VERSION ""

NS_ :

BS_:

BU_: TM

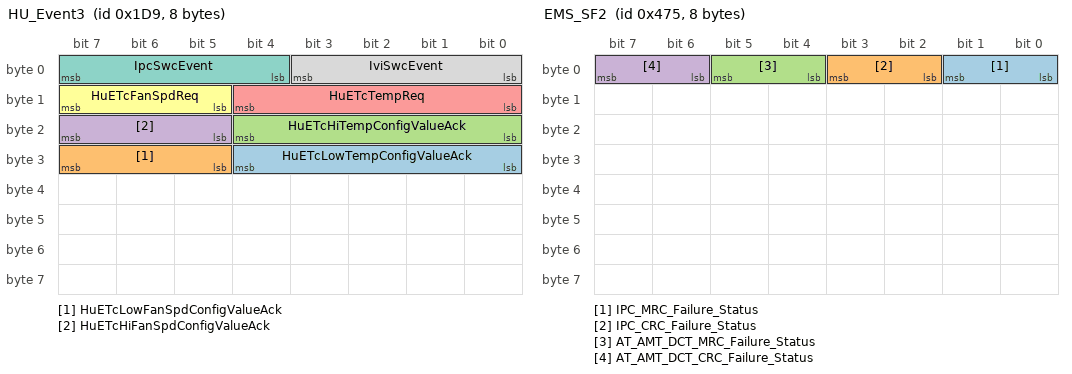
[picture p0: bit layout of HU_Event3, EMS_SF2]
BO_ 473 HU_Event3: 8 Vector__XXX
 SG_ HuETcLowTempConfigValueAck : 28|5@0+ (1,0) [0|31] ""  TM
 SG_ HuETcLowFanSpdConfigValueAck : 31|3@0+ (1,0) [0|7] ""  TM
 SG_ HuETcHiTempConfigValueAck : 20|5@0+ (1,0) [0|31] ""  TM
 SG_ HuETcHiFanSpdConfigValueAck : 23|3@0+ (1,0) [0|7] ""  TM
 SG_ HuETcTempReq : 12|5@0+ (1,0) [0|31] ""  TM
 SG_ HuETcFanSpdReq : 15|3@0+ (1,0) [0|7] ""  TM
 SG_ IpcSwcEvent : 7|4@0+ (1,0) [0|15] ""  TM
 SG_ IviSwcEvent : 3|4@0+ (1,0) [0|15] ""  TM

BO_ 1141 EMS_SF2: 8 Vector__XXX
 SG_ IPC_MRC_Failure_Status : 1|2@0+ (1,0) [0|3] ""  TM
 SG_ IPC_CRC_Failure_Status : 3|2@0+ (1,0) [0|3] ""  TM
 SG_ AT_AMT_DCT_MRC_Failure_Status : 5|2@0+ (1,0) [0|3] ""  TM
 SG_ AT_AMT_DCT_CRC_Failure_Status : 7|2@0+ (1,0) [0|3] ""  TM

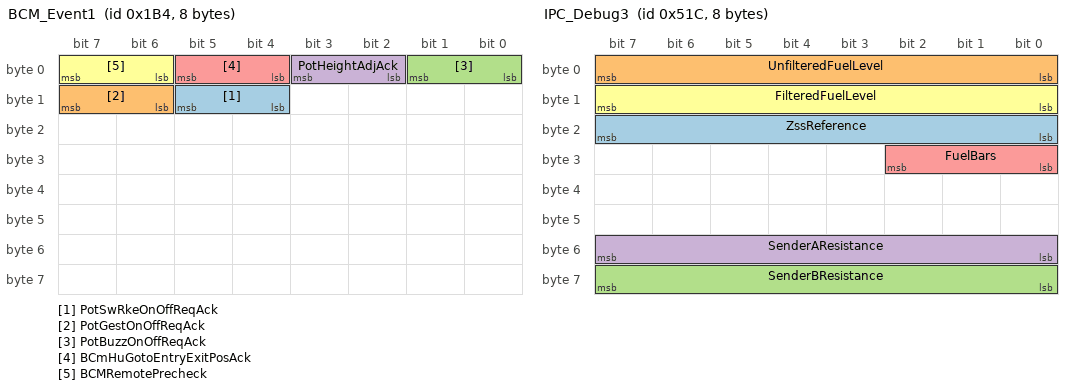
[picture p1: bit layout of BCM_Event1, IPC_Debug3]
BO_ 436 BCM_Event1: 8 Vector__XXX
 SG_ PotSwRkeOnOffReqAck : 13|2@0+ (1,0) [0|3] ""  TM
 SG_ PotGestOnOffReqAck : 15|2@0+ (1,0) [0|3] ""  TM
 SG_ PotBuzzOnOffReqAck : 1|2@0+ (1,0) [0|3] ""  TM
 SG_ PotHeightAdjAck : 3|2@0+ (1,0) [0|3] ""  TM
 SG_ BCmHuGotoEntryExitPosAck : 5|2@0+ (1,0) [0|3] ""  TM
 SG_ BCMRemotePrecheck : 7|2@0+ (1,0) [0|3] ""  TM

BO_ 1308 IPC_Debug3: 8 Vector__XXX
 SG_ ZssReference : 23|8@0+ (1,0) [0|255] "FLPS"  TM
 SG_ UnfilteredFuelLevel : 7|8@0+ (1,0) [0|255] "FLPS"  TM
 SG_ SenderBResistance : 63|8@0+ (1,0) [0|255] "Ohms"  TM
 SG_ SenderAResistance : 55|8@0+ (1,0) [0|255] "Ohms"  TM
 SG_ FuelBars : 26|3@0+ (1,0) [0|7] "NA"  TM
 SG_ FilteredFuelLevel : 15|8@0+ (1,0) [0|255] "FLPS"  TM

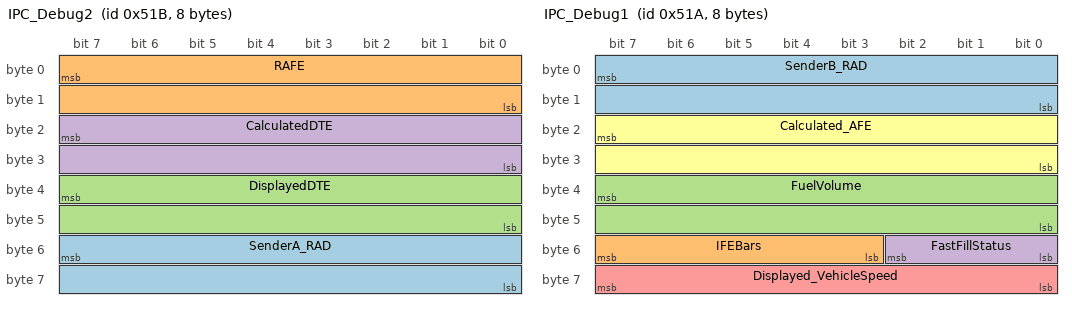
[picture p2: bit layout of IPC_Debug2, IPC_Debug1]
BO_ 1307 IPC_Debug2: 8 Vector__XXX
 SG_ SenderA_RAD : 55|16@0+ (1,0) [0|65535] "RAD"  TM
 SG_ RAFE : 7|16@0+ (0.1,0) [0|65535.5] "KM/L"  TM
 SG_ DisplayedDTE : 39|16@0+ (1,0) [0|65535] "KM"  TM
 SG_ CalculatedDTE : 23|16@0+ (1,0) [0|65535] "KM"  TM

BO_ 1306 IPC_Debug1: 8 Vector__XXX
 SG_ SenderB_RAD : 7|16@0+ (1,0) [0|65535] "RAD"  TM
 SG_ IFEBars : 55|5@0+ (1,0) [0|31] "Bars"  TM
 SG_ FuelVolume : 39|16@0+ (0.1,0) [0|65535.5] "L"  TM
 SG_ FastFillStatus : 50|3@0+ (1,0) [0|7] "Flag"  TM
 SG_ Displayed_VehicleSpeed : 63|8@0+ (1,0) [0|255] "Kmph"  TM
 SG_ Calculated_AFE : 23|16@0+ (0.1,0) [0|65535.5] "km/l"  TM

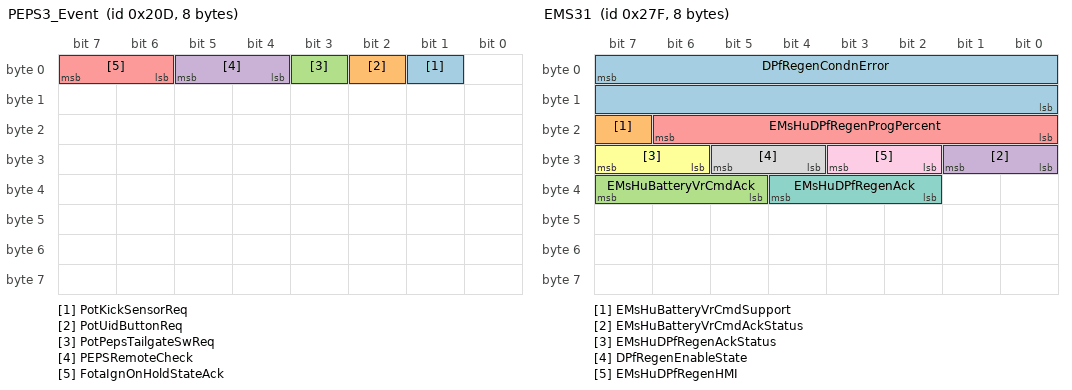
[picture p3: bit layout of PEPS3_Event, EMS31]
BO_ 525 PEPS3_Event: 8 Vector__XXX
 SG_ PotKickSensorReq : 1|1@0+ (1,0) [0|1] ""  TM
 SG_ PotUidButtonReq : 2|1@0+ (1,0) [0|1] ""  TM
 SG_ PotPepsTailgateSwReq : 3|1@0+ (1,0) [0|1] ""  TM
 SG_ PEPSRemoteCheck : 5|2@0+ (1,0) [0|3] ""  TM
 SG_ FotaIgnOnHoldStateAck : 7|2@0+ (1,0) [0|3] ""  TM

BO_ 639 EMS31: 8 Vector__XXX
 SG_ DPfRegenCondnError : 7|16@0+ (1,0) [0|16] ""  TM
 SG_ EMsHuBatteryVrCmdSupport : 23|1@0+ (1,0) [0|1] ""  TM
 SG_ EMsHuBatteryVrCmdAck : 39|3@0+ (1,0) [0|7] ""  TM
 SG_ EMsHuBatteryVrCmdAckStatus : 25|2@0+ (1,0) [0|3] ""  TM
 SG_ EMsHuDPfRegenProgPercent : 22|7@0+ (1,0) [0|100] "%"  TM
 SG_ EMsHuDPfRegenAckStatus : 31|2@0+ (1,0) [0|3] ""  TM
 SG_ EMsHuDPfRegenAck : 36|3@0+ (1,0) [0|7] ""  TM
 SG_ DPfRegenEnableState : 29|2@0+ (1,0) [0|3] ""  TM
 SG_ EMsHuDPfRegenHMI : 27|2@0+ (1,0) [0|3] ""  TM

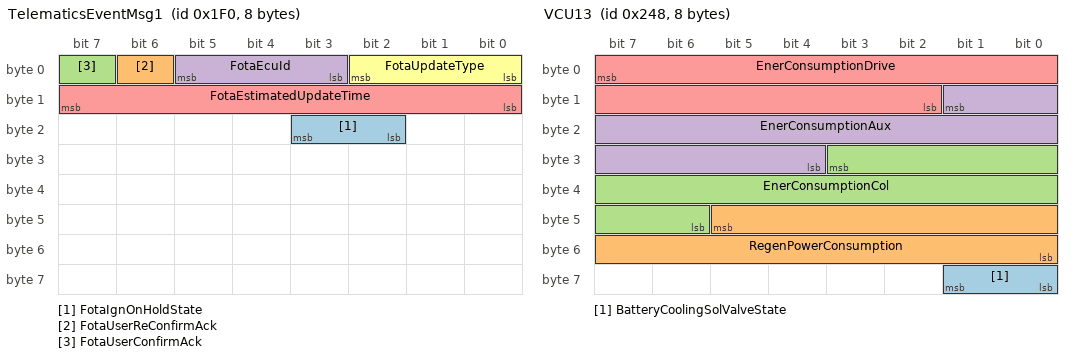
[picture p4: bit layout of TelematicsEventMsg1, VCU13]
BO_ 496 TelematicsEventMsg1: 8 TM
 SG_ FotaIgnOnHoldState : 19|2@0+ (1,0) [0|3] "" Vector__XXX
 SG_ FotaUserReConfirmAck : 6|1@0+ (1,0) [0|1] "" Vector__XXX
 SG_ FotaUserConfirmAck : 7|1@0+ (1,0) [0|1] "" Vector__XXX
 SG_ FotaEcuId : 5|3@0+ (1,0) [0|7] "" Vector__XXX
 SG_ FotaEstimatedUpdateTime : 15|8@0+ (1,0) [0|255] "" Vector__XXX
 SG_ FotaUpdateType : 2|3@0+ (1,0) [0|7] "" Vector__XXX

BO_ 1123 Telematics_TP: 8 TM
 SG_ TcmHuVoiceCommandData : 7|64@0+ (1,0) [0|0] "" Vector__XXX

BO_ 1122 HU_TP: 8 Vector__XXX
 SG_ HuTcmVoiceCommandDataAck : 7|64@0+ (1,0) [0|0] ""  TM

BO_ 584 VCU13: 8 Vector__XXX
 SG_ BatteryCoolingSolValveState : 57|2@0+ (1,0) [0|3] ""  TM
 SG_ RegenPowerConsumption : 45|14@0+ (0.01,0) [0|150] ""  TM
 SG_ EnerConsumptionCol : 27|14@0+ (0.01,0) [0|150] ""  TM
 SG_ EnerConsumptionAux : 9|14@0+ (0.01,0) [0|150] ""  TM
 SG_ EnerConsumptionDrive : 7|14@0+ (0.01,0) [0|150] ""  TM

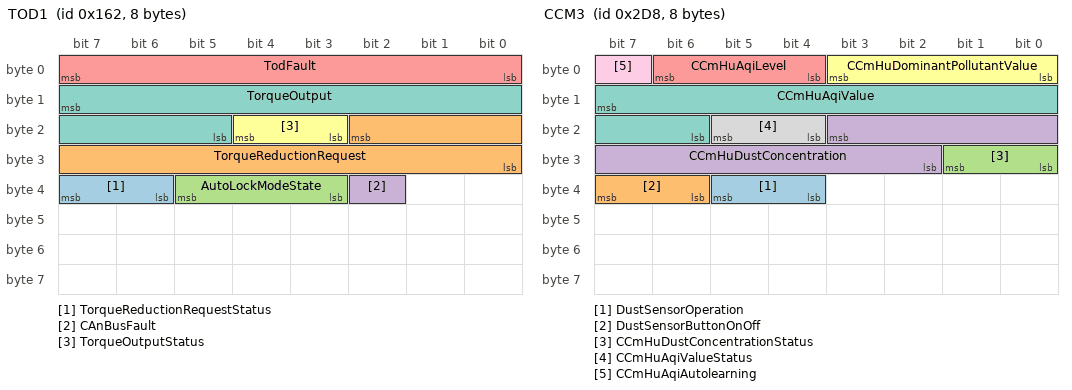
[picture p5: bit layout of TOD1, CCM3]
BO_ 354 TOD1: 8 Vector__XXX
 SG_ TorqueReductionRequestStatus : 39|2@0+ (1,0) [0|3] ""  TM
 SG_ TorqueReductionRequest : 18|11@0+ (1,0) [0|2047] "Nm"  TM
 SG_ AutoLockModeState : 37|3@0+ (1,0) [0|7] ""  TM
 SG_ CAnBusFault : 34|1@0+ (1,0) [0|1] ""  TM
 SG_ TodFault : 7|8@0+ (1,0) [0|255] ""  TM
 SG_ TorqueOutputStatus : 20|2@0+ (1,0) [0|3] ""  TM
 SG_ TorqueOutput : 15|11@0+ (1,0) [0|2047] "Nm"  TM

BO_ 1592 GSS_DiagResponse_UUDT: 8 Vector__XXX
 SG_ GSS_DiagResponse_UUDT : 7|64@0+ (1,0) [0|0] ""  TM

BO_ 1848 GSS_DiagResponse_USDT: 8 Vector__XXX
 SG_ GSS_DiagResponse_USDT : 7|64@0+ (1,0) [0|0] ""  TM

BO_ 1840 GSS_DiagRequest: 8 Vector__XXX
 SG_ GSS_DiagRequest : 7|64@0+ (1,0) [0|0] ""  TM

BO_ 728 CCM3: 8 Vector__XXX
 SG_ DustSensorOperation : 37|2@0+ (1,0) [0|3] ""  TM
 SG_ DustSensorButtonOnOff : 39|2@0+ (1,0) [0|3] ""  TM
 SG_ CCmHuDustConcentrationStatus : 25|2@0+ (1,0) [0|3] ""  TM
 SG_ CCmHuDustConcentration : 19|10@0+ (1,0) [0|1023] ""  TM
 SG_ CCmHuAqiLevel : 6|3@0+ (1,0) [0|7] ""  TM
 SG_ CCmHuDominantPollutantValue : 3|4@0+ (1,0) [0|15] ""  TM
 SG_ CCmHuAqiValue : 15|10@0+ (1,0) [0|1023] ""  TM
 SG_ CCmHuAqiValueStatus : 21|2@0+ (1,0) [0|3] ""  TM
 SG_ CCmHuAqiAutolearning : 7|1@0+ (1,0) [0|1] ""  TM

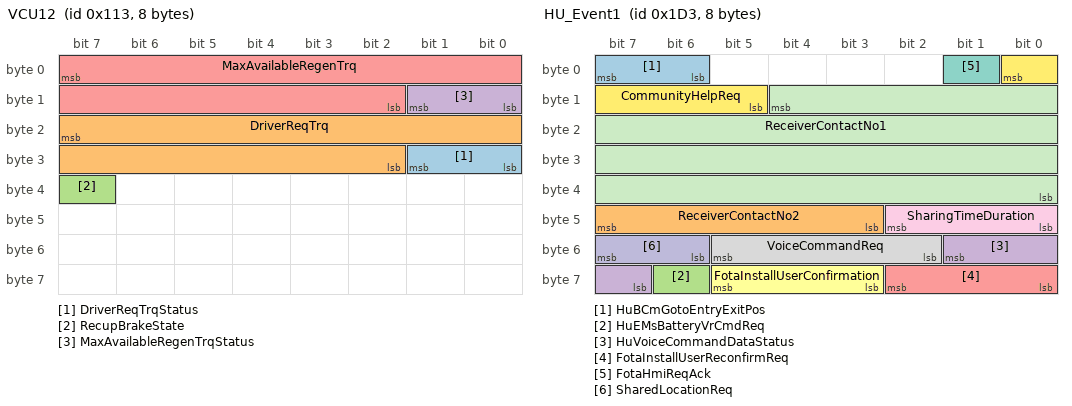
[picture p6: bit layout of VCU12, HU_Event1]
BO_ 275 VCU12: 8 Vector__XXX
 SG_ DriverReqTrqStatus : 25|2@0+ (1,0) [0|3] ""  TM
 SG_ DriverReqTrq : 23|14@0+ (0.25,-2048) [-2048|2047.75] ""  TM
 SG_ RecupBrakeState : 39|1@0+ (1,0) [0|1] ""  TM
 SG_ MaxAvailableRegenTrqStatus : 9|2@0+ (1,0) [0|3] ""  TM
 SG_ MaxAvailableRegenTrq : 7|14@0+ (0.25,-2048) [-2048|2047.75] ""  TM

BO_ 736 Remote_Feature1: 8 Vector__XXX
 SG_ VehicleMobilizationStateStatus : 7|2@0+ (1,0) [0|3] ""  TM
 SG_ VehicleMobilizationState : 5|2@0+ (1,0) [0|3] ""  TM

BO_ 467 HU_Event1: 8 Vector__XXX
 SG_ HuBCmGotoEntryExitPos : 7|2@0+ (1,0) [0|3] ""  TM
 SG_ ReceiverContactNo2 : 47|5@0+ (1,0) [0|31] ""  TM
 SG_ HuEMsBatteryVrCmdReq : 62|1@0+ (1,0) [0|1] ""  TM
 SG_ HuVoiceCommandDataStatus : 49|3@0+ (1,0) [0|7] ""  TM
 SG_ FotaInstallUserReconfirmReq : 58|3@0+ (1,0) [0|7] ""  TM
 SG_ FotaInstallUserConfirmation : 61|3@0+ (1,0) [0|7] ""  TM
 SG_ FotaHmiReqAck : 1|1@0+ (1,0) [0|1] ""  TM
 SG_ VoiceCommandReq : 53|4@0+ (1,0) [0|15] ""  TM
 SG_ SharingTimeDuration : 42|3@0+ (1,0) [0|7] ""  TM
 SG_ SharedLocationReq : 55|2@0+ (1,0) [0|3] ""  TM
 SG_ ReceiverContactNo1 : 12|29@0+ (1,0) [0|536870911] ""  TM
 SG_ CommunityHelpReq : 0|4@0+ (1,0) [0|15] ""  TM

BO_ 583 VCU10_RC: 8 Vector__XXX
 SG_ CruiseSwitchStateVCUStatus : 1|2@0+ (1,0) [0|3] ""  TM
 SG_ CruiseSwitchStateVCU : 3|2@0+ (1,0) [0|3] ""  TM
 SG_ VcuModeSelectionChangeTxt : 53|2@0+ (1,0) [0|3] ""  TM
 SG_ ModeForDisplayVCUStatus : 47|2@0+ (1,0) [0|3] ""  TM
 SG_ ModeForDisplayVCU : 37|3@0+ (1,0) [0|7] ""  TM
 SG_ ModeSelectionSwStateVCUStatus : 16|3@0+ (1,0) [0|7] ""  TM
 SG_ ModeSelectionSwStateVCU : 29|3@0+ (1,0) [0|7] ""  TM
 SG_ VcuRegenSelectionChangeTxt : 55|2@0+ (1,0) [0|3] ""  TM
 SG_ RegenForDisplayVCUStatus : 45|2@0+ (1,0) [0|3] ""  TM
 SG_ RegenForDisplayVCU : 34|3@0+ (1,0) [0|7] ""  TM
 SG_ VcuCruiseSelectionChangeTxt : 43|4@0+ (1,0) [0|15] ""  TM
 SG_ DesiredCruiseSpeedStatus : 49|2@0+ (1,0) [0|3] ""  TM
 SG_ DesiredCruiseSpeed : 63|8@0+ (1,0) [0|255] ""  TM
 SG_ VCuCruiseStateStatus : 39|2@0+ (1,0) [0|3] ""  TM
 SG_ VCuCruiseState : 26|3@0+ (1,0) [0|7] ""  TM
 SG_ HvBattFullChargeStatus : 7|2@0+ (1,0) [0|3] ""  TM
 SG_ HvBattFullCharge : 5|1@0+ (1,0) [0|1] ""  TM

BO_ 741 Telematics1: 8 TM
 SG_ RemoteAcPvTempSetStatus : 57|2@0+ (1,0) [0|3] "" Vector__XXX
 SG_ RemoteAcPvTempSet : 62|5@0+ (1,0) [0|31] "" Vector__XXX
 SG_ VehicleChargingStateTCM : 48|2@0+ (1,0) [0|3] "" Vector__XXX
 SG_ RemoteEngAcCmdStatus : 50|2@0+ (1,0) [0|3] "" Vector__XXX
 SG_ RemoteEngAcCmd : 52|2@0+ (1,0) [0|3] "" Vector__XXX
 SG_ TCmPresence : 53|1@0+ (1,0) [0|1] "" Vector__XXX
 SG_ VcuFotaUpdateState : 41|2@0+ (1,0) [0|3] "" Vector__XXX
 SG_ FatcFotaUpdateState : 43|2@0+ (1,0) [0|3] "" Vector__XXX
 SG_ BcmFotaUpdateState : 55|2@0+ (1,0) [0|3] "" Vector__XXX
 SG_ FotaUpdateEcuProgressPercen : 31|8@0+ (1,0) [0|100] "%" Vector__XXX
 SG_ FotaUpdateOverallProgressPercen : 39|8@0+ (1,0) [0|100] "%" Vector__XXX
 SG_ ParkBrkStateTcm : 17|2@0+ (1,0) [0|3] "" Vector__XXX
 SG_ GearPosStateTcm : 11|2@0+ (1,0) [0|3] "" Vector__XXX
 SG_ LvBattVoltStateTcm : 19|2@0+ (1,0) [0|3] "" Vector__XXX
 SG_ EngRpmStateTcm : 21|2@0+ (1,0) [0|3] "" Vector__XXX
 SG_ VehSpdStateTcm : 9|2@0+ (1,0) [0|3] "" Vector__XXX
 SG_ IgnStateTcm : 23|2@0+ (1,0) [0|3] "" Vector__XXX
 SG_ AccPedalPosStateTcm : 13|2@0+ (1,0) [0|3] "" Vector__XXX
 SG_ FotaUpdateState : 47|4@0+ (1,0) [0|15] "" Vector__XXX
 SG_ ShareMyLocationFeaturePresence : 14|1@0+ (1,0) [0|1] "" Vector__XXX
 SG_ iCallFeaturePresence : 1|1@0+ (1,0) [0|1] "" Vector__XXX
 SG_ eCallFeaturePresence : 2|1@0+ (1,0) [0|1] "" Vector__XXX
 SG_ CvpVoiceCmdFeaturePresence : 15|1@0+ (1,0) [0|1] "" Vector__XXX
 SG_ CommunityHelpFeaturePresence : 0|1@0+ (1,0) [0|1] "" Vector__XXX
 SG_ CallType : 5|2@0+ (1,0) [0|3] "" Vector__XXX
 SG_ CallState : 7|2@0+ (1,0) [0|3] "" Vector__XXX
 SG_ bCallFeaturePresence : 3|1@0+ (1,0) [0|1] "" Vector__XXX

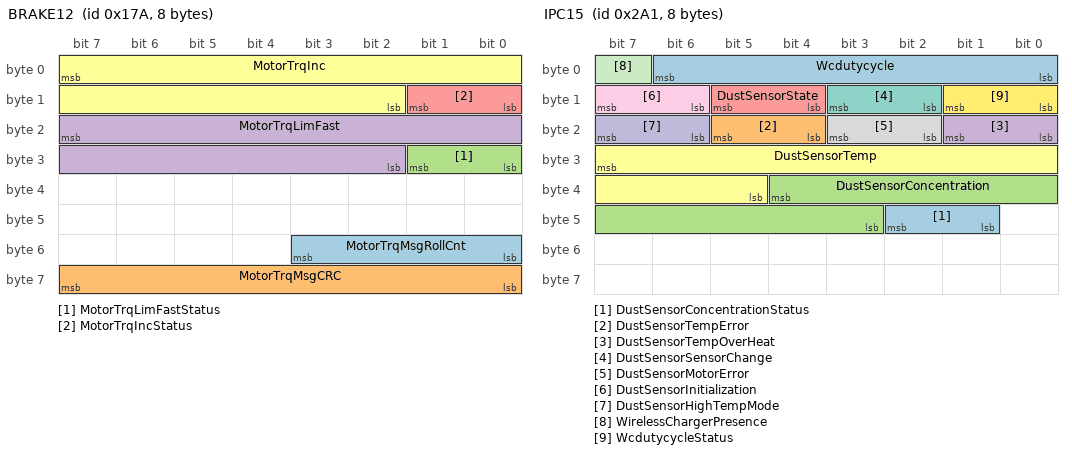
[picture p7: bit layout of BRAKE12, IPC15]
BO_ 378 BRAKE12: 8 Vector__XXX
 SG_ MotorTrqMsgRollCnt : 51|4@0+ (1,0) [0|15] ""  TM
 SG_ MotorTrqMsgCRC : 63|8@0+ (1,0) [0|255] ""  TM
 SG_ MotorTrqLimFastStatus : 25|2@0+ (1,0) [0|3] ""  TM
 SG_ MotorTrqLimFast : 23|14@0+ (0.1,-500) [-500|500] "Nm"  TM
 SG_ MotorTrqIncStatus : 9|2@0+ (1,0) [0|3] ""  TM
 SG_ MotorTrqInc : 7|14@0+ (0.1,-500) [-500|500] "Nm"  TM

BO_ 673 IPC15: 8 Vector__XXX
 SG_ DustSensorConcentrationStatus : 42|2@0+ (1,0) [0|3] ""  TM
 SG_ DustSensorTempError : 21|2@0+ (1,0) [0|3] ""  TM
 SG_ DustSensorConcentration : 36|10@0+ (1,0) [0|1023] ""  TM
 SG_ DustSensorTempOverHeat : 17|2@0+ (1,0) [0|3] ""  TM
 SG_ DustSensorState : 13|2@0+ (1,0) [0|3] ""  TM
 SG_ DustSensorTemp : 31|11@0+ (0.1,-40) [-40|164.7] ""  TM
 SG_ DustSensorSensorChange : 11|2@0+ (1,0) [0|3] ""  TM
 SG_ DustSensorMotorError : 19|2@0+ (1,0) [0|3] ""  TM
 SG_ DustSensorInitialization : 15|2@0+ (1,0) [0|3] ""  TM
 SG_ DustSensorHighTempMode : 23|2@0+ (1,0) [0|3] ""  TM
 SG_ WirelessChargerPresence : 7|1@0+ (1,0) [0|1] ""  TM
 SG_ WcdutycycleStatus : 9|2@0+ (1,0) [0|3] ""  TM
 SG_ Wcdutycycle : 6|7@0+ (1,0) [0|100] "%"  TM

BO_ 491 HU_VrCmd_SupportAck: 8 Vector__XXX
 SG_ HuBCmWindowWindingHmiCmdSupportA : 23|1@0+ (1,0) [0|1] ""  TM
 SG_ HuBCmTyreTempVrCmdSupportAck : 8|1@0+ (1,0) [0|1] ""  TM
 SG_ HuBCmTyreTempHmiCmdSupportAck : 9|1@0+ (1,0) [0|1] ""  TM
 SG_ HuBCmTyrePressureVrCmdSupportAck : 10|1@0+ (1,0) [0|1] ""  TM
 SG_ HuBCmTyrePressureHmiCmdSupportAc : 11|1@0+ (1,0) [0|1] ""  TM
 SG_ HuBCmSunroofTiltVrCmdSupportAck : 12|1@0+ (1,0) [0|1] ""  TM
 SG_ HuBCmRoofLampVrCmdSupportAck : 13|1@0+ (1,0) [0|1] ""  TM
 SG_ HuBCmRoofLampHmiCmdSupportAck : 14|1@0+ (1,0) [0|1] ""  TM
 SG_ HuBCmPositionLampVrCmdSupportAck : 15|1@0+ (1,0) [0|1] ""  TM
 SG_ HuBCmORVMVrCmdSupportAck : 2|1@0+ (1,0) [0|1] ""  TM
 SG_ HuBCmORVMHmiCmdSupportAck : 3|1@0+ (1,0) [0|1] ""  TM
 SG_ HuBCmMoodLightVrCmdSupportAck : 4|1@0+ (1,0) [0|1] ""  TM
 SG_ HuBCmHazardLampVrCmdSupportAck : 5|1@0+ (1,0) [0|1] ""  TM
 SG_ HuBCmDRLVrCmdSupportAck : 6|1@0+ (1,0) [0|1] ""  TM
 SG_ HuBCmAmbientLightVrCmdSupportAck : 7|1@0+ (1,0) [0|1] ""  TM
 SG_ HuBCmSunShadeVrCmdSupportAck : 1|1@0+ (1,0) [0|1] ""  TM
 SG_ HuBCmSunRoofVrCmdSupportAck : 0|1@0+ (1,0) [0|1] ""  TM

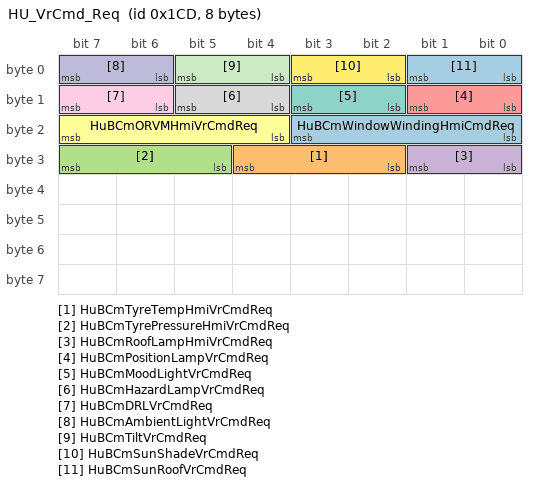
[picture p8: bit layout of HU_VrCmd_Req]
BO_ 461 HU_VrCmd_Req: 8 Vector__XXX
 SG_ HuBCmWindowWindingHmiCmdReq : 19|4@0+ (1,0) [0|15] ""  TM
 SG_ HuBCmTyreTempHmiVrCmdReq : 28|3@0+ (1,0) [0|7] ""  TM
 SG_ HuBCmTyrePressureHmiVrCmdReq : 31|3@0+ (1,0) [0|7] ""  TM
 SG_ HuBCmRoofLampHmiVrCmdReq : 25|2@0+ (1,0) [0|3] ""  TM
 SG_ HuBCmPositionLampVrCmdReq : 9|2@0+ (1,0) [0|3] ""  TM
 SG_ HuBCmORVMHmiVrCmdReq : 23|4@0+ (1,0) [0|15] ""  TM
 SG_ HuBCmMoodLightVrCmdReq : 11|2@0+ (1,0) [0|3] ""  TM
 SG_ HuBCmHazardLampVrCmdReq : 13|2@0+ (1,0) [0|3] ""  TM
 SG_ HuBCmDRLVrCmdReq : 15|2@0+ (1,0) [0|3] ""  TM
 SG_ HuBCmAmbientLightVrCmdReq : 7|2@0+ (1,0) [0|3] ""  TM
 SG_ HuBCmTiltVrCmdReq : 5|2@0+ (1,0) [0|3] ""  TM
 SG_ HuBCmSunShadeVrCmdReq : 3|2@0+ (1,0) [0|3] ""  TM
 SG_ HuBCmSunRoofVrCmdReq : 1|2@0+ (1,0) [0|3] ""  TM

BO_ 489 BCM_VrCmd_Support: 8 Vector__XXX
 SG_ BCmHuWindowWindingHmiCmdSupport : 23|1@0+ (1,0) [0|1] ""  TM
 SG_ BCmHuTyreTempVrCmdSupport : 8|1@0+ (1,0) [0|1] ""  TM
 SG_ BCmHuTyreTempHmiCmdSupport : 9|1@0+ (1,0) [0|1] ""  TM
 SG_ BCmHuTyrePressureVrCmdSupport : 10|1@0+ (1,0) [0|1] ""  TM
 SG_ BCmHuTyrePressureHmiCmdSupport : 11|1@0+ (1,0) [0|1] ""  TM
 SG_ BCmHuSunroofTiltVrCmdSupport : 12|1@0+ (1,0) [0|1] ""  TM
 SG_ BCmHuRoofLampVrCmdSupport : 13|1@0+ (1,0) [0|1] ""  TM
 SG_ BCmHuRoofLampHmiCmdSupport : 14|1@0+ (1,0) [0|1] ""  TM
 SG_ BCmHuPositionLampVrCmdSupport : 15|1@0+ (1,0) [0|1] ""  TM
 SG_ BCmHuORVMVrCmdSupport : 2|1@0+ (1,0) [0|1] ""  TM
 SG_ BCmHuORVMHmiCmdSupport : 3|1@0+ (1,0) [0|1] ""  TM
 SG_ BCmHuMoodLightVrCmdSupport : 4|1@0+ (1,0) [0|1] ""  TM
 SG_ BCmHuHazardLampVrCmdSupport : 5|1@0+ (1,0) [0|1] ""  TM
 SG_ BCmHuDRLVrCmdSupport : 6|1@0+ (1,0) [0|1] ""  TM
 SG_ BCmHuAmbientLightVrCmdSupport : 7|1@0+ (1,0) [0|1] ""  TM
 SG_ BCmHuSunShadeVrCmdSupport : 1|1@0+ (1,0) [0|1] ""  TM
 SG_ BCmHuSunRoofVrCmdSupport : 0|1@0+ (1,0) [0|1] ""  TM

CM_ SG_ 473 HuETcLowTempConfigValueAck "Acknowledge  the lower configuration set Temperature value for the ETC ECU under consideration";
CM_ SG_ 473 HuETcLowFanSpdConfigValueAck "Acknowledge  the lower configuration fan speed value for the ETC ECU under consideration";
CM_ SG_ 473 HuETcHiTempConfigValueAck "Acknowledge  the higher configuration set Temperature value for the ETC ECU under consideration";
CM_ SG_ 473 HuETcHiFanSpdConfigValueAck "Acknowledge  the higher configuration fan speed value for the ETC ECU under consideration";
CM_ SG_ 473 HuETcTempReq "Indicates the Set temperature value from HU in Levels";
CM_ SG_ 473 HuETcFanSpdReq "Indicates the Fan spped request value from HU in Levels";
CM_ SG_ 473 IpcSwcEvent "LinSwcIc shall publish its variant type to all partner ECUs.";
CM_ SG_ 473 IviSwcEvent "LinSwcIc shall publish its variant type to all partner ECUs.";
CM_ BO_ 1141 "Supervision frame transmitted by EMS.";
CM_ SG_ 1141 IPC_MRC_Failure_Status "Status of the message rolling counter failure detected by EMS ECU as per communication layer spec";
CM_ SG_ 1141 IPC_CRC_Failure_Status "Status of the cyclic reduntancy failure detected by EMS ECU as per communication layer spec.";
CM_ SG_ 1141 AT_AMT_DCT_MRC_Failure_Status "Status of the message rolling counter failure detected by EMS ECU as per communication layer spec";
CM_ SG_ 1141 AT_AMT_DCT_CRC_Failure_Status "Status of the cyclic reduntancy failure detected by EMS ECU as per communication layer spec.";
CM_ SG_ 436 PotSwRkeOnOffReqAck "ACK BCM to HU for POT open/close by RKE switch enable/ disable user req";
CM_ SG_ 436 PotGestOnOffReqAck "ACK BCM to HU for POT open/close by gesture enable/ disable user req";
CM_ SG_ 436 PotBuzzOnOffReqAck "ACK BCM to HU for POT buzzer of open/close action enable/ disable user req";
CM_ SG_ 436 PotHeightAdjAck "BCM Ack for POT height adj from HU";
CM_ SG_ 436 BCmHuGotoEntryExitPosAck "BCM Ack for Easy Entry/Exit Enable or Disable from HU";
CM_ SG_ 436 BCMRemotePrecheck "BCM shall publish the  door status to TCM & PEPS";
CM_ SG_ 525 PotKickSensorReq "Power Tailgate Open/Close request from Kick Sensor";
CM_ SG_ 525 PotUidButtonReq "Power Tailgate Open/Close request from UID Button";
CM_ SG_ 525 PotPepsTailgateSwReq "Power Tailgate Open/Close request from PEPS Tailgate Switch";
CM_ SG_ 525 PEPSRemoteCheck "PEPS shall publish  precheck status to TCM";
CM_ SG_ 525 FotaIgnOnHoldStateAck "Acknowledgement Signal from PEPS to TCM for confirming the reception of  the FotaIgnOnHoldState signal  ";
CM_ SG_ 639 DPfRegenCondnError "This information is transmitted by EMS to HU to notify the error / interupts causing pre-condition check failure or DPF regeneration process abortion.
Refer Functional Description Document for Bit Encoded Value.";
CM_ SG_ 639 EMsHuBatteryVrCmdSupport "This signal is used to indicate whether EMS supports voice recognition feature related to battery parameters.";
CM_ SG_ 639 EMsHuBatteryVrCmdAck "This information is used to request battery status via VR command.This information is used to send acknowledgement for battery status request via VR command.";
CM_ SG_ 639 EMsHuBatteryVrCmdAckStatus "This signal is used to indicate plausibility of batetry status acknowledgement signal.";
CM_ SG_ 639 EMsHuDPfRegenProgPercent "The information is sent from EMS to HU to display the progress percentage & progress Bar for DPF regeneration process.";
CM_ SG_ 639 EMsHuDPfRegenAckStatus "This signal is used to indicate plausibility status of DPF regeneration acknowldgement signal.";
CM_ SG_ 639 EMsHuDPfRegenAck "This signal is used to indicate the response / acknowledgement from EMS for DPF regeneration request.";
CM_ SG_ 639 DPfRegenEnableState "This signal is used by HU to push notification on HMI for DPF regeneration.";
CM_ SG_ 639 EMsHuDPfRegenHMI "This signal is used to indicate whether EMS supports  DPF regeneration through HMI or Not";
CM_ SG_ 496 FotaIgnOnHoldState "Signal  from TCM to PEPS for requesting to hold Ignition in ON state";
CM_ SG_ 496 FotaUserReConfirmAck "Acknowledgement signal to HU to intimate that TCU has received the FOTA user re-confirmation signal that it has sent";
CM_ SG_ 496 FotaUserConfirmAck "Acknowledgement signal to HU to intimate that TCU has received the FOTA user confirmation signal that it has sent";
CM_ SG_ 496 FotaEcuId "This signal shall be published by TCU to indicate the ID of the ECUfo which the upgrade or installation is planned";
CM_ SG_ 496 FotaEstimatedUpdateTime "This signal shall be published by TCU to indicate approximate estimated time for installatioon of new firmware";
CM_ SG_ 496 FotaUpdateType "This signal shall be published by TCU to indicate the FOTA Update Type of the new firnware to be installed";
CM_ BO_ 1123 "Telematics CAN TP Message";
CM_ BO_ 1122 "HU CAN TP Message";
CM_ SG_ 584 BatteryCoolingSolValveState "Battery Cooling Solenoid Valve Signal";
CM_ SG_ 584 RegenPowerConsumption "Regen Power Consumption";
CM_ SG_ 584 EnerConsumptionCol "Energy Consumption Cooling";
CM_ SG_ 584 EnerConsumptionAux "Energy Consumption Auxilary";
CM_ SG_ 584 EnerConsumptionDrive "Energy Consumption Drive ";
CM_ SG_ 354 TorqueReductionRequestStatus "Status of torque reduction request  to engine";
CM_ SG_ 354 TorqueReductionRequest "Torque reduction request  to engine";
CM_ SG_ 354 AutoLockModeState "AUTO Or LOCK Mode status over CAN (to IC )";
CM_ SG_ 354 CAnBusFault "Indication in case of malfunction over CAN (to IC)";
CM_ SG_ 354 TodFault "Internal Fault Code";
CM_ SG_ 354 TorqueOutputStatus "Output torque from NexTrac status";
CM_ SG_ 354 TorqueOutput "Output torque from NexTrac";
CM_ SG_ 728 DustSensorOperation "Sensor operation permission signal by FATC.";
CM_ SG_ 728 DustSensorButtonOnOff "This signal is used to make Sensor on and OFF by FATC";
CM_ SG_ 728 CCmHuDustConcentrationStatus "Satus for Dust Concentration.";
CM_ SG_ 728 CCmHuDustConcentration "Dust concentration signal is used to measure the concentration level in ug/m3_ PM2.5 Value";
CM_ SG_ 728 CCmHuAqiLevel "AQI Level – used for color indication w.r.t  AQI_Based on Value AQI value the color codes to be assigned. AQI Value to be mapped with respective colour codes.";
CM_ SG_ 728 CCmHuDominantPollutantValue "This value express the concentration of major pollutant inside the cabin";
CM_ SG_ 728 CCmHuAqiValue "AQI value information";
CM_ SG_ 728 CCmHuAqiValueStatus "Plausibility Satus for CCmHuAQIValue";
CM_ SG_ 728 CCmHuAqiAutolearning "This signal will be used by HU to determine whether said feature is available or not";
CM_ SG_ 275 DriverReqTrqStatus "Driver requested torque status";
CM_ SG_ 275 DriverReqTrq "Driver requested torque";
CM_ SG_ 275 RecupBrakeState "Recupration brake Enable Flag";
CM_ SG_ 275 MaxAvailableRegenTrqStatus "Status information of MaxAvailableRegenTrq Signal";
CM_ SG_ 275 MaxAvailableRegenTrq "Actual available regen torque at VCU";
CM_ SG_ 736 VehicleMobilizationStateStatus "Status of the VehicleMobilizationState signal";
CM_ SG_ 736 VehicleMobilizationState "Vehicle Mobilization and immobilization  response to prevent vehicle crank";
CM_ SG_ 467 HuBCmGotoEntryExitPos "Easy Entry Exit function User request to Enable or Disable Feature";
CM_ SG_ 467 ReceiverContactNo2 "Signal for receiver contact number";
CM_ SG_ 467 HuEMsBatteryVrCmdReq "This information is used to request battery status via VR command.";
CM_ SG_ 467 HuVoiceCommandDataStatus "Voice command data status from HU to TCM";
CM_ SG_ 467 FotaInstallUserReconfirmReq "Signal containing the FOTA re-installation user confirmation input ";
CM_ SG_ 467 FotaInstallUserConfirmation "Signal containing the FOTA installation user confirmation input ";
CM_ SG_ 467 FotaHmiReqAck "Acknowledgement signal to TCU to intimate that HU has received the FOTA update type, estimated time and ECU ID signals that it has sent";
CM_ SG_ 467 VoiceCommandReq "Voice command Request from HU to TCM";
CM_ SG_ 467 SharingTimeDuration "Signal from Community Help receviers's TCM to receiver's HU to inform  the Community help request to Receiver.";
CM_ SG_ 467 SharedLocationReq "Signal from HU to TCM for Share My Location request";
CM_ SG_ 467 ReceiverContactNo1 "Signal for receiver contact number";
CM_ SG_ 467 CommunityHelpReq "Signal from Community Help sender's HU to sender's TCM to generate  the Community help request on platform.";
CM_ SG_ 583 CruiseSwitchStateVCUStatus "CruiseSwitchstate Signal status information";
CM_ SG_ 583 CruiseSwitchStateVCU "Resume and Set Cruise Switches stateinformation to support HDC function";
CM_ SG_ 583 VcuModeSelectionChangeTxt "Signal on CAN to IPC for possibility of user requested change status.";
CM_ SG_ 583 ModeForDisplayVCUStatus "Plausibility Status of ModeForDisplayVCU";
CM_ SG_ 583 ModeForDisplayVCU "Mode Selection Switch signal (Validated User request) is published by VCU for response Mode Selection";
CM_ SG_ 583 ModeSelectionSwStateVCUStatus "Plausibility Status of ModeSelectionSwState";
CM_ SG_ 583 ModeSelectionSwStateVCU "Mode Selection Display signal is published by VCU for ESP confirmation of Mode Selection request from user";
CM_ SG_ 583 VcuRegenSelectionChangeTxt "This function indicates Regen Level Selection Cluster Indication";
CM_ SG_ 583 RegenForDisplayVCUStatus "Plausibility Status of Regen Level Display on cluster";
CM_ SG_ 583 RegenForDisplayVCU "Regen Level Display on cluster";
CM_ SG_ 583 VcuCruiseSelectionChangeTxt "This function indicates Cruise Selection Cluster Indication";
CM_ SG_ 583 DesiredCruiseSpeedStatus "It indicate the cruise info status";
CM_ SG_ 583 DesiredCruiseSpeed "This information is used   to indicate the speed limit values in display";
CM_ SG_ 583 VCuCruiseStateStatus "status information to CruiseState";
CM_ SG_ 583 VCuCruiseState "Cruise control active / Cruise control failed";
CM_ SG_ 583 HvBattFullChargeStatus "Status of the HV Battery Full Charge alert";
CM_ SG_ 583 HvBattFullCharge "HV Battery Full Charge alert";
CM_ SG_ 741 RemoteAcPvTempSetStatus "Status of the RemoteAcPvTempSet signal as published by TCU.";
CM_ SG_ 741 RemoteAcPvTempSet "Set temperature value from TCU to FATC for in-cabin climate control.";
CM_ SG_ 741 VehicleChargingStateTCM "The signal shall be published by the TCU to intimate HU to indicate whether the Charging state is in safe condition (Not charging) in the display";
CM_ SG_ 741 RemoteEngAcCmdStatus "This signal gives status of RemoteEngAcCmdStatus signal.";
CM_ SG_ 741 RemoteEngAcCmd "After waking up ESCL by PEPS, TCM should send RemoteEngAcCmd on CAN (Cyclic) to BCM, PEPS, IPC, & FATC.";
CM_ SG_ 741 TCmPresence "Indicates the state of the TCM presence to other ECU.";
CM_ SG_ 741 VcuFotaUpdateState "Signal Indicating the current FOTA Update State of VCU from TCM to HU";
CM_ SG_ 741 FatcFotaUpdateState "Signal Indicating the current FOTA Update State of FATC from TCM to HU";
CM_ SG_ 741 BcmFotaUpdateState "Signal Indicating the current FOTA Update State of BCM from TCM to HU";
CM_ SG_ 741 FotaUpdateEcuProgressPercen "Signal with percentage completion value of the FOTA Update of current ECU from TCM to HU";
CM_ SG_ 741 FotaUpdateOverallProgressPercen "Signal with overall percentage completion value of the FOTA update from TCM to HU";
CM_ SG_ 741 ParkBrkStateTcm "The signal shall be published by the TCU to intimate HU to indicate whether the ParkBrake status is in safe condition in the display";
CM_ SG_ 741 GearPosStateTcm "The signal shall be published by the TCU to intimate HU to indicate whether the Gear Position status is in safe condition (Neutral - 3) in the display";
CM_ SG_ 741 LvBattVoltStateTcm "The signal shall be published by the TCU to intimate HU to indicate whether the current LV battery voltage is in safe condition (LV Battery Voltage == between 10-16V) in the display";
CM_ SG_ 741 EngRpmStateTcm "The signal shall be published by the TCU to intimate HU to indicate whether the current Engine RPM status is in safe condition (Engine RPM == 0) in the display";
CM_ SG_ 741 VehSpdStateTcm "The signal shall be published by the TCU to intimate HU to indicate whether the current Vehicle Speed  status is in safe condition (Vehicle Speed == 0) in the display";
CM_ SG_ 741 IgnStateTcm "The signal shall be published by the TCU to intimate HU to indicate whether the IGN status is in safe condition (IGN_ON) in the display";
CM_ SG_ 741 AccPedalPosStateTcm "The signal shall be published by the TCU to intimate HU to indicate whether the Accelerator Pedal Position is in safe condition (0%) in the display";
CM_ SG_ 741 FotaUpdateState "This signal shall be published by TCU to indicate the current state of the FOTA installation to the corresponding ECUs in the vehicle network";
CM_ SG_ 741 ShareMyLocationFeaturePresence "Signal transmitted from TCM to HU, indicating the presence of Share My Location feature";
CM_ SG_ 741 iCallFeaturePresence "This signal is transmitted from TCM to HU, indicating that iCall feature is present or not";
CM_ SG_ 741 eCallFeaturePresence "This signal is transmitted from TCM to HU, indicating that eCall feature is present or not";
CM_ SG_ 741 CvpVoiceCmdFeaturePresence "This signal is transmitted from TCM to HU, indicating that voice recognition feature is present or not";
CM_ SG_ 741 CommunityHelpFeaturePresence "TCM to HU, indicating Community Help feature is present or not";
CM_ SG_ 741 CallType "This signal is transmitted from TCM to HU, indicating type of call";
CM_ SG_ 741 CallState "This signal is transmitted from TCM to HU, indicating  status of call";
CM_ SG_ 741 bCallFeaturePresence "This signal is transmitted from TCM to HU, indicating that bCall feature is present or not";
CM_ SG_ 378 MotorTrqMsgRollCnt "Rolling counter for the message which consists of MotorTrqInc, MototrTrqLimFast";
CM_ SG_ 378 MotorTrqMsgCRC "CRC for entire message which consists of MotorTrqInc, MototrTrqLimFast";
CM_ SG_ 378 MotorTrqLimFastStatus "status information of EngTrqLimFast
";
CM_ SG_ 378 MotorTrqLimFast "target engine torque limit (fast) in NM.
Signal will be used by VCU ECU for ESP/TCS function from ESP
";
CM_ SG_ 378 MotorTrqIncStatus "Status signal information of MotorTrqInc
";
CM_ SG_ 378 MotorTrqInc "Target Motor torque increases in Nm.
Signal will be used by VCU ECU for ESP/TCS function from  ESP
";
CM_ SG_ 673 DustSensorConcentrationStatus "Status of dust sensor concentration";
CM_ SG_ 673 DustSensorTempError "Transmit Sensor Temp error signal";
CM_ SG_ 673 DustSensorConcentration "Concentration of dust";
CM_ SG_ 673 DustSensorTempOverHeat "Transmit Sensor over-temp signal ";
CM_ SG_ 673 DustSensorState "Transmit dust Sensor state signal ";
CM_ SG_ 673 DustSensorTemp "Internal Sensor Temperature";
CM_ SG_ 673 DustSensorSensorChange "Transmit Sensor Replace signal ";
CM_ SG_ 673 DustSensorMotorError "Transmit Fan Motor error signal ";
CM_ SG_ 673 DustSensorInitialization "Transmit initialization signal of Dust Sensor ";
CM_ SG_ 673 DustSensorHighTempMode "Transmit High temp operating mode signal";
CM_ SG_ 673 WirelessChargerPresence "This signal is transmitted to HU to know wireless charger is presence in vehicle or not.";
CM_ SG_ 673 WcdutycycleStatus "This information is used to determine status of duty cycle of PWM sent by wireless charger";
CM_ SG_ 673 Wcdutycycle "This information is used to determine the duty cycle of PWM sent by wireless charger";
CM_ SG_ 491 HuBCmWindowWindingHmiCmdSupportA "Window Winding HMI support response from HU to BCM";
CM_ SG_ 491 HuBCmTyreTempVrCmdSupportAck "Tyre Temparature Voice support response from HU to BCM";
CM_ SG_ 491 HuBCmTyreTempHmiCmdSupportAck "Tyre Temparature HMI support response from HU to BCM";
CM_ SG_ 491 HuBCmTyrePressureVrCmdSupportAck "Tyre Pressure Voice support response from HU to BCM";
CM_ SG_ 491 HuBCmTyrePressureHmiCmdSupportAc "Tyre Pressure HMI support response from HU to BCM";
CM_ SG_ 491 HuBCmSunroofTiltVrCmdSupportAck "Sunroof Tilt voice support response from HU to BCM";
CM_ SG_ 491 HuBCmRoofLampVrCmdSupportAck "Roof Lamp Voice support response from HU to BCM";
CM_ SG_ 491 HuBCmRoofLampHmiCmdSupportAck "Roof Lamp HMI support response from HU to BCM";
CM_ SG_ 491 HuBCmPositionLampVrCmdSupportAck "Position lamp voice support response from HU to BCM";
CM_ SG_ 491 HuBCmORVMVrCmdSupportAck "ORVM voice support response from HU to BCM";
CM_ SG_ 491 HuBCmORVMHmiCmdSupportAck "ORVM HMI support response from HU to BCM";
CM_ SG_ 491 HuBCmMoodLightVrCmdSupportAck "Mood Light voice support response from HU to BCM";
CM_ SG_ 491 HuBCmHazardLampVrCmdSupportAck "Hazard Lamp voice support response from HU to BCM";
CM_ SG_ 491 HuBCmDRLVrCmdSupportAck "DRL voice support response from HU to BCM";
CM_ SG_ 491 HuBCmAmbientLightVrCmdSupportAck "Ambient Light voice support response from HU to BCM";
CM_ SG_ 491 HuBCmSunShadeVrCmdSupportAck "Sunshade operation support from HU to BCM";
CM_ SG_ 491 HuBCmSunRoofVrCmdSupportAck "Sunroof operation support from HU to BCM";
CM_ SG_ 461 HuBCmWindowWindingHmiCmdReq "Window Winding voice command request from HU to BCM";
CM_ SG_ 461 HuBCmTyreTempHmiVrCmdReq "Tyre Temperature HMI or voice command request from HU to BCM";
CM_ SG_ 461 HuBCmTyrePressureHmiVrCmdReq "Tyre Pressure HMI or voice command request from HU to BCM";
CM_ SG_ 461 HuBCmRoofLampHmiVrCmdReq "Roof lamp HMI or Voice command request from HU to BCM";
CM_ SG_ 461 HuBCmPositionLampVrCmdReq "Position lamp voice command request from HU to BCM";
CM_ SG_ 461 HuBCmORVMHmiVrCmdReq "ORVM HMI or Voice command request from HU to BCM";
CM_ SG_ 461 HuBCmMoodLightVrCmdReq "Mood light voice command request from HU to BCM";
CM_ SG_ 461 HuBCmHazardLampVrCmdReq "Hazard lamp voice command request from HU to BCM";
CM_ SG_ 461 HuBCmDRLVrCmdReq "DRL voice command request from HU to BCM";
CM_ SG_ 461 HuBCmAmbientLightVrCmdReq "Ambient light voice command request from HU to BCM";
CM_ SG_ 461 HuBCmTiltVrCmdReq "Sunroof Tilt voice command command request from HU to BCM";
CM_ SG_ 461 HuBCmSunShadeVrCmdReq "Sunshade voice command request from HU to BCM";
CM_ SG_ 461 HuBCmSunRoofVrCmdReq "Sunroof voice command command request from HU to BCM";
CM_ SG_ 489 BCmHuWindowWindingHmiCmdSupport "Window Winding HMI support from BCM to HU";
CM_ SG_ 489 BCmHuTyreTempVrCmdSupport "Tyre Temparature Voice support from BCM to HU";
CM_ SG_ 489 BCmHuTyreTempHmiCmdSupport "Tyre Temparature HMI support from BCM to HU";
CM_ SG_ 489 BCmHuTyrePressureVrCmdSupport "Tyre Pressure Voice support from BCM to HU";
CM_ SG_ 489 BCmHuTyrePressureHmiCmdSupport "Tyre Pressure HMI support from BCM to HU";
CM_ SG_ 489 BCmHuSunroofTiltVrCmdSupport "Sunroof Tilt voice support from BCM to HU";
CM_ SG_ 489 BCmHuRoofLampVrCmdSupport "Roof Lamp Voice support from BCM to HU";
CM_ SG_ 489 BCmHuRoofLampHmiCmdSupport "Roof Lamp HMI support from BCM to HU";
CM_ SG_ 489 BCmHuPositionLampVrCmdSupport "Position lamp voice support from BCM to HU";
CM_ SG_ 489 BCmHuORVMVrCmdSupport "ORVM Voice support from BCM to HU";
CM_ SG_ 489 BCmHuORVMHmiCmdSupport "ORVM HMI support from BCM to HU";
CM_ SG_ 489 BCmHuMoodLightVrCmdSupport "Mood Light voice support from BCM to HU";
CM_ SG_ 489 BCmHuHazardLampVrCmdSupport "Hazard Lamp voice support from BCM to HU";
CM_ SG_ 489 BCmHuDRLVrCmdSupport "DRL voice support from BCM to HU";
CM_ SG_ 489 BCmHuAmbientLightVrCmdSupport "Ambient Light voice support from BCM to HU";
CM_ SG_ 489 BCmHuSunShadeVrCmdSupport "Sunshade operation support from BCM to HU";
CM_ SG_ 489 BCmHuSunRoofVrCmdSupport "Sunroof operation support from BCM to HU";
BA_DEF_ SG_  "Remarks" STRING ;
BA_DEF_ SG_  "NWM_WakeupAllowed" ENUM  "No","Yes";
BA_DEF_ SG_  "GenSigTimeoutTime_HU_Mid_X451" INT 0 65535;
BA_DEF_ SG_  "GenSigTimeoutTime_HU_High_X451" INT 0 65535;
BA_DEF_ SG_  "GenSigTimeoutTime_HU_B" INT 0 65535;
BA_DEF_ SG_  "GenSigTimeoutTime_HU_A" INT 0 65535;
BA_DEF_ SG_  "GenSigTimeoutTime_BCM_Mid" INT 0 65535;
BA_DEF_ SG_  "GenSigTimeoutMsg_HU_Mid_X451" INT 0 65535;
BA_DEF_ SG_  "GenSigTimeoutMsg_HU_High_X451" INT 0 65535;
BA_DEF_ SG_  "GenSigTimeoutMsg_HU_B" INT 0 65535;
BA_DEF_ SG_  "GenSigTimeoutMsg_HU_A" INT 0 65535;
BA_DEF_ SG_  "GenSigStartValue" INT 0 0;
BA_DEF_ SG_  "GenSigSendType" ENUM  "Cyclic","OnWrite","OnWriteWithRepetition","OnChange","OnChangeWithRepetition","IfActive","IfActiveWithRepetition","NoSigSendType","NotUsed","NotUsed","NotUsed","NotUsed","NotUsed";
BA_DEF_ SG_  "GenSigInactiveValue" INT 0 0;
BA_DEF_ SG_  "GenSigEnvVarType" ENUM  "int","float","undef";
BA_DEF_ SG_  "GenSigCycleTimeActive" INT 0 0;
BA_DEF_ SG_  "GenSigCycleTime" INT 0 0;
BA_DEF_ SG_  "GenSigTimeoutMsg_HU_High_X445" INT 0 65535;
BA_DEF_ SG_  "GenSigTimeoutMsg_HU_Mid_X445" INT 0 65535;
BA_DEF_ SG_  "GenSigTimeoutTime_HU_High_X445" INT 0 65535;
BA_DEF_ SG_  "GenSigTimeoutTime_HU_Mid_X445" INT 0 65535;
BA_DEF_ SG_  "GenSigTimeoutMsg_IVI" INT 0 65535;
BA_DEF_ SG_  "GenSigTimeoutTime_IVI" INT 0 65535;
BA_DEF_ BO_  "NmMessage" ENUM  "no","yes";
BA_DEF_ BO_  "NmAsrMessage" ENUM  "<n.a.>","No","Yes";
BA_DEF_ BO_  "MessageTimeout" INT 0 65535;
BA_DEF_ BO_  "Me" INT 0 0;
BA_DEF_ BO_  "GenMsgStartDelayTime" INT 0 0;
BA_DEF_ BO_  "GenMsgSendType" ENUM  "Cyclic","NotUsed","NotUsed","NotUsed","NotUsed","NotUsed","NotUsed","IfActive","NoMsgSendType","NotUsed";
BA_DEF_ BO_  "GenMsgNrOfRepetition" INT 0 0;
BA_DEF_ BO_  "GenMsgILSupport" ENUM  "No","Yes";
BA_DEF_ BO_  "GenMsgDelayTime" INT 0 0;
BA_DEF_ BO_  "GenMsgCycleTimeFast" INT 0 0;
BA_DEF_ BO_  "GenMsgCycleTime" INT 0 0;
BA_DEF_ BO_  "DiagUudtResponse" ENUM  "false","true";
BA_DEF_ BO_  "DiagUsdtResponse" ENUM  "false","true";
BA_DEF_ BO_  "DiagState" ENUM  "No","Yes";
BA_DEF_ BO_  "DiagResponse" ENUM  "No","Yes";
BA_DEF_ BO_  "DiagRequest" ENUM  "No","Yes";
BA_DEF_ BO_  "MsgType" ENUM  "Application","NM","NMH";
BA_DEF_ SG_  "SystemSignalLongSymbol" STRING ;
BA_DEF_DEF_  "Remarks" "null";
BA_DEF_DEF_  "NWM_WakeupAllowed" "No";
BA_DEF_DEF_  "GenSigTimeoutTime_HU_Mid_X451" 500;
BA_DEF_DEF_  "GenSigTimeoutTime_HU_High_X451" 500;
BA_DEF_DEF_  "GenSigTimeoutTime_HU_B" 500;
BA_DEF_DEF_  "GenSigTimeoutTime_HU_A" 500;
BA_DEF_DEF_  "GenSigTimeoutTime_BCM_Mid" 0;
BA_DEF_DEF_  "GenSigTimeoutMsg_HU_Mid_X451" 500;
BA_DEF_DEF_  "GenSigTimeoutMsg_HU_High_X451" 500;
BA_DEF_DEF_  "GenSigTimeoutMsg_HU_B" 500;
BA_DEF_DEF_  "GenSigTimeoutMsg_HU_A" 500;
BA_DEF_DEF_  "GenSigStartValue" 0;
BA_DEF_DEF_  "GenSigSendType" "Cyclic";
BA_DEF_DEF_  "GenSigInactiveValue" 0;
BA_DEF_DEF_  "GenSigEnvVarType" "undef";
BA_DEF_DEF_  "GenSigCycleTimeActive" 0;
BA_DEF_DEF_  "GenSigCycleTime" 0;
BA_DEF_DEF_  "GenSigTimeoutMsg_HU_High_X445" 500;
BA_DEF_DEF_  "GenSigTimeoutMsg_HU_Mid_X445" 500;
BA_DEF_DEF_  "GenSigTimeoutTime_HU_High_X445" 500;
BA_DEF_DEF_  "GenSigTimeoutTime_HU_Mid_X445" 500;
BA_DEF_DEF_  "GenSigTimeoutMsg_IVI" 500;
BA_DEF_DEF_  "GenSigTimeoutTime_IVI" 500;
BA_DEF_DEF_  "NmMessage" "no";
BA_DEF_DEF_  "NmAsrMessage" "<n.a.>";
BA_DEF_DEF_  "MessageTimeout" 500;
BA_DEF_DEF_  "Me" 0;
BA_DEF_DEF_  "GenMsgStartDelayTime" 0;
BA_DEF_DEF_  "GenMsgSendType" "Cyclic";
BA_DEF_DEF_  "GenMsgNrOfRepetition" 0;
BA_DEF_DEF_  "GenMsgILSupport" "Yes";
BA_DEF_DEF_  "GenMsgDelayTime" 0;
BA_DEF_DEF_  "GenMsgCycleTimeFast" 0;
BA_DEF_DEF_  "GenMsgCycleTime" 0;
BA_DEF_DEF_  "DiagUudtResponse" "false";
BA_DEF_DEF_  "DiagUsdtResponse" "false";
BA_DEF_DEF_  "DiagState" "No";
BA_DEF_DEF_  "DiagResponse" "No";
BA_DEF_DEF_  "DiagRequest" "No";
BA_DEF_DEF_  "MsgType" "Application";
BA_DEF_DEF_  "SystemSignalLongSymbol" "";
BA_ "MessageTimeout" BO_ 473 0;
BA_ "GenMsgSendType" BO_ 473 8;
BA_ "GenMsgNrOfRepetition" BO_ 473 3;
BA_ "GenMsgDelayTime" BO_ 473 200;
BA_ "GenMsgCycleTimeFast" BO_ 473 200;
BA_ "MessageTimeout" BO_ 1141 0;
BA_ "GenMsgStartDelayTime" BO_ 1141 24;
BA_ "GenMsgCycleTime" BO_ 1141 100;
BA_ "MessageTimeout" BO_ 436 0;
BA_ "GenMsgSendType" BO_ 436 8;
BA_ "GenMsgNrOfRepetition" BO_ 436 3;
BA_ "GenMsgDelayTime" BO_ 436 500;
BA_ "GenMsgCycleTimeFast" BO_ 436 500;
BA_ "GenMsgCycleTime" BO_ 1308 100;
BA_ "GenMsgCycleTime" BO_ 1307 100;
BA_ "GenMsgCycleTime" BO_ 1306 100;
BA_ "MessageTimeout" BO_ 525 0;
BA_ "GenMsgSendType" BO_ 525 8;
BA_ "GenMsgNrOfRepetition" BO_ 525 5;
BA_ "GenMsgDelayTime" BO_ 525 100;
BA_ "GenMsgCycleTimeFast" BO_ 525 100;
BA_ "GenMsgCycleTime" BO_ 639 100;
BA_ "MessageTimeout" BO_ 496 0;
BA_ "GenMsgSendType" BO_ 496 8;
BA_ "GenMsgNrOfRepetition" BO_ 496 3;
BA_ "GenMsgDelayTime" BO_ 496 100;
BA_ "GenMsgCycleTimeFast" BO_ 496 100;
BA_ "MessageTimeout" BO_ 1123 0;
BA_ "GenMsgSendType" BO_ 1123 8;
BA_ "MessageTimeout" BO_ 1122 0;
BA_ "GenMsgSendType" BO_ 1122 8;
BA_ "GenMsgCycleTime" BO_ 584 100;
BA_ "GenMsgCycleTime" BO_ 354 20;
BA_ "MessageTimeout" BO_ 1592 0;
BA_ "GenMsgSendType" BO_ 1592 8;
BA_ "GenMsgILSupport" BO_ 1592 0;
BA_ "DiagResponse" BO_ 1592 1;
BA_ "MessageTimeout" BO_ 1848 0;
BA_ "GenMsgSendType" BO_ 1848 8;
BA_ "GenMsgILSupport" BO_ 1848 0;
BA_ "DiagResponse" BO_ 1848 1;
BA_ "MessageTimeout" BO_ 1840 0;
BA_ "GenMsgSendType" BO_ 1840 8;
BA_ "GenMsgILSupport" BO_ 1840 0;
BA_ "DiagRequest" BO_ 1840 1;
BA_ "GenMsgCycleTime" BO_ 728 100;
BA_ "GenMsgCycleTime" BO_ 275 10;
BA_ "GenMsgCycleTime" BO_ 736 100;
BA_ "MessageTimeout" BO_ 467 0;
BA_ "GenMsgSendType" BO_ 467 8;
BA_ "GenMsgNrOfRepetition" BO_ 467 3;
BA_ "GenMsgDelayTime" BO_ 467 200;
BA_ "GenMsgCycleTimeFast" BO_ 467 200;
BA_ "GenMsgCycleTime" BO_ 583 100;
BA_ "GenMsgCycleTime" BO_ 741 100;
BA_ "GenMsgCycleTime" BO_ 378 20;
BA_ "GenMsgCycleTime" BO_ 673 100;
BA_ "MessageTimeout" BO_ 491 0;
BA_ "GenMsgSendType" BO_ 491 8;
BA_ "GenMsgNrOfRepetition" BO_ 491 3;
BA_ "GenMsgDelayTime" BO_ 491 500;
BA_ "GenMsgCycleTimeFast" BO_ 491 500;
BA_ "MessageTimeout" BO_ 461 0;
BA_ "GenMsgSendType" BO_ 461 8;
BA_ "GenMsgNrOfRepetition" BO_ 461 3;
BA_ "GenMsgDelayTime" BO_ 461 500;
BA_ "GenMsgCycleTimeFast" BO_ 461 500;
BA_ "MessageTimeout" BO_ 489 0;
BA_ "GenMsgSendType" BO_ 489 8;
BA_ "GenMsgNrOfRepetition" BO_ 489 3;
BA_ "GenMsgDelayTime" BO_ 489 500;
BA_ "GenMsgCycleTimeFast" BO_ 489 500;
BA_ "GenSigTimeoutTime_HU_Mid_X451" SG_ 473 HuETcLowTempConfigValueAck 0;
BA_ "GenSigTimeoutTime_HU_High_X451" SG_ 473 HuETcLowTempConfigValueAck 0;
BA_ "GenSigTimeoutTime_HU_B" SG_ 473 HuETcLowTempConfigValueAck 0;
BA_ "GenSigTimeoutTime_HU_A" SG_ 473 HuETcLowTempConfigValueAck 0;
BA_ "GenSigTimeoutMsg_HU_Mid_X451" SG_ 473 HuETcLowTempConfigValueAck 0;
BA_ "GenSigTimeoutMsg_HU_High_X451" SG_ 473 HuETcLowTempConfigValueAck 0;
BA_ "GenSigTimeoutMsg_HU_B" SG_ 473 HuETcLowTempConfigValueAck 0;
BA_ "GenSigTimeoutMsg_HU_A" SG_ 473 HuETcLowTempConfigValueAck 0;
BA_ "GenSigSendType" SG_ 473 HuETcLowTempConfigValueAck 2;
BA_ "GenSigTimeoutMsg_HU_High_X445" SG_ 473 HuETcLowTempConfigValueAck 0;
BA_ "GenSigTimeoutMsg_HU_Mid_X445" SG_ 473 HuETcLowTempConfigValueAck 0;
BA_ "GenSigTimeoutTime_HU_High_X445" SG_ 473 HuETcLowTempConfigValueAck 0;
BA_ "GenSigTimeoutTime_HU_Mid_X445" SG_ 473 HuETcLowTempConfigValueAck 0;
BA_ "GenSigTimeoutMsg_IVI" SG_ 473 HuETcLowTempConfigValueAck 0;
BA_ "GenSigTimeoutTime_IVI" SG_ 473 HuETcLowTempConfigValueAck 0;
BA_ "GenSigTimeoutTime_HU_Mid_X451" SG_ 473 HuETcLowFanSpdConfigValueAck 0;
BA_ "GenSigTimeoutTime_HU_High_X451" SG_ 473 HuETcLowFanSpdConfigValueAck 0;
BA_ "GenSigTimeoutTime_HU_B" SG_ 473 HuETcLowFanSpdConfigValueAck 0;
BA_ "GenSigTimeoutTime_HU_A" SG_ 473 HuETcLowFanSpdConfigValueAck 0;
BA_ "GenSigTimeoutMsg_HU_Mid_X451" SG_ 473 HuETcLowFanSpdConfigValueAck 0;
BA_ "GenSigTimeoutMsg_HU_High_X451" SG_ 473 HuETcLowFanSpdConfigValueAck 0;
BA_ "GenSigTimeoutMsg_HU_B" SG_ 473 HuETcLowFanSpdConfigValueAck 0;
BA_ "GenSigTimeoutMsg_HU_A" SG_ 473 HuETcLowFanSpdConfigValueAck 0;
BA_ "GenSigSendType" SG_ 473 HuETcLowFanSpdConfigValueAck 2;
BA_ "GenSigTimeoutMsg_HU_High_X445" SG_ 473 HuETcLowFanSpdConfigValueAck 0;
BA_ "GenSigTimeoutMsg_HU_Mid_X445" SG_ 473 HuETcLowFanSpdConfigValueAck 0;
BA_ "GenSigTimeoutTime_HU_High_X445" SG_ 473 HuETcLowFanSpdConfigValueAck 0;
BA_ "GenSigTimeoutTime_HU_Mid_X445" SG_ 473 HuETcLowFanSpdConfigValueAck 0;
BA_ "GenSigTimeoutMsg_IVI" SG_ 473 HuETcLowFanSpdConfigValueAck 0;
BA_ "GenSigTimeoutTime_IVI" SG_ 473 HuETcLowFanSpdConfigValueAck 0;
BA_ "GenSigTimeoutTime_HU_Mid_X451" SG_ 473 HuETcHiTempConfigValueAck 0;
BA_ "GenSigTimeoutTime_HU_High_X451" SG_ 473 HuETcHiTempConfigValueAck 0;
BA_ "GenSigTimeoutTime_HU_B" SG_ 473 HuETcHiTempConfigValueAck 0;
BA_ "GenSigTimeoutTime_HU_A" SG_ 473 HuETcHiTempConfigValueAck 0;
BA_ "GenSigTimeoutMsg_HU_Mid_X451" SG_ 473 HuETcHiTempConfigValueAck 0;
BA_ "GenSigTimeoutMsg_HU_High_X451" SG_ 473 HuETcHiTempConfigValueAck 0;
BA_ "GenSigTimeoutMsg_HU_B" SG_ 473 HuETcHiTempConfigValueAck 0;
BA_ "GenSigTimeoutMsg_HU_A" SG_ 473 HuETcHiTempConfigValueAck 0;
BA_ "GenSigSendType" SG_ 473 HuETcHiTempConfigValueAck 2;
BA_ "GenSigTimeoutMsg_HU_High_X445" SG_ 473 HuETcHiTempConfigValueAck 0;
BA_ "GenSigTimeoutMsg_HU_Mid_X445" SG_ 473 HuETcHiTempConfigValueAck 0;
BA_ "GenSigTimeoutTime_HU_High_X445" SG_ 473 HuETcHiTempConfigValueAck 0;
BA_ "GenSigTimeoutTime_HU_Mid_X445" SG_ 473 HuETcHiTempConfigValueAck 0;
BA_ "GenSigTimeoutMsg_IVI" SG_ 473 HuETcHiTempConfigValueAck 0;
BA_ "GenSigTimeoutTime_IVI" SG_ 473 HuETcHiTempConfigValueAck 0;
BA_ "GenSigTimeoutTime_HU_Mid_X451" SG_ 473 HuETcHiFanSpdConfigValueAck 0;
BA_ "GenSigTimeoutTime_HU_High_X451" SG_ 473 HuETcHiFanSpdConfigValueAck 0;
BA_ "GenSigTimeoutTime_HU_B" SG_ 473 HuETcHiFanSpdConfigValueAck 0;
BA_ "GenSigTimeoutTime_HU_A" SG_ 473 HuETcHiFanSpdConfigValueAck 0;
BA_ "GenSigTimeoutMsg_HU_Mid_X451" SG_ 473 HuETcHiFanSpdConfigValueAck 0;
BA_ "GenSigTimeoutMsg_HU_High_X451" SG_ 473 HuETcHiFanSpdConfigValueAck 0;
BA_ "GenSigTimeoutMsg_HU_B" SG_ 473 HuETcHiFanSpdConfigValueAck 0;
BA_ "GenSigTimeoutMsg_HU_A" SG_ 473 HuETcHiFanSpdConfigValueAck 0;
BA_ "GenSigSendType" SG_ 473 HuETcHiFanSpdConfigValueAck 2;
BA_ "GenSigTimeoutMsg_HU_High_X445" SG_ 473 HuETcHiFanSpdConfigValueAck 0;
BA_ "GenSigTimeoutMsg_HU_Mid_X445" SG_ 473 HuETcHiFanSpdConfigValueAck 0;
BA_ "GenSigTimeoutTime_HU_High_X445" SG_ 473 HuETcHiFanSpdConfigValueAck 0;
BA_ "GenSigTimeoutTime_HU_Mid_X445" SG_ 473 HuETcHiFanSpdConfigValueAck 0;
BA_ "GenSigTimeoutMsg_IVI" SG_ 473 HuETcHiFanSpdConfigValueAck 0;
BA_ "GenSigTimeoutTime_IVI" SG_ 473 HuETcHiFanSpdConfigValueAck 0;
BA_ "GenSigTimeoutTime_HU_Mid_X451" SG_ 473 HuETcTempReq 0;
BA_ "GenSigTimeoutTime_HU_High_X451" SG_ 473 HuETcTempReq 0;
BA_ "GenSigTimeoutTime_HU_B" SG_ 473 HuETcTempReq 0;
BA_ "GenSigTimeoutTime_HU_A" SG_ 473 HuETcTempReq 0;
BA_ "GenSigTimeoutMsg_HU_Mid_X451" SG_ 473 HuETcTempReq 0;
BA_ "GenSigTimeoutMsg_HU_High_X451" SG_ 473 HuETcTempReq 0;
BA_ "GenSigTimeoutMsg_HU_B" SG_ 473 HuETcTempReq 0;
BA_ "GenSigTimeoutMsg_HU_A" SG_ 473 HuETcTempReq 0;
BA_ "GenSigSendType" SG_ 473 HuETcTempReq 2;
BA_ "GenSigTimeoutMsg_HU_High_X445" SG_ 473 HuETcTempReq 0;
BA_ "GenSigTimeoutMsg_HU_Mid_X445" SG_ 473 HuETcTempReq 0;
BA_ "GenSigTimeoutTime_HU_High_X445" SG_ 473 HuETcTempReq 0;
BA_ "GenSigTimeoutTime_HU_Mid_X445" SG_ 473 HuETcTempReq 0;
BA_ "GenSigTimeoutMsg_IVI" SG_ 473 HuETcTempReq 0;
BA_ "GenSigTimeoutTime_IVI" SG_ 473 HuETcTempReq 0;
BA_ "GenSigTimeoutTime_HU_Mid_X451" SG_ 473 HuETcFanSpdReq 0;
BA_ "GenSigTimeoutTime_HU_High_X451" SG_ 473 HuETcFanSpdReq 0;
BA_ "GenSigTimeoutTime_HU_B" SG_ 473 HuETcFanSpdReq 0;
BA_ "GenSigTimeoutTime_HU_A" SG_ 473 HuETcFanSpdReq 0;
BA_ "GenSigTimeoutMsg_HU_Mid_X451" SG_ 473 HuETcFanSpdReq 0;
BA_ "GenSigTimeoutMsg_HU_High_X451" SG_ 473 HuETcFanSpdReq 0;
BA_ "GenSigTimeoutMsg_HU_B" SG_ 473 HuETcFanSpdReq 0;
BA_ "GenSigTimeoutMsg_HU_A" SG_ 473 HuETcFanSpdReq 0;
BA_ "GenSigSendType" SG_ 473 HuETcFanSpdReq 2;
BA_ "GenSigTimeoutMsg_HU_High_X445" SG_ 473 HuETcFanSpdReq 0;
BA_ "GenSigTimeoutMsg_HU_Mid_X445" SG_ 473 HuETcFanSpdReq 0;
BA_ "GenSigTimeoutTime_HU_High_X445" SG_ 473 HuETcFanSpdReq 0;
BA_ "GenSigTimeoutTime_HU_Mid_X445" SG_ 473 HuETcFanSpdReq 0;
BA_ "GenSigTimeoutMsg_IVI" SG_ 473 HuETcFanSpdReq 0;
BA_ "GenSigTimeoutTime_IVI" SG_ 473 HuETcFanSpdReq 0;
BA_ "GenSigTimeoutTime_HU_Mid_X451" SG_ 473 IpcSwcEvent 0;
BA_ "GenSigTimeoutTime_HU_High_X451" SG_ 473 IpcSwcEvent 0;
BA_ "GenSigTimeoutTime_HU_B" SG_ 473 IpcSwcEvent 0;
BA_ "GenSigTimeoutTime_HU_A" SG_ 473 IpcSwcEvent 0;
BA_ "GenSigTimeoutMsg_HU_Mid_X451" SG_ 473 IpcSwcEvent 0;
BA_ "GenSigTimeoutMsg_HU_High_X451" SG_ 473 IpcSwcEvent 0;
BA_ "GenSigTimeoutMsg_HU_B" SG_ 473 IpcSwcEvent 0;
BA_ "GenSigTimeoutMsg_HU_A" SG_ 473 IpcSwcEvent 0;
BA_ "GenSigSendType" SG_ 473 IpcSwcEvent 2;
BA_ "GenSigTimeoutMsg_HU_High_X445" SG_ 473 IpcSwcEvent 0;
BA_ "GenSigTimeoutMsg_HU_Mid_X445" SG_ 473 IpcSwcEvent 0;
BA_ "GenSigTimeoutTime_HU_High_X445" SG_ 473 IpcSwcEvent 0;
BA_ "GenSigTimeoutTime_HU_Mid_X445" SG_ 473 IpcSwcEvent 0;
BA_ "GenSigTimeoutMsg_IVI" SG_ 473 IpcSwcEvent 0;
BA_ "GenSigTimeoutTime_IVI" SG_ 473 IpcSwcEvent 0;
BA_ "GenSigTimeoutTime_HU_Mid_X451" SG_ 473 IviSwcEvent 0;
BA_ "GenSigTimeoutTime_HU_High_X451" SG_ 473 IviSwcEvent 0;
BA_ "GenSigTimeoutTime_HU_B" SG_ 473 IviSwcEvent 0;
BA_ "GenSigTimeoutTime_HU_A" SG_ 473 IviSwcEvent 0;
BA_ "GenSigTimeoutMsg_HU_Mid_X451" SG_ 473 IviSwcEvent 0;
BA_ "GenSigTimeoutMsg_HU_High_X451" SG_ 473 IviSwcEvent 0;
BA_ "GenSigTimeoutMsg_HU_B" SG_ 473 IviSwcEvent 0;
BA_ "GenSigTimeoutMsg_HU_A" SG_ 473 IviSwcEvent 0;
BA_ "GenSigSendType" SG_ 473 IviSwcEvent 2;
BA_ "GenSigTimeoutMsg_HU_High_X445" SG_ 473 IviSwcEvent 0;
BA_ "GenSigTimeoutMsg_HU_Mid_X445" SG_ 473 IviSwcEvent 0;
BA_ "GenSigTimeoutTime_HU_High_X445" SG_ 473 IviSwcEvent 0;
BA_ "GenSigTimeoutTime_HU_Mid_X445" SG_ 473 IviSwcEvent 0;
BA_ "GenSigTimeoutMsg_IVI" SG_ 473 IviSwcEvent 0;
BA_ "GenSigTimeoutTime_IVI" SG_ 473 IviSwcEvent 0;
BA_ "GenSigTimeoutTime_HU_B" SG_ 1141 IPC_MRC_Failure_Status 0;
BA_ "GenSigTimeoutTime_HU_A" SG_ 1141 IPC_MRC_Failure_Status 0;
BA_ "GenSigTimeoutMsg_HU_B" SG_ 1141 IPC_MRC_Failure_Status 0;
BA_ "GenSigTimeoutMsg_HU_A" SG_ 1141 IPC_MRC_Failure_Status 0;
BA_ "GenSigSendType" SG_ 1141 IPC_MRC_Failure_Status 7;
BA_ "GenSigCycleTimeActive" SG_ 1141 IPC_MRC_Failure_Status 100;
BA_ "GenSigCycleTime" SG_ 1141 IPC_MRC_Failure_Status 100;
BA_ "GenSigTimeoutTime_HU_B" SG_ 1141 IPC_CRC_Failure_Status 0;
BA_ "GenSigTimeoutTime_HU_A" SG_ 1141 IPC_CRC_Failure_Status 0;
BA_ "GenSigTimeoutMsg_HU_B" SG_ 1141 IPC_CRC_Failure_Status 0;
BA_ "GenSigTimeoutMsg_HU_A" SG_ 1141 IPC_CRC_Failure_Status 0;
BA_ "GenSigSendType" SG_ 1141 IPC_CRC_Failure_Status 7;
BA_ "GenSigCycleTimeActive" SG_ 1141 IPC_CRC_Failure_Status 100;
BA_ "GenSigCycleTime" SG_ 1141 IPC_CRC_Failure_Status 100;
BA_ "GenSigTimeoutTime_HU_B" SG_ 1141 AT_AMT_DCT_MRC_Failure_Status 0;
BA_ "GenSigTimeoutTime_HU_A" SG_ 1141 AT_AMT_DCT_MRC_Failure_Status 0;
BA_ "GenSigTimeoutMsg_HU_B" SG_ 1141 AT_AMT_DCT_MRC_Failure_Status 0;
BA_ "GenSigTimeoutMsg_HU_A" SG_ 1141 AT_AMT_DCT_MRC_Failure_Status 0;
BA_ "GenSigSendType" SG_ 1141 AT_AMT_DCT_MRC_Failure_Status 7;
BA_ "GenSigCycleTimeActive" SG_ 1141 AT_AMT_DCT_MRC_Failure_Status 100;
BA_ "GenSigCycleTime" SG_ 1141 AT_AMT_DCT_MRC_Failure_Status 100;
BA_ "GenSigTimeoutTime_HU_B" SG_ 1141 AT_AMT_DCT_CRC_Failure_Status 0;
BA_ "GenSigTimeoutTime_HU_A" SG_ 1141 AT_AMT_DCT_CRC_Failure_Status 0;
BA_ "GenSigTimeoutMsg_HU_B" SG_ 1141 AT_AMT_DCT_CRC_Failure_Status 0;
BA_ "GenSigTimeoutMsg_HU_A" SG_ 1141 AT_AMT_DCT_CRC_Failure_Status 0;
BA_ "GenSigSendType" SG_ 1141 AT_AMT_DCT_CRC_Failure_Status 7;
BA_ "GenSigCycleTimeActive" SG_ 1141 AT_AMT_DCT_CRC_Failure_Status 100;
BA_ "GenSigCycleTime" SG_ 1141 AT_AMT_DCT_CRC_Failure_Status 100;
BA_ "GenSigTimeoutTime_HU_Mid_X451" SG_ 436 PotSwRkeOnOffReqAck 0;
BA_ "GenSigTimeoutTime_HU_High_X451" SG_ 436 PotSwRkeOnOffReqAck 0;
BA_ "GenSigTimeoutTime_HU_B" SG_ 436 PotSwRkeOnOffReqAck 0;
BA_ "GenSigTimeoutTime_HU_A" SG_ 436 PotSwRkeOnOffReqAck 0;
BA_ "GenSigTimeoutMsg_HU_Mid_X451" SG_ 436 PotSwRkeOnOffReqAck 0;
BA_ "GenSigTimeoutMsg_HU_High_X451" SG_ 436 PotSwRkeOnOffReqAck 0;
BA_ "GenSigTimeoutMsg_HU_B" SG_ 436 PotSwRkeOnOffReqAck 0;
BA_ "GenSigTimeoutMsg_HU_A" SG_ 436 PotSwRkeOnOffReqAck 0;
BA_ "GenSigSendType" SG_ 436 PotSwRkeOnOffReqAck 2;
BA_ "GenSigTimeoutMsg_HU_High_X445" SG_ 436 PotSwRkeOnOffReqAck 0;
BA_ "GenSigTimeoutMsg_HU_Mid_X445" SG_ 436 PotSwRkeOnOffReqAck 0;
BA_ "GenSigTimeoutTime_HU_High_X445" SG_ 436 PotSwRkeOnOffReqAck 0;
BA_ "GenSigTimeoutTime_HU_Mid_X445" SG_ 436 PotSwRkeOnOffReqAck 0;
BA_ "GenSigTimeoutMsg_IVI" SG_ 436 PotSwRkeOnOffReqAck 0;
BA_ "GenSigTimeoutTime_IVI" SG_ 436 PotSwRkeOnOffReqAck 0;
BA_ "GenSigTimeoutTime_HU_Mid_X451" SG_ 436 PotGestOnOffReqAck 0;
BA_ "GenSigTimeoutTime_HU_High_X451" SG_ 436 PotGestOnOffReqAck 0;
BA_ "GenSigTimeoutTime_HU_B" SG_ 436 PotGestOnOffReqAck 0;
BA_ "GenSigTimeoutTime_HU_A" SG_ 436 PotGestOnOffReqAck 0;
BA_ "GenSigTimeoutMsg_HU_Mid_X451" SG_ 436 PotGestOnOffReqAck 0;
BA_ "GenSigTimeoutMsg_HU_High_X451" SG_ 436 PotGestOnOffReqAck 0;
BA_ "GenSigTimeoutMsg_HU_B" SG_ 436 PotGestOnOffReqAck 0;
BA_ "GenSigTimeoutMsg_HU_A" SG_ 436 PotGestOnOffReqAck 0;
BA_ "GenSigSendType" SG_ 436 PotGestOnOffReqAck 2;
BA_ "GenSigTimeoutMsg_HU_High_X445" SG_ 436 PotGestOnOffReqAck 0;
BA_ "GenSigTimeoutMsg_HU_Mid_X445" SG_ 436 PotGestOnOffReqAck 0;
BA_ "GenSigTimeoutTime_HU_High_X445" SG_ 436 PotGestOnOffReqAck 0;
BA_ "GenSigTimeoutTime_HU_Mid_X445" SG_ 436 PotGestOnOffReqAck 0;
BA_ "GenSigTimeoutMsg_IVI" SG_ 436 PotGestOnOffReqAck 0;
BA_ "GenSigTimeoutTime_IVI" SG_ 436 PotGestOnOffReqAck 0;
BA_ "GenSigTimeoutTime_HU_Mid_X451" SG_ 436 PotBuzzOnOffReqAck 0;
BA_ "GenSigTimeoutTime_HU_High_X451" SG_ 436 PotBuzzOnOffReqAck 0;
BA_ "GenSigTimeoutTime_HU_B" SG_ 436 PotBuzzOnOffReqAck 0;
BA_ "GenSigTimeoutTime_HU_A" SG_ 436 PotBuzzOnOffReqAck 0;
BA_ "GenSigTimeoutMsg_HU_Mid_X451" SG_ 436 PotBuzzOnOffReqAck 0;
BA_ "GenSigTimeoutMsg_HU_High_X451" SG_ 436 PotBuzzOnOffReqAck 0;
BA_ "GenSigTimeoutMsg_HU_B" SG_ 436 PotBuzzOnOffReqAck 0;
BA_ "GenSigTimeoutMsg_HU_A" SG_ 436 PotBuzzOnOffReqAck 0;
BA_ "GenSigSendType" SG_ 436 PotBuzzOnOffReqAck 2;
BA_ "GenSigTimeoutMsg_HU_High_X445" SG_ 436 PotBuzzOnOffReqAck 0;
BA_ "GenSigTimeoutMsg_HU_Mid_X445" SG_ 436 PotBuzzOnOffReqAck 0;
BA_ "GenSigTimeoutTime_HU_High_X445" SG_ 436 PotBuzzOnOffReqAck 0;
BA_ "GenSigTimeoutTime_HU_Mid_X445" SG_ 436 PotBuzzOnOffReqAck 0;
BA_ "GenSigTimeoutMsg_IVI" SG_ 436 PotBuzzOnOffReqAck 0;
BA_ "GenSigTimeoutTime_IVI" SG_ 436 PotBuzzOnOffReqAck 0;
BA_ "GenSigTimeoutTime_HU_Mid_X451" SG_ 436 PotHeightAdjAck 0;
BA_ "GenSigTimeoutTime_HU_High_X451" SG_ 436 PotHeightAdjAck 0;
BA_ "GenSigTimeoutTime_HU_B" SG_ 436 PotHeightAdjAck 0;
BA_ "GenSigTimeoutTime_HU_A" SG_ 436 PotHeightAdjAck 0;
BA_ "GenSigTimeoutMsg_HU_Mid_X451" SG_ 436 PotHeightAdjAck 0;
BA_ "GenSigTimeoutMsg_HU_High_X451" SG_ 436 PotHeightAdjAck 0;
BA_ "GenSigTimeoutMsg_HU_B" SG_ 436 PotHeightAdjAck 0;
BA_ "GenSigTimeoutMsg_HU_A" SG_ 436 PotHeightAdjAck 0;
BA_ "GenSigSendType" SG_ 436 PotHeightAdjAck 2;
BA_ "GenSigTimeoutMsg_HU_High_X445" SG_ 436 PotHeightAdjAck 0;
BA_ "GenSigTimeoutMsg_HU_Mid_X445" SG_ 436 PotHeightAdjAck 0;
BA_ "GenSigTimeoutTime_HU_High_X445" SG_ 436 PotHeightAdjAck 0;
BA_ "GenSigTimeoutTime_HU_Mid_X445" SG_ 436 PotHeightAdjAck 0;
BA_ "GenSigTimeoutMsg_IVI" SG_ 436 PotHeightAdjAck 0;
BA_ "GenSigTimeoutTime_IVI" SG_ 436 PotHeightAdjAck 0;
BA_ "GenSigTimeoutTime_HU_Mid_X451" SG_ 436 BCmHuGotoEntryExitPosAck 0;
BA_ "GenSigTimeoutTime_HU_High_X451" SG_ 436 BCmHuGotoEntryExitPosAck 0;
BA_ "GenSigTimeoutTime_HU_B" SG_ 436 BCmHuGotoEntryExitPosAck 0;
BA_ "GenSigTimeoutTime_HU_A" SG_ 436 BCmHuGotoEntryExitPosAck 0;
BA_ "GenSigTimeoutMsg_HU_Mid_X451" SG_ 436 BCmHuGotoEntryExitPosAck 0;
BA_ "GenSigTimeoutMsg_HU_High_X451" SG_ 436 BCmHuGotoEntryExitPosAck 0;
BA_ "GenSigTimeoutMsg_HU_B" SG_ 436 BCmHuGotoEntryExitPosAck 0;
BA_ "GenSigTimeoutMsg_HU_A" SG_ 436 BCmHuGotoEntryExitPosAck 0;
BA_ "GenSigSendType" SG_ 436 BCmHuGotoEntryExitPosAck 2;
BA_ "GenSigTimeoutMsg_HU_High_X445" SG_ 436 BCmHuGotoEntryExitPosAck 0;
BA_ "GenSigTimeoutMsg_HU_Mid_X445" SG_ 436 BCmHuGotoEntryExitPosAck 0;
BA_ "GenSigTimeoutTime_HU_High_X445" SG_ 436 BCmHuGotoEntryExitPosAck 0;
BA_ "GenSigTimeoutTime_HU_Mid_X445" SG_ 436 BCmHuGotoEntryExitPosAck 0;
BA_ "GenSigTimeoutMsg_IVI" SG_ 436 BCmHuGotoEntryExitPosAck 0;
BA_ "GenSigTimeoutTime_IVI" SG_ 436 BCmHuGotoEntryExitPosAck 0;
BA_ "GenSigTimeoutTime_HU_Mid_X451" SG_ 436 BCMRemotePrecheck 0;
BA_ "GenSigTimeoutTime_HU_High_X451" SG_ 436 BCMRemotePrecheck 0;
BA_ "GenSigTimeoutTime_HU_B" SG_ 436 BCMRemotePrecheck 0;
BA_ "GenSigTimeoutTime_HU_A" SG_ 436 BCMRemotePrecheck 0;
BA_ "GenSigTimeoutMsg_HU_Mid_X451" SG_ 436 BCMRemotePrecheck 0;
BA_ "GenSigTimeoutMsg_HU_High_X451" SG_ 436 BCMRemotePrecheck 0;
BA_ "GenSigTimeoutMsg_HU_B" SG_ 436 BCMRemotePrecheck 0;
BA_ "GenSigTimeoutMsg_HU_A" SG_ 436 BCMRemotePrecheck 0;
BA_ "GenSigSendType" SG_ 436 BCMRemotePrecheck 2;
BA_ "GenSigTimeoutMsg_HU_High_X445" SG_ 436 BCMRemotePrecheck 0;
BA_ "GenSigTimeoutMsg_HU_Mid_X445" SG_ 436 BCMRemotePrecheck 0;
BA_ "GenSigTimeoutTime_HU_High_X445" SG_ 436 BCMRemotePrecheck 0;
BA_ "GenSigTimeoutTime_HU_Mid_X445" SG_ 436 BCMRemotePrecheck 0;
BA_ "GenSigTimeoutMsg_IVI" SG_ 436 BCMRemotePrecheck 0;
BA_ "GenSigTimeoutTime_IVI" SG_ 436 BCMRemotePrecheck 0;
BA_ "GenSigTimeoutTime_HU_Mid_X451" SG_ 525 PotKickSensorReq 0;
BA_ "GenSigTimeoutTime_HU_High_X451" SG_ 525 PotKickSensorReq 0;
BA_ "GenSigTimeoutTime_HU_B" SG_ 525 PotKickSensorReq 0;
BA_ "GenSigTimeoutTime_HU_A" SG_ 525 PotKickSensorReq 0;
BA_ "GenSigTimeoutMsg_HU_Mid_X451" SG_ 525 PotKickSensorReq 0;
BA_ "GenSigTimeoutMsg_HU_High_X451" SG_ 525 PotKickSensorReq 0;
BA_ "GenSigTimeoutMsg_HU_B" SG_ 525 PotKickSensorReq 0;
BA_ "GenSigTimeoutMsg_HU_A" SG_ 525 PotKickSensorReq 0;
BA_ "GenSigSendType" SG_ 525 PotKickSensorReq 2;
BA_ "GenSigTimeoutMsg_HU_High_X445" SG_ 525 PotKickSensorReq 0;
BA_ "GenSigTimeoutMsg_HU_Mid_X445" SG_ 525 PotKickSensorReq 0;
BA_ "GenSigTimeoutTime_HU_High_X445" SG_ 525 PotKickSensorReq 0;
BA_ "GenSigTimeoutTime_HU_Mid_X445" SG_ 525 PotKickSensorReq 0;
BA_ "GenSigTimeoutMsg_IVI" SG_ 525 PotKickSensorReq 0;
BA_ "GenSigTimeoutTime_IVI" SG_ 525 PotKickSensorReq 0;
BA_ "GenSigTimeoutTime_HU_Mid_X451" SG_ 525 PotUidButtonReq 0;
BA_ "GenSigTimeoutTime_HU_High_X451" SG_ 525 PotUidButtonReq 0;
BA_ "GenSigTimeoutTime_HU_B" SG_ 525 PotUidButtonReq 0;
BA_ "GenSigTimeoutTime_HU_A" SG_ 525 PotUidButtonReq 0;
BA_ "GenSigTimeoutMsg_HU_Mid_X451" SG_ 525 PotUidButtonReq 0;
BA_ "GenSigTimeoutMsg_HU_High_X451" SG_ 525 PotUidButtonReq 0;
BA_ "GenSigTimeoutMsg_HU_B" SG_ 525 PotUidButtonReq 0;
BA_ "GenSigTimeoutMsg_HU_A" SG_ 525 PotUidButtonReq 0;
BA_ "GenSigSendType" SG_ 525 PotUidButtonReq 2;
BA_ "GenSigTimeoutMsg_HU_High_X445" SG_ 525 PotUidButtonReq 0;
BA_ "GenSigTimeoutMsg_HU_Mid_X445" SG_ 525 PotUidButtonReq 0;
BA_ "GenSigTimeoutTime_HU_High_X445" SG_ 525 PotUidButtonReq 0;
BA_ "GenSigTimeoutTime_HU_Mid_X445" SG_ 525 PotUidButtonReq 0;
BA_ "GenSigTimeoutMsg_IVI" SG_ 525 PotUidButtonReq 0;
BA_ "GenSigTimeoutTime_IVI" SG_ 525 PotUidButtonReq 0;
BA_ "GenSigTimeoutTime_HU_Mid_X451" SG_ 525 PotPepsTailgateSwReq 0;
BA_ "GenSigTimeoutTime_HU_High_X451" SG_ 525 PotPepsTailgateSwReq 0;
BA_ "GenSigTimeoutTime_HU_B" SG_ 525 PotPepsTailgateSwReq 0;
BA_ "GenSigTimeoutTime_HU_A" SG_ 525 PotPepsTailgateSwReq 0;
BA_ "GenSigTimeoutMsg_HU_Mid_X451" SG_ 525 PotPepsTailgateSwReq 0;
BA_ "GenSigTimeoutMsg_HU_High_X451" SG_ 525 PotPepsTailgateSwReq 0;
BA_ "GenSigTimeoutMsg_HU_B" SG_ 525 PotPepsTailgateSwReq 0;
BA_ "GenSigTimeoutMsg_HU_A" SG_ 525 PotPepsTailgateSwReq 0;
BA_ "GenSigSendType" SG_ 525 PotPepsTailgateSwReq 2;
BA_ "GenSigTimeoutMsg_HU_High_X445" SG_ 525 PotPepsTailgateSwReq 0;
BA_ "GenSigTimeoutMsg_HU_Mid_X445" SG_ 525 PotPepsTailgateSwReq 0;
BA_ "GenSigTimeoutTime_HU_High_X445" SG_ 525 PotPepsTailgateSwReq 0;
BA_ "GenSigTimeoutTime_HU_Mid_X445" SG_ 525 PotPepsTailgateSwReq 0;
BA_ "GenSigTimeoutMsg_IVI" SG_ 525 PotPepsTailgateSwReq 0;
BA_ "GenSigTimeoutTime_IVI" SG_ 525 PotPepsTailgateSwReq 0;
BA_ "GenSigTimeoutTime_HU_Mid_X451" SG_ 525 PEPSRemoteCheck 0;
BA_ "GenSigTimeoutTime_HU_High_X451" SG_ 525 PEPSRemoteCheck 0;
BA_ "GenSigTimeoutTime_HU_B" SG_ 525 PEPSRemoteCheck 0;
BA_ "GenSigTimeoutTime_HU_A" SG_ 525 PEPSRemoteCheck 0;
BA_ "GenSigTimeoutMsg_HU_Mid_X451" SG_ 525 PEPSRemoteCheck 0;
BA_ "GenSigTimeoutMsg_HU_High_X451" SG_ 525 PEPSRemoteCheck 0;
BA_ "GenSigTimeoutMsg_HU_B" SG_ 525 PEPSRemoteCheck 0;
BA_ "GenSigTimeoutMsg_HU_A" SG_ 525 PEPSRemoteCheck 0;
BA_ "GenSigSendType" SG_ 525 PEPSRemoteCheck 2;
BA_ "GenSigTimeoutMsg_HU_High_X445" SG_ 525 PEPSRemoteCheck 0;
BA_ "GenSigTimeoutMsg_HU_Mid_X445" SG_ 525 PEPSRemoteCheck 0;
BA_ "GenSigTimeoutTime_HU_High_X445" SG_ 525 PEPSRemoteCheck 0;
BA_ "GenSigTimeoutTime_HU_Mid_X445" SG_ 525 PEPSRemoteCheck 0;
BA_ "GenSigTimeoutMsg_IVI" SG_ 525 PEPSRemoteCheck 0;
BA_ "GenSigTimeoutTime_IVI" SG_ 525 PEPSRemoteCheck 0;
BA_ "GenSigTimeoutTime_HU_Mid_X451" SG_ 525 FotaIgnOnHoldStateAck 0;
BA_ "GenSigTimeoutTime_HU_High_X451" SG_ 525 FotaIgnOnHoldStateAck 0;
BA_ "GenSigTimeoutTime_HU_B" SG_ 525 FotaIgnOnHoldStateAck 0;
BA_ "GenSigTimeoutTime_HU_A" SG_ 525 FotaIgnOnHoldStateAck 0;
BA_ "GenSigTimeoutMsg_HU_Mid_X451" SG_ 525 FotaIgnOnHoldStateAck 0;
BA_ "GenSigTimeoutMsg_HU_High_X451" SG_ 525 FotaIgnOnHoldStateAck 0;
BA_ "GenSigTimeoutMsg_HU_B" SG_ 525 FotaIgnOnHoldStateAck 0;
BA_ "GenSigTimeoutMsg_HU_A" SG_ 525 FotaIgnOnHoldStateAck 0;
BA_ "GenSigSendType" SG_ 525 FotaIgnOnHoldStateAck 2;
BA_ "GenSigTimeoutMsg_HU_High_X445" SG_ 525 FotaIgnOnHoldStateAck 0;
BA_ "GenSigTimeoutMsg_HU_Mid_X445" SG_ 525 FotaIgnOnHoldStateAck 0;
BA_ "GenSigTimeoutTime_HU_High_X445" SG_ 525 FotaIgnOnHoldStateAck 0;
BA_ "GenSigTimeoutTime_HU_Mid_X445" SG_ 525 FotaIgnOnHoldStateAck 0;
BA_ "GenSigTimeoutMsg_IVI" SG_ 525 FotaIgnOnHoldStateAck 0;
BA_ "GenSigTimeoutTime_IVI" SG_ 525 FotaIgnOnHoldStateAck 0;
BA_ "GenSigSendType" SG_ 639 DPfRegenCondnError 7;
BA_ "GenSigCycleTimeActive" SG_ 639 DPfRegenCondnError 100;
BA_ "GenSigCycleTime" SG_ 639 DPfRegenCondnError 100;
BA_ "GenSigSendType" SG_ 639 EMsHuBatteryVrCmdSupport 7;
BA_ "GenSigCycleTimeActive" SG_ 639 EMsHuBatteryVrCmdSupport 100;
BA_ "GenSigCycleTime" SG_ 639 EMsHuBatteryVrCmdSupport 100;
BA_ "GenSigSendType" SG_ 639 EMsHuBatteryVrCmdAck 7;
BA_ "GenSigCycleTimeActive" SG_ 639 EMsHuBatteryVrCmdAck 100;
BA_ "GenSigCycleTime" SG_ 639 EMsHuBatteryVrCmdAck 100;
BA_ "GenSigSendType" SG_ 639 EMsHuBatteryVrCmdAckStatus 7;
BA_ "GenSigCycleTimeActive" SG_ 639 EMsHuBatteryVrCmdAckStatus 100;
BA_ "GenSigCycleTime" SG_ 639 EMsHuBatteryVrCmdAckStatus 100;
BA_ "GenSigSendType" SG_ 639 EMsHuDPfRegenProgPercent 7;
BA_ "GenSigCycleTimeActive" SG_ 639 EMsHuDPfRegenProgPercent 100;
BA_ "GenSigCycleTime" SG_ 639 EMsHuDPfRegenProgPercent 100;
BA_ "GenSigSendType" SG_ 639 EMsHuDPfRegenAckStatus 7;
BA_ "GenSigCycleTimeActive" SG_ 639 EMsHuDPfRegenAckStatus 100;
BA_ "GenSigCycleTime" SG_ 639 EMsHuDPfRegenAckStatus 100;
BA_ "GenSigSendType" SG_ 639 EMsHuDPfRegenAck 7;
BA_ "GenSigCycleTimeActive" SG_ 639 EMsHuDPfRegenAck 100;
BA_ "GenSigCycleTime" SG_ 639 EMsHuDPfRegenAck 100;
BA_ "GenSigSendType" SG_ 639 DPfRegenEnableState 7;
BA_ "GenSigCycleTimeActive" SG_ 639 DPfRegenEnableState 100;
BA_ "GenSigCycleTime" SG_ 639 DPfRegenEnableState 100;
BA_ "GenSigSendType" SG_ 639 EMsHuDPfRegenHMI 7;
BA_ "GenSigCycleTimeActive" SG_ 639 EMsHuDPfRegenHMI 100;
BA_ "GenSigCycleTime" SG_ 639 EMsHuDPfRegenHMI 100;
BA_ "GenSigTimeoutTime_HU_Mid_X451" SG_ 496 FotaIgnOnHoldState 0;
BA_ "GenSigTimeoutTime_HU_High_X451" SG_ 496 FotaIgnOnHoldState 0;
BA_ "GenSigTimeoutTime_HU_B" SG_ 496 FotaIgnOnHoldState 0;
BA_ "GenSigTimeoutTime_HU_A" SG_ 496 FotaIgnOnHoldState 0;
BA_ "GenSigTimeoutMsg_HU_Mid_X451" SG_ 496 FotaIgnOnHoldState 0;
BA_ "GenSigTimeoutMsg_HU_High_X451" SG_ 496 FotaIgnOnHoldState 0;
BA_ "GenSigTimeoutMsg_HU_B" SG_ 496 FotaIgnOnHoldState 0;
BA_ "GenSigTimeoutMsg_HU_A" SG_ 496 FotaIgnOnHoldState 0;
BA_ "GenSigSendType" SG_ 496 FotaIgnOnHoldState 2;
BA_ "GenSigTimeoutMsg_HU_High_X445" SG_ 496 FotaIgnOnHoldState 0;
BA_ "GenSigTimeoutMsg_HU_Mid_X445" SG_ 496 FotaIgnOnHoldState 0;
BA_ "GenSigTimeoutTime_HU_High_X445" SG_ 496 FotaIgnOnHoldState 0;
BA_ "GenSigTimeoutTime_HU_Mid_X445" SG_ 496 FotaIgnOnHoldState 0;
BA_ "GenSigTimeoutMsg_IVI" SG_ 496 FotaIgnOnHoldState 0;
BA_ "GenSigTimeoutTime_IVI" SG_ 496 FotaIgnOnHoldState 0;
BA_ "GenSigTimeoutTime_HU_Mid_X451" SG_ 496 FotaUserReConfirmAck 0;
BA_ "GenSigTimeoutTime_HU_High_X451" SG_ 496 FotaUserReConfirmAck 0;
BA_ "GenSigTimeoutTime_HU_B" SG_ 496 FotaUserReConfirmAck 0;
BA_ "GenSigTimeoutTime_HU_A" SG_ 496 FotaUserReConfirmAck 0;
BA_ "GenSigTimeoutMsg_HU_Mid_X451" SG_ 496 FotaUserReConfirmAck 0;
BA_ "GenSigTimeoutMsg_HU_High_X451" SG_ 496 FotaUserReConfirmAck 0;
BA_ "GenSigTimeoutMsg_HU_B" SG_ 496 FotaUserReConfirmAck 0;
BA_ "GenSigTimeoutMsg_HU_A" SG_ 496 FotaUserReConfirmAck 0;
BA_ "GenSigSendType" SG_ 496 FotaUserReConfirmAck 2;
BA_ "GenSigTimeoutMsg_HU_High_X445" SG_ 496 FotaUserReConfirmAck 0;
BA_ "GenSigTimeoutMsg_HU_Mid_X445" SG_ 496 FotaUserReConfirmAck 0;
BA_ "GenSigTimeoutTime_HU_High_X445" SG_ 496 FotaUserReConfirmAck 0;
BA_ "GenSigTimeoutTime_HU_Mid_X445" SG_ 496 FotaUserReConfirmAck 0;
BA_ "GenSigTimeoutMsg_IVI" SG_ 496 FotaUserReConfirmAck 0;
BA_ "GenSigTimeoutTime_IVI" SG_ 496 FotaUserReConfirmAck 0;
BA_ "GenSigTimeoutTime_HU_Mid_X451" SG_ 496 FotaUserConfirmAck 0;
BA_ "GenSigTimeoutTime_HU_High_X451" SG_ 496 FotaUserConfirmAck 0;
BA_ "GenSigTimeoutTime_HU_B" SG_ 496 FotaUserConfirmAck 0;
BA_ "GenSigTimeoutTime_HU_A" SG_ 496 FotaUserConfirmAck 0;
BA_ "GenSigTimeoutMsg_HU_Mid_X451" SG_ 496 FotaUserConfirmAck 0;
BA_ "GenSigTimeoutMsg_HU_High_X451" SG_ 496 FotaUserConfirmAck 0;
BA_ "GenSigTimeoutMsg_HU_B" SG_ 496 FotaUserConfirmAck 0;
BA_ "GenSigTimeoutMsg_HU_A" SG_ 496 FotaUserConfirmAck 0;
BA_ "GenSigSendType" SG_ 496 FotaUserConfirmAck 2;
BA_ "GenSigTimeoutMsg_HU_High_X445" SG_ 496 FotaUserConfirmAck 0;
BA_ "GenSigTimeoutMsg_HU_Mid_X445" SG_ 496 FotaUserConfirmAck 0;
BA_ "GenSigTimeoutTime_HU_High_X445" SG_ 496 FotaUserConfirmAck 0;
BA_ "GenSigTimeoutTime_HU_Mid_X445" SG_ 496 FotaUserConfirmAck 0;
BA_ "GenSigTimeoutMsg_IVI" SG_ 496 FotaUserConfirmAck 0;
BA_ "GenSigTimeoutTime_IVI" SG_ 496 FotaUserConfirmAck 0;
BA_ "GenSigTimeoutTime_HU_Mid_X451" SG_ 496 FotaEcuId 0;
BA_ "GenSigTimeoutTime_HU_High_X451" SG_ 496 FotaEcuId 0;
BA_ "GenSigTimeoutTime_HU_B" SG_ 496 FotaEcuId 0;
BA_ "GenSigTimeoutTime_HU_A" SG_ 496 FotaEcuId 0;
BA_ "GenSigTimeoutMsg_HU_Mid_X451" SG_ 496 FotaEcuId 0;
BA_ "GenSigTimeoutMsg_HU_High_X451" SG_ 496 FotaEcuId 0;
BA_ "GenSigTimeoutMsg_HU_B" SG_ 496 FotaEcuId 0;
BA_ "GenSigTimeoutMsg_HU_A" SG_ 496 FotaEcuId 0;
BA_ "GenSigSendType" SG_ 496 FotaEcuId 2;
BA_ "GenSigTimeoutMsg_HU_High_X445" SG_ 496 FotaEcuId 0;
BA_ "GenSigTimeoutMsg_HU_Mid_X445" SG_ 496 FotaEcuId 0;
BA_ "GenSigTimeoutTime_HU_High_X445" SG_ 496 FotaEcuId 0;
BA_ "GenSigTimeoutTime_HU_Mid_X445" SG_ 496 FotaEcuId 0;
BA_ "GenSigTimeoutMsg_IVI" SG_ 496 FotaEcuId 0;
BA_ "GenSigTimeoutTime_IVI" SG_ 496 FotaEcuId 0;
BA_ "GenSigTimeoutTime_HU_Mid_X451" SG_ 496 FotaEstimatedUpdateTime 0;
BA_ "GenSigTimeoutTime_HU_High_X451" SG_ 496 FotaEstimatedUpdateTime 0;
BA_ "GenSigTimeoutTime_HU_B" SG_ 496 FotaEstimatedUpdateTime 0;
BA_ "GenSigTimeoutTime_HU_A" SG_ 496 FotaEstimatedUpdateTime 0;
BA_ "GenSigTimeoutMsg_HU_Mid_X451" SG_ 496 FotaEstimatedUpdateTime 0;
BA_ "GenSigTimeoutMsg_HU_High_X451" SG_ 496 FotaEstimatedUpdateTime 0;
BA_ "GenSigTimeoutMsg_HU_B" SG_ 496 FotaEstimatedUpdateTime 0;
BA_ "GenSigTimeoutMsg_HU_A" SG_ 496 FotaEstimatedUpdateTime 0;
BA_ "GenSigSendType" SG_ 496 FotaEstimatedUpdateTime 2;
BA_ "GenSigTimeoutMsg_HU_High_X445" SG_ 496 FotaEstimatedUpdateTime 0;
BA_ "GenSigTimeoutMsg_HU_Mid_X445" SG_ 496 FotaEstimatedUpdateTime 0;
BA_ "GenSigTimeoutTime_HU_High_X445" SG_ 496 FotaEstimatedUpdateTime 0;
BA_ "GenSigTimeoutTime_HU_Mid_X445" SG_ 496 FotaEstimatedUpdateTime 0;
BA_ "GenSigTimeoutMsg_IVI" SG_ 496 FotaEstimatedUpdateTime 0;
BA_ "GenSigTimeoutTime_IVI" SG_ 496 FotaEstimatedUpdateTime 0;
BA_ "GenSigTimeoutTime_HU_Mid_X451" SG_ 496 FotaUpdateType 0;
BA_ "GenSigTimeoutTime_HU_High_X451" SG_ 496 FotaUpdateType 0;
BA_ "GenSigTimeoutTime_HU_B" SG_ 496 FotaUpdateType 0;
BA_ "GenSigTimeoutTime_HU_A" SG_ 496 FotaUpdateType 0;
BA_ "GenSigTimeoutMsg_HU_Mid_X451" SG_ 496 FotaUpdateType 0;
BA_ "GenSigTimeoutMsg_HU_High_X451" SG_ 496 FotaUpdateType 0;
BA_ "GenSigTimeoutMsg_HU_B" SG_ 496 FotaUpdateType 0;
BA_ "GenSigTimeoutMsg_HU_A" SG_ 496 FotaUpdateType 0;
BA_ "GenSigSendType" SG_ 496 FotaUpdateType 2;
BA_ "GenSigTimeoutMsg_HU_High_X445" SG_ 496 FotaUpdateType 0;
BA_ "GenSigTimeoutMsg_HU_Mid_X445" SG_ 496 FotaUpdateType 0;
BA_ "GenSigTimeoutTime_HU_High_X445" SG_ 496 FotaUpdateType 0;
BA_ "GenSigTimeoutTime_HU_Mid_X445" SG_ 496 FotaUpdateType 0;
BA_ "GenSigTimeoutMsg_IVI" SG_ 496 FotaUpdateType 0;
BA_ "GenSigTimeoutTime_IVI" SG_ 496 FotaUpdateType 0;
BA_ "GenSigTimeoutTime_HU_Mid_X451" SG_ 1123 TcmHuVoiceCommandData 0;
BA_ "GenSigTimeoutTime_HU_High_X451" SG_ 1123 TcmHuVoiceCommandData 0;
BA_ "GenSigTimeoutTime_HU_B" SG_ 1123 TcmHuVoiceCommandData 0;
BA_ "GenSigTimeoutTime_HU_A" SG_ 1123 TcmHuVoiceCommandData 0;
BA_ "GenSigTimeoutMsg_HU_Mid_X451" SG_ 1123 TcmHuVoiceCommandData 0;
BA_ "GenSigTimeoutMsg_HU_High_X451" SG_ 1123 TcmHuVoiceCommandData 0;
BA_ "GenSigTimeoutMsg_HU_B" SG_ 1123 TcmHuVoiceCommandData 0;
BA_ "GenSigTimeoutMsg_HU_A" SG_ 1123 TcmHuVoiceCommandData 0;
BA_ "GenSigSendType" SG_ 1123 TcmHuVoiceCommandData 1;
BA_ "GenSigTimeoutMsg_HU_High_X445" SG_ 1123 TcmHuVoiceCommandData 0;
BA_ "GenSigTimeoutMsg_HU_Mid_X445" SG_ 1123 TcmHuVoiceCommandData 0;
BA_ "GenSigTimeoutTime_HU_High_X445" SG_ 1123 TcmHuVoiceCommandData 0;
BA_ "GenSigTimeoutTime_HU_Mid_X445" SG_ 1123 TcmHuVoiceCommandData 0;
BA_ "GenSigTimeoutMsg_IVI" SG_ 1123 TcmHuVoiceCommandData 0;
BA_ "GenSigTimeoutTime_IVI" SG_ 1123 TcmHuVoiceCommandData 0;
BA_ "GenSigTimeoutTime_HU_Mid_X451" SG_ 1122 HuTcmVoiceCommandDataAck 0;
BA_ "GenSigTimeoutTime_HU_High_X451" SG_ 1122 HuTcmVoiceCommandDataAck 0;
BA_ "GenSigTimeoutTime_HU_B" SG_ 1122 HuTcmVoiceCommandDataAck 0;
BA_ "GenSigTimeoutTime_HU_A" SG_ 1122 HuTcmVoiceCommandDataAck 0;
BA_ "GenSigTimeoutMsg_HU_Mid_X451" SG_ 1122 HuTcmVoiceCommandDataAck 0;
BA_ "GenSigTimeoutMsg_HU_High_X451" SG_ 1122 HuTcmVoiceCommandDataAck 0;
BA_ "GenSigTimeoutMsg_HU_B" SG_ 1122 HuTcmVoiceCommandDataAck 0;
BA_ "GenSigTimeoutMsg_HU_A" SG_ 1122 HuTcmVoiceCommandDataAck 0;
BA_ "GenSigSendType" SG_ 1122 HuTcmVoiceCommandDataAck 1;
BA_ "GenSigTimeoutMsg_HU_High_X445" SG_ 1122 HuTcmVoiceCommandDataAck 0;
BA_ "GenSigTimeoutMsg_HU_Mid_X445" SG_ 1122 HuTcmVoiceCommandDataAck 0;
BA_ "GenSigTimeoutTime_HU_High_X445" SG_ 1122 HuTcmVoiceCommandDataAck 0;
BA_ "GenSigTimeoutTime_HU_Mid_X445" SG_ 1122 HuTcmVoiceCommandDataAck 0;
BA_ "GenSigTimeoutMsg_IVI" SG_ 1122 HuTcmVoiceCommandDataAck 0;
BA_ "GenSigTimeoutTime_IVI" SG_ 1122 HuTcmVoiceCommandDataAck 0;
BA_ "GenSigTimeoutTime_HU_Mid_X451" SG_ 584 BatteryCoolingSolValveState 0;
BA_ "GenSigTimeoutTime_HU_High_X451" SG_ 584 BatteryCoolingSolValveState 0;
BA_ "GenSigTimeoutTime_HU_B" SG_ 584 BatteryCoolingSolValveState 0;
BA_ "GenSigTimeoutTime_HU_A" SG_ 584 BatteryCoolingSolValveState 0;
BA_ "GenSigTimeoutMsg_HU_Mid_X451" SG_ 584 BatteryCoolingSolValveState 0;
BA_ "GenSigTimeoutMsg_HU_High_X451" SG_ 584 BatteryCoolingSolValveState 0;
BA_ "GenSigTimeoutMsg_HU_B" SG_ 584 BatteryCoolingSolValveState 0;
BA_ "GenSigTimeoutMsg_HU_A" SG_ 584 BatteryCoolingSolValveState 0;
BA_ "GenSigSendType" SG_ 584 BatteryCoolingSolValveState 7;
BA_ "GenSigCycleTimeActive" SG_ 584 BatteryCoolingSolValveState 100;
BA_ "GenSigCycleTime" SG_ 584 BatteryCoolingSolValveState 100;
BA_ "GenSigTimeoutTime_HU_Mid_X451" SG_ 584 RegenPowerConsumption 0;
BA_ "GenSigTimeoutTime_HU_High_X451" SG_ 584 RegenPowerConsumption 0;
BA_ "GenSigTimeoutTime_HU_B" SG_ 584 RegenPowerConsumption 0;
BA_ "GenSigTimeoutTime_HU_A" SG_ 584 RegenPowerConsumption 0;
BA_ "GenSigTimeoutMsg_HU_Mid_X451" SG_ 584 RegenPowerConsumption 0;
BA_ "GenSigTimeoutMsg_HU_High_X451" SG_ 584 RegenPowerConsumption 0;
BA_ "GenSigTimeoutMsg_HU_B" SG_ 584 RegenPowerConsumption 0;
BA_ "GenSigTimeoutMsg_HU_A" SG_ 584 RegenPowerConsumption 0;
BA_ "GenSigSendType" SG_ 584 RegenPowerConsumption 7;
BA_ "GenSigCycleTimeActive" SG_ 584 RegenPowerConsumption 100;
BA_ "GenSigCycleTime" SG_ 584 RegenPowerConsumption 100;
BA_ "GenSigTimeoutTime_HU_Mid_X451" SG_ 584 EnerConsumptionCol 0;
BA_ "GenSigTimeoutTime_HU_High_X451" SG_ 584 EnerConsumptionCol 0;
BA_ "GenSigTimeoutTime_HU_B" SG_ 584 EnerConsumptionCol 0;
BA_ "GenSigTimeoutTime_HU_A" SG_ 584 EnerConsumptionCol 0;
BA_ "GenSigTimeoutMsg_HU_Mid_X451" SG_ 584 EnerConsumptionCol 0;
BA_ "GenSigTimeoutMsg_HU_High_X451" SG_ 584 EnerConsumptionCol 0;
BA_ "GenSigTimeoutMsg_HU_B" SG_ 584 EnerConsumptionCol 0;
BA_ "GenSigTimeoutMsg_HU_A" SG_ 584 EnerConsumptionCol 0;
BA_ "GenSigSendType" SG_ 584 EnerConsumptionCol 7;
BA_ "GenSigCycleTimeActive" SG_ 584 EnerConsumptionCol 100;
BA_ "GenSigCycleTime" SG_ 584 EnerConsumptionCol 100;
BA_ "GenSigTimeoutTime_HU_Mid_X451" SG_ 584 EnerConsumptionAux 0;
BA_ "GenSigTimeoutTime_HU_High_X451" SG_ 584 EnerConsumptionAux 0;
BA_ "GenSigTimeoutTime_HU_B" SG_ 584 EnerConsumptionAux 0;
BA_ "GenSigTimeoutTime_HU_A" SG_ 584 EnerConsumptionAux 0;
BA_ "GenSigTimeoutMsg_HU_Mid_X451" SG_ 584 EnerConsumptionAux 0;
BA_ "GenSigTimeoutMsg_HU_High_X451" SG_ 584 EnerConsumptionAux 0;
BA_ "GenSigTimeoutMsg_HU_B" SG_ 584 EnerConsumptionAux 0;
BA_ "GenSigTimeoutMsg_HU_A" SG_ 584 EnerConsumptionAux 0;
BA_ "GenSigSendType" SG_ 584 EnerConsumptionAux 7;
BA_ "GenSigCycleTimeActive" SG_ 584 EnerConsumptionAux 100;
BA_ "GenSigCycleTime" SG_ 584 EnerConsumptionAux 100;
BA_ "GenSigTimeoutTime_HU_Mid_X451" SG_ 584 EnerConsumptionDrive 0;
BA_ "GenSigTimeoutTime_HU_High_X451" SG_ 584 EnerConsumptionDrive 0;
BA_ "GenSigTimeoutTime_HU_B" SG_ 584 EnerConsumptionDrive 0;
BA_ "GenSigTimeoutTime_HU_A" SG_ 584 EnerConsumptionDrive 0;
BA_ "GenSigTimeoutMsg_HU_Mid_X451" SG_ 584 EnerConsumptionDrive 0;
BA_ "GenSigTimeoutMsg_HU_High_X451" SG_ 584 EnerConsumptionDrive 0;
BA_ "GenSigTimeoutMsg_HU_B" SG_ 584 EnerConsumptionDrive 0;
BA_ "GenSigTimeoutMsg_HU_A" SG_ 584 EnerConsumptionDrive 0;
BA_ "GenSigSendType" SG_ 584 EnerConsumptionDrive 7;
BA_ "GenSigCycleTimeActive" SG_ 584 EnerConsumptionDrive 100;
BA_ "GenSigCycleTime" SG_ 584 EnerConsumptionDrive 100;
BA_ "GenSigTimeoutTime_HU_Mid_X451" SG_ 354 TorqueReductionRequestStatus 0;
BA_ "GenSigTimeoutTime_HU_High_X451" SG_ 354 TorqueReductionRequestStatus 0;
BA_ "GenSigTimeoutTime_HU_B" SG_ 354 TorqueReductionRequestStatus 0;
BA_ "GenSigTimeoutTime_HU_A" SG_ 354 TorqueReductionRequestStatus 0;
BA_ "GenSigTimeoutMsg_HU_Mid_X451" SG_ 354 TorqueReductionRequestStatus 0;
BA_ "GenSigTimeoutMsg_HU_High_X451" SG_ 354 TorqueReductionRequestStatus 0;
BA_ "GenSigTimeoutMsg_HU_B" SG_ 354 TorqueReductionRequestStatus 0;
BA_ "GenSigTimeoutMsg_HU_A" SG_ 354 TorqueReductionRequestStatus 0;
BA_ "GenSigSendType" SG_ 354 TorqueReductionRequestStatus 7;
BA_ "GenSigCycleTimeActive" SG_ 354 TorqueReductionRequestStatus 20;
BA_ "GenSigCycleTime" SG_ 354 TorqueReductionRequestStatus 20;
BA_ "GenSigTimeoutMsg_HU_High_X445" SG_ 354 TorqueReductionRequestStatus 0;
BA_ "GenSigTimeoutMsg_HU_Mid_X445" SG_ 354 TorqueReductionRequestStatus 0;
BA_ "GenSigTimeoutMsg_IVI" SG_ 354 TorqueReductionRequestStatus 0;
BA_ "GenSigTimeoutTime_HU_Mid_X451" SG_ 354 TorqueReductionRequest 0;
BA_ "GenSigTimeoutTime_HU_High_X451" SG_ 354 TorqueReductionRequest 0;
BA_ "GenSigTimeoutTime_HU_B" SG_ 354 TorqueReductionRequest 0;
BA_ "GenSigTimeoutTime_HU_A" SG_ 354 TorqueReductionRequest 0;
BA_ "GenSigTimeoutMsg_HU_Mid_X451" SG_ 354 TorqueReductionRequest 0;
BA_ "GenSigTimeoutMsg_HU_High_X451" SG_ 354 TorqueReductionRequest 0;
BA_ "GenSigTimeoutMsg_HU_B" SG_ 354 TorqueReductionRequest 0;
BA_ "GenSigTimeoutMsg_HU_A" SG_ 354 TorqueReductionRequest 0;
BA_ "GenSigSendType" SG_ 354 TorqueReductionRequest 7;
BA_ "GenSigCycleTimeActive" SG_ 354 TorqueReductionRequest 20;
BA_ "GenSigCycleTime" SG_ 354 TorqueReductionRequest 20;
BA_ "GenSigTimeoutMsg_HU_High_X445" SG_ 354 TorqueReductionRequest 0;
BA_ "GenSigTimeoutMsg_HU_Mid_X445" SG_ 354 TorqueReductionRequest 0;
BA_ "GenSigTimeoutMsg_IVI" SG_ 354 TorqueReductionRequest 0;
BA_ "GenSigTimeoutTime_HU_Mid_X451" SG_ 354 AutoLockModeState 0;
BA_ "GenSigTimeoutTime_HU_High_X451" SG_ 354 AutoLockModeState 0;
BA_ "GenSigTimeoutTime_HU_B" SG_ 354 AutoLockModeState 0;
BA_ "GenSigTimeoutTime_HU_A" SG_ 354 AutoLockModeState 0;
BA_ "GenSigTimeoutMsg_HU_Mid_X451" SG_ 354 AutoLockModeState 0;
BA_ "GenSigTimeoutMsg_HU_High_X451" SG_ 354 AutoLockModeState 0;
BA_ "GenSigTimeoutMsg_HU_B" SG_ 354 AutoLockModeState 0;
BA_ "GenSigTimeoutMsg_HU_A" SG_ 354 AutoLockModeState 0;
BA_ "GenSigSendType" SG_ 354 AutoLockModeState 7;
BA_ "GenSigCycleTimeActive" SG_ 354 AutoLockModeState 20;
BA_ "GenSigCycleTime" SG_ 354 AutoLockModeState 20;
BA_ "GenSigTimeoutMsg_HU_High_X445" SG_ 354 AutoLockModeState 0;
BA_ "GenSigTimeoutMsg_HU_Mid_X445" SG_ 354 AutoLockModeState 0;
BA_ "GenSigTimeoutMsg_IVI" SG_ 354 AutoLockModeState 0;
BA_ "GenSigTimeoutTime_HU_Mid_X451" SG_ 354 CAnBusFault 0;
BA_ "GenSigTimeoutTime_HU_High_X451" SG_ 354 CAnBusFault 0;
BA_ "GenSigTimeoutTime_HU_B" SG_ 354 CAnBusFault 0;
BA_ "GenSigTimeoutTime_HU_A" SG_ 354 CAnBusFault 0;
BA_ "GenSigTimeoutMsg_HU_Mid_X451" SG_ 354 CAnBusFault 0;
BA_ "GenSigTimeoutMsg_HU_High_X451" SG_ 354 CAnBusFault 0;
BA_ "GenSigTimeoutMsg_HU_B" SG_ 354 CAnBusFault 0;
BA_ "GenSigTimeoutMsg_HU_A" SG_ 354 CAnBusFault 0;
BA_ "GenSigSendType" SG_ 354 CAnBusFault 7;
BA_ "GenSigCycleTimeActive" SG_ 354 CAnBusFault 20;
BA_ "GenSigCycleTime" SG_ 354 CAnBusFault 20;
BA_ "GenSigTimeoutMsg_HU_High_X445" SG_ 354 CAnBusFault 0;
BA_ "GenSigTimeoutMsg_HU_Mid_X445" SG_ 354 CAnBusFault 0;
BA_ "GenSigTimeoutMsg_IVI" SG_ 354 CAnBusFault 0;
BA_ "GenSigTimeoutTime_HU_Mid_X451" SG_ 354 TodFault 0;
BA_ "GenSigTimeoutTime_HU_High_X451" SG_ 354 TodFault 0;
BA_ "GenSigTimeoutTime_HU_B" SG_ 354 TodFault 0;
BA_ "GenSigTimeoutTime_HU_A" SG_ 354 TodFault 0;
BA_ "GenSigTimeoutMsg_HU_Mid_X451" SG_ 354 TodFault 0;
BA_ "GenSigTimeoutMsg_HU_High_X451" SG_ 354 TodFault 0;
BA_ "GenSigTimeoutMsg_HU_B" SG_ 354 TodFault 0;
BA_ "GenSigTimeoutMsg_HU_A" SG_ 354 TodFault 0;
BA_ "GenSigSendType" SG_ 354 TodFault 7;
BA_ "GenSigCycleTimeActive" SG_ 354 TodFault 20;
BA_ "GenSigCycleTime" SG_ 354 TodFault 20;
BA_ "GenSigTimeoutMsg_HU_High_X445" SG_ 354 TodFault 0;
BA_ "GenSigTimeoutMsg_HU_Mid_X445" SG_ 354 TodFault 0;
BA_ "GenSigTimeoutMsg_IVI" SG_ 354 TodFault 0;
BA_ "GenSigTimeoutTime_HU_Mid_X451" SG_ 354 TorqueOutputStatus 0;
BA_ "GenSigTimeoutTime_HU_High_X451" SG_ 354 TorqueOutputStatus 0;
BA_ "GenSigTimeoutTime_HU_B" SG_ 354 TorqueOutputStatus 0;
BA_ "GenSigTimeoutTime_HU_A" SG_ 354 TorqueOutputStatus 0;
BA_ "GenSigTimeoutMsg_HU_Mid_X451" SG_ 354 TorqueOutputStatus 0;
BA_ "GenSigTimeoutMsg_HU_High_X451" SG_ 354 TorqueOutputStatus 0;
BA_ "GenSigTimeoutMsg_HU_B" SG_ 354 TorqueOutputStatus 0;
BA_ "GenSigTimeoutMsg_HU_A" SG_ 354 TorqueOutputStatus 0;
BA_ "GenSigSendType" SG_ 354 TorqueOutputStatus 7;
BA_ "GenSigCycleTimeActive" SG_ 354 TorqueOutputStatus 20;
BA_ "GenSigCycleTime" SG_ 354 TorqueOutputStatus 20;
BA_ "GenSigTimeoutMsg_HU_High_X445" SG_ 354 TorqueOutputStatus 0;
BA_ "GenSigTimeoutMsg_HU_Mid_X445" SG_ 354 TorqueOutputStatus 0;
BA_ "GenSigTimeoutMsg_IVI" SG_ 354 TorqueOutputStatus 0;
BA_ "GenSigTimeoutTime_HU_Mid_X451" SG_ 354 TorqueOutput 0;
BA_ "GenSigTimeoutTime_HU_High_X451" SG_ 354 TorqueOutput 0;
BA_ "GenSigTimeoutTime_HU_B" SG_ 354 TorqueOutput 0;
BA_ "GenSigTimeoutTime_HU_A" SG_ 354 TorqueOutput 0;
BA_ "GenSigTimeoutMsg_HU_Mid_X451" SG_ 354 TorqueOutput 0;
BA_ "GenSigTimeoutMsg_HU_High_X451" SG_ 354 TorqueOutput 0;
BA_ "GenSigTimeoutMsg_HU_B" SG_ 354 TorqueOutput 0;
BA_ "GenSigTimeoutMsg_HU_A" SG_ 354 TorqueOutput 0;
BA_ "GenSigSendType" SG_ 354 TorqueOutput 7;
BA_ "GenSigCycleTimeActive" SG_ 354 TorqueOutput 20;
BA_ "GenSigCycleTime" SG_ 354 TorqueOutput 20;
BA_ "GenSigTimeoutMsg_HU_High_X445" SG_ 354 TorqueOutput 0;
BA_ "GenSigTimeoutMsg_HU_Mid_X445" SG_ 354 TorqueOutput 0;
BA_ "GenSigTimeoutMsg_IVI" SG_ 354 TorqueOutput 0;
BA_ "GenSigTimeoutTime_HU_Mid_X451" SG_ 1592 GSS_DiagResponse_UUDT 0;
BA_ "GenSigTimeoutTime_HU_High_X451" SG_ 1592 GSS_DiagResponse_UUDT 0;
BA_ "GenSigTimeoutTime_HU_B" SG_ 1592 GSS_DiagResponse_UUDT 0;
BA_ "GenSigTimeoutTime_HU_A" SG_ 1592 GSS_DiagResponse_UUDT 0;
BA_ "GenSigTimeoutMsg_HU_Mid_X451" SG_ 1592 GSS_DiagResponse_UUDT 0;
BA_ "GenSigTimeoutMsg_HU_High_X451" SG_ 1592 GSS_DiagResponse_UUDT 0;
BA_ "GenSigTimeoutMsg_HU_B" SG_ 1592 GSS_DiagResponse_UUDT 0;
BA_ "GenSigTimeoutMsg_HU_A" SG_ 1592 GSS_DiagResponse_UUDT 0;
BA_ "GenSigSendType" SG_ 1592 GSS_DiagResponse_UUDT 1;
BA_ "GenSigTimeoutMsg_HU_High_X445" SG_ 1592 GSS_DiagResponse_UUDT 0;
BA_ "GenSigTimeoutMsg_HU_Mid_X445" SG_ 1592 GSS_DiagResponse_UUDT 0;
BA_ "GenSigTimeoutTime_HU_High_X445" SG_ 1592 GSS_DiagResponse_UUDT 0;
BA_ "GenSigTimeoutTime_HU_Mid_X445" SG_ 1592 GSS_DiagResponse_UUDT 0;
BA_ "GenSigTimeoutMsg_IVI" SG_ 1592 GSS_DiagResponse_UUDT 0;
BA_ "GenSigTimeoutTime_IVI" SG_ 1592 GSS_DiagResponse_UUDT 0;
BA_ "GenSigTimeoutTime_HU_Mid_X451" SG_ 1848 GSS_DiagResponse_USDT 0;
BA_ "GenSigTimeoutTime_HU_High_X451" SG_ 1848 GSS_DiagResponse_USDT 0;
BA_ "GenSigTimeoutTime_HU_B" SG_ 1848 GSS_DiagResponse_USDT 0;
BA_ "GenSigTimeoutTime_HU_A" SG_ 1848 GSS_DiagResponse_USDT 0;
BA_ "GenSigTimeoutMsg_HU_Mid_X451" SG_ 1848 GSS_DiagResponse_USDT 0;
BA_ "GenSigTimeoutMsg_HU_High_X451" SG_ 1848 GSS_DiagResponse_USDT 0;
BA_ "GenSigTimeoutMsg_HU_B" SG_ 1848 GSS_DiagResponse_USDT 0;
BA_ "GenSigTimeoutMsg_HU_A" SG_ 1848 GSS_DiagResponse_USDT 0;
BA_ "GenSigSendType" SG_ 1848 GSS_DiagResponse_USDT 1;
BA_ "GenSigTimeoutMsg_HU_High_X445" SG_ 1848 GSS_DiagResponse_USDT 0;
BA_ "GenSigTimeoutMsg_HU_Mid_X445" SG_ 1848 GSS_DiagResponse_USDT 0;
BA_ "GenSigTimeoutTime_HU_High_X445" SG_ 1848 GSS_DiagResponse_USDT 0;
BA_ "GenSigTimeoutTime_HU_Mid_X445" SG_ 1848 GSS_DiagResponse_USDT 0;
BA_ "GenSigTimeoutMsg_IVI" SG_ 1848 GSS_DiagResponse_USDT 0;
BA_ "GenSigTimeoutTime_IVI" SG_ 1848 GSS_DiagResponse_USDT 0;
BA_ "GenSigTimeoutTime_HU_Mid_X451" SG_ 1840 GSS_DiagRequest 0;
BA_ "GenSigTimeoutTime_HU_High_X451" SG_ 1840 GSS_DiagRequest 0;
BA_ "GenSigTimeoutTime_HU_B" SG_ 1840 GSS_DiagRequest 0;
BA_ "GenSigTimeoutTime_HU_A" SG_ 1840 GSS_DiagRequest 0;
BA_ "GenSigTimeoutMsg_HU_Mid_X451" SG_ 1840 GSS_DiagRequest 0;
BA_ "GenSigTimeoutMsg_HU_High_X451" SG_ 1840 GSS_DiagRequest 0;
BA_ "GenSigTimeoutMsg_HU_B" SG_ 1840 GSS_DiagRequest 0;
BA_ "GenSigTimeoutMsg_HU_A" SG_ 1840 GSS_DiagRequest 0;
BA_ "GenSigSendType" SG_ 1840 GSS_DiagRequest 1;
BA_ "GenSigTimeoutMsg_HU_High_X445" SG_ 1840 GSS_DiagRequest 0;
BA_ "GenSigTimeoutMsg_HU_Mid_X445" SG_ 1840 GSS_DiagRequest 0;
BA_ "GenSigTimeoutTime_HU_High_X445" SG_ 1840 GSS_DiagRequest 0;
BA_ "GenSigTimeoutTime_HU_Mid_X445" SG_ 1840 GSS_DiagRequest 0;
BA_ "GenSigTimeoutMsg_IVI" SG_ 1840 GSS_DiagRequest 0;
BA_ "GenSigTimeoutTime_IVI" SG_ 1840 GSS_DiagRequest 0;
BA_ "GenSigSendType" SG_ 728 DustSensorOperation 7;
BA_ "GenSigCycleTimeActive" SG_ 728 DustSensorOperation 100;
BA_ "GenSigCycleTime" SG_ 728 DustSensorOperation 100;
BA_ "GenSigSendType" SG_ 728 DustSensorButtonOnOff 7;
BA_ "GenSigCycleTimeActive" SG_ 728 DustSensorButtonOnOff 100;
BA_ "GenSigCycleTime" SG_ 728 DustSensorButtonOnOff 100;
BA_ "GenSigSendType" SG_ 728 CCmHuDustConcentrationStatus 7;
BA_ "GenSigCycleTimeActive" SG_ 728 CCmHuDustConcentrationStatus 100;
BA_ "GenSigCycleTime" SG_ 728 CCmHuDustConcentrationStatus 100;
BA_ "GenSigSendType" SG_ 728 CCmHuDustConcentration 7;
BA_ "GenSigCycleTimeActive" SG_ 728 CCmHuDustConcentration 100;
BA_ "GenSigCycleTime" SG_ 728 CCmHuDustConcentration 100;
BA_ "GenSigSendType" SG_ 728 CCmHuAqiLevel 7;
BA_ "GenSigCycleTimeActive" SG_ 728 CCmHuAqiLevel 100;
BA_ "GenSigCycleTime" SG_ 728 CCmHuAqiLevel 100;
BA_ "GenSigSendType" SG_ 728 CCmHuDominantPollutantValue 7;
BA_ "GenSigCycleTimeActive" SG_ 728 CCmHuDominantPollutantValue 100;
BA_ "GenSigCycleTime" SG_ 728 CCmHuDominantPollutantValue 100;
BA_ "GenSigSendType" SG_ 728 CCmHuAqiValue 7;
BA_ "GenSigCycleTimeActive" SG_ 728 CCmHuAqiValue 100;
BA_ "GenSigCycleTime" SG_ 728 CCmHuAqiValue 100;
BA_ "GenSigSendType" SG_ 728 CCmHuAqiValueStatus 7;
BA_ "GenSigCycleTimeActive" SG_ 728 CCmHuAqiValueStatus 100;
BA_ "GenSigCycleTime" SG_ 728 CCmHuAqiValueStatus 100;
BA_ "GenSigSendType" SG_ 728 CCmHuAqiAutolearning 7;
BA_ "GenSigCycleTimeActive" SG_ 728 CCmHuAqiAutolearning 100;
BA_ "GenSigCycleTime" SG_ 728 CCmHuAqiAutolearning 100;
BA_ "GenSigTimeoutTime_HU_Mid_X451" SG_ 275 DriverReqTrqStatus 0;
BA_ "GenSigTimeoutTime_HU_High_X451" SG_ 275 DriverReqTrqStatus 0;
BA_ "GenSigTimeoutTime_HU_B" SG_ 275 DriverReqTrqStatus 0;
BA_ "GenSigTimeoutTime_HU_A" SG_ 275 DriverReqTrqStatus 0;
BA_ "GenSigTimeoutMsg_HU_Mid_X451" SG_ 275 DriverReqTrqStatus 0;
BA_ "GenSigTimeoutMsg_HU_High_X451" SG_ 275 DriverReqTrqStatus 0;
BA_ "GenSigTimeoutMsg_HU_B" SG_ 275 DriverReqTrqStatus 0;
BA_ "GenSigTimeoutMsg_HU_A" SG_ 275 DriverReqTrqStatus 0;
BA_ "GenSigSendType" SG_ 275 DriverReqTrqStatus 7;
BA_ "GenSigCycleTimeActive" SG_ 275 DriverReqTrqStatus 10;
BA_ "GenSigCycleTime" SG_ 275 DriverReqTrqStatus 10;
BA_ "GenSigTimeoutTime_HU_Mid_X451" SG_ 275 DriverReqTrq 0;
BA_ "GenSigTimeoutTime_HU_High_X451" SG_ 275 DriverReqTrq 0;
BA_ "GenSigTimeoutTime_HU_B" SG_ 275 DriverReqTrq 0;
BA_ "GenSigTimeoutTime_HU_A" SG_ 275 DriverReqTrq 0;
BA_ "GenSigTimeoutMsg_HU_Mid_X451" SG_ 275 DriverReqTrq 0;
BA_ "GenSigTimeoutMsg_HU_High_X451" SG_ 275 DriverReqTrq 0;
BA_ "GenSigTimeoutMsg_HU_B" SG_ 275 DriverReqTrq 0;
BA_ "GenSigTimeoutMsg_HU_A" SG_ 275 DriverReqTrq 0;
BA_ "GenSigStartValue" SG_ 275 DriverReqTrq 8192;
BA_ "GenSigSendType" SG_ 275 DriverReqTrq 7;
BA_ "GenSigCycleTimeActive" SG_ 275 DriverReqTrq 10;
BA_ "GenSigCycleTime" SG_ 275 DriverReqTrq 10;
BA_ "GenSigTimeoutTime_HU_Mid_X451" SG_ 275 RecupBrakeState 0;
BA_ "GenSigTimeoutTime_HU_High_X451" SG_ 275 RecupBrakeState 0;
BA_ "GenSigTimeoutTime_HU_B" SG_ 275 RecupBrakeState 0;
BA_ "GenSigTimeoutTime_HU_A" SG_ 275 RecupBrakeState 0;
BA_ "GenSigTimeoutMsg_HU_Mid_X451" SG_ 275 RecupBrakeState 0;
BA_ "GenSigTimeoutMsg_HU_High_X451" SG_ 275 RecupBrakeState 0;
BA_ "GenSigTimeoutMsg_HU_B" SG_ 275 RecupBrakeState 0;
BA_ "GenSigTimeoutMsg_HU_A" SG_ 275 RecupBrakeState 0;
BA_ "GenSigSendType" SG_ 275 RecupBrakeState 7;
BA_ "GenSigCycleTimeActive" SG_ 275 RecupBrakeState 10;
BA_ "GenSigCycleTime" SG_ 275 RecupBrakeState 10;
BA_ "GenSigTimeoutMsg_HU_High_X445" SG_ 275 RecupBrakeState 0;
BA_ "GenSigTimeoutMsg_HU_Mid_X445" SG_ 275 RecupBrakeState 0;
BA_ "GenSigTimeoutTime_HU_High_X445" SG_ 275 RecupBrakeState 0;
BA_ "GenSigTimeoutTime_HU_Mid_X445" SG_ 275 RecupBrakeState 0;
BA_ "GenSigTimeoutTime_HU_Mid_X451" SG_ 275 MaxAvailableRegenTrqStatus 0;
BA_ "GenSigTimeoutTime_HU_High_X451" SG_ 275 MaxAvailableRegenTrqStatus 0;
BA_ "GenSigTimeoutTime_HU_B" SG_ 275 MaxAvailableRegenTrqStatus 0;
BA_ "GenSigTimeoutTime_HU_A" SG_ 275 MaxAvailableRegenTrqStatus 0;
BA_ "GenSigTimeoutMsg_HU_Mid_X451" SG_ 275 MaxAvailableRegenTrqStatus 0;
BA_ "GenSigTimeoutMsg_HU_High_X451" SG_ 275 MaxAvailableRegenTrqStatus 0;
BA_ "GenSigTimeoutMsg_HU_B" SG_ 275 MaxAvailableRegenTrqStatus 0;
BA_ "GenSigTimeoutMsg_HU_A" SG_ 275 MaxAvailableRegenTrqStatus 0;
BA_ "GenSigSendType" SG_ 275 MaxAvailableRegenTrqStatus 7;
BA_ "GenSigCycleTimeActive" SG_ 275 MaxAvailableRegenTrqStatus 10;
BA_ "GenSigCycleTime" SG_ 275 MaxAvailableRegenTrqStatus 10;
BA_ "GenSigTimeoutTime_HU_Mid_X451" SG_ 275 MaxAvailableRegenTrq 0;
BA_ "GenSigTimeoutTime_HU_High_X451" SG_ 275 MaxAvailableRegenTrq 0;
BA_ "GenSigTimeoutTime_HU_B" SG_ 275 MaxAvailableRegenTrq 0;
BA_ "GenSigTimeoutTime_HU_A" SG_ 275 MaxAvailableRegenTrq 0;
BA_ "GenSigTimeoutMsg_HU_Mid_X451" SG_ 275 MaxAvailableRegenTrq 0;
BA_ "GenSigTimeoutMsg_HU_High_X451" SG_ 275 MaxAvailableRegenTrq 0;
BA_ "GenSigTimeoutMsg_HU_B" SG_ 275 MaxAvailableRegenTrq 0;
BA_ "GenSigTimeoutMsg_HU_A" SG_ 275 MaxAvailableRegenTrq 0;
BA_ "GenSigStartValue" SG_ 275 MaxAvailableRegenTrq 8192;
BA_ "GenSigSendType" SG_ 275 MaxAvailableRegenTrq 7;
BA_ "GenSigCycleTimeActive" SG_ 275 MaxAvailableRegenTrq 10;
BA_ "GenSigCycleTime" SG_ 275 MaxAvailableRegenTrq 10;
BA_ "GenSigTimeoutTime_HU_Mid_X451" SG_ 736 VehicleMobilizationStateStatus 0;
BA_ "GenSigTimeoutTime_HU_High_X451" SG_ 736 VehicleMobilizationStateStatus 0;
BA_ "GenSigTimeoutTime_HU_B" SG_ 736 VehicleMobilizationStateStatus 0;
BA_ "GenSigTimeoutTime_HU_A" SG_ 736 VehicleMobilizationStateStatus 0;
BA_ "GenSigTimeoutMsg_HU_Mid_X451" SG_ 736 VehicleMobilizationStateStatus 0;
BA_ "GenSigTimeoutMsg_HU_High_X451" SG_ 736 VehicleMobilizationStateStatus 0;
BA_ "GenSigTimeoutMsg_HU_B" SG_ 736 VehicleMobilizationStateStatus 0;
BA_ "GenSigTimeoutMsg_HU_A" SG_ 736 VehicleMobilizationStateStatus 0;
BA_ "GenSigSendType" SG_ 736 VehicleMobilizationStateStatus 7;
BA_ "GenSigCycleTimeActive" SG_ 736 VehicleMobilizationStateStatus 100;
BA_ "GenSigCycleTime" SG_ 736 VehicleMobilizationStateStatus 100;
BA_ "GenSigTimeoutMsg_HU_High_X445" SG_ 736 VehicleMobilizationStateStatus 0;
BA_ "GenSigTimeoutMsg_HU_Mid_X445" SG_ 736 VehicleMobilizationStateStatus 0;
BA_ "GenSigTimeoutTime_HU_High_X445" SG_ 736 VehicleMobilizationStateStatus 0;
BA_ "GenSigTimeoutTime_HU_Mid_X445" SG_ 736 VehicleMobilizationStateStatus 0;
BA_ "GenSigTimeoutTime_HU_Mid_X451" SG_ 736 VehicleMobilizationState 0;
BA_ "GenSigTimeoutTime_HU_High_X451" SG_ 736 VehicleMobilizationState 0;
BA_ "GenSigTimeoutTime_HU_B" SG_ 736 VehicleMobilizationState 0;
BA_ "GenSigTimeoutTime_HU_A" SG_ 736 VehicleMobilizationState 0;
BA_ "GenSigTimeoutMsg_HU_Mid_X451" SG_ 736 VehicleMobilizationState 0;
BA_ "GenSigTimeoutMsg_HU_High_X451" SG_ 736 VehicleMobilizationState 0;
BA_ "GenSigTimeoutMsg_HU_B" SG_ 736 VehicleMobilizationState 0;
BA_ "GenSigTimeoutMsg_HU_A" SG_ 736 VehicleMobilizationState 0;
BA_ "GenSigStartValue" SG_ 736 VehicleMobilizationState 1;
BA_ "GenSigSendType" SG_ 736 VehicleMobilizationState 7;
BA_ "GenSigCycleTimeActive" SG_ 736 VehicleMobilizationState 100;
BA_ "GenSigCycleTime" SG_ 736 VehicleMobilizationState 100;
BA_ "GenSigTimeoutMsg_HU_High_X445" SG_ 736 VehicleMobilizationState 0;
BA_ "GenSigTimeoutMsg_HU_Mid_X445" SG_ 736 VehicleMobilizationState 0;
BA_ "GenSigTimeoutTime_HU_High_X445" SG_ 736 VehicleMobilizationState 0;
BA_ "GenSigTimeoutTime_HU_Mid_X445" SG_ 736 VehicleMobilizationState 0;
BA_ "GenSigTimeoutTime_HU_Mid_X451" SG_ 467 HuBCmGotoEntryExitPos 0;
BA_ "GenSigTimeoutTime_HU_High_X451" SG_ 467 HuBCmGotoEntryExitPos 0;
BA_ "GenSigTimeoutTime_HU_B" SG_ 467 HuBCmGotoEntryExitPos 0;
BA_ "GenSigTimeoutTime_HU_A" SG_ 467 HuBCmGotoEntryExitPos 0;
BA_ "GenSigTimeoutMsg_HU_Mid_X451" SG_ 467 HuBCmGotoEntryExitPos 0;
BA_ "GenSigTimeoutMsg_HU_High_X451" SG_ 467 HuBCmGotoEntryExitPos 0;
BA_ "GenSigTimeoutMsg_HU_B" SG_ 467 HuBCmGotoEntryExitPos 0;
BA_ "GenSigTimeoutMsg_HU_A" SG_ 467 HuBCmGotoEntryExitPos 0;
BA_ "GenSigSendType" SG_ 467 HuBCmGotoEntryExitPos 2;
BA_ "GenSigTimeoutMsg_HU_High_X445" SG_ 467 HuBCmGotoEntryExitPos 0;
BA_ "GenSigTimeoutMsg_HU_Mid_X445" SG_ 467 HuBCmGotoEntryExitPos 0;
BA_ "GenSigTimeoutTime_HU_High_X445" SG_ 467 HuBCmGotoEntryExitPos 0;
BA_ "GenSigTimeoutTime_HU_Mid_X445" SG_ 467 HuBCmGotoEntryExitPos 0;
BA_ "GenSigTimeoutMsg_IVI" SG_ 467 HuBCmGotoEntryExitPos 0;
BA_ "GenSigTimeoutTime_IVI" SG_ 467 HuBCmGotoEntryExitPos 0;
BA_ "GenSigTimeoutTime_HU_Mid_X451" SG_ 467 ReceiverContactNo2 0;
BA_ "GenSigTimeoutTime_HU_High_X451" SG_ 467 ReceiverContactNo2 0;
BA_ "GenSigTimeoutTime_HU_B" SG_ 467 ReceiverContactNo2 0;
BA_ "GenSigTimeoutTime_HU_A" SG_ 467 ReceiverContactNo2 0;
BA_ "GenSigTimeoutMsg_HU_Mid_X451" SG_ 467 ReceiverContactNo2 0;
BA_ "GenSigTimeoutMsg_HU_High_X451" SG_ 467 ReceiverContactNo2 0;
BA_ "GenSigTimeoutMsg_HU_B" SG_ 467 ReceiverContactNo2 0;
BA_ "GenSigTimeoutMsg_HU_A" SG_ 467 ReceiverContactNo2 0;
BA_ "GenSigSendType" SG_ 467 ReceiverContactNo2 2;
BA_ "GenSigTimeoutMsg_HU_High_X445" SG_ 467 ReceiverContactNo2 0;
BA_ "GenSigTimeoutMsg_HU_Mid_X445" SG_ 467 ReceiverContactNo2 0;
BA_ "GenSigTimeoutTime_HU_High_X445" SG_ 467 ReceiverContactNo2 0;
BA_ "GenSigTimeoutTime_HU_Mid_X445" SG_ 467 ReceiverContactNo2 0;
BA_ "GenSigTimeoutMsg_IVI" SG_ 467 ReceiverContactNo2 0;
BA_ "GenSigTimeoutTime_IVI" SG_ 467 ReceiverContactNo2 0;
BA_ "GenSigTimeoutTime_HU_Mid_X451" SG_ 467 HuEMsBatteryVrCmdReq 0;
BA_ "GenSigTimeoutTime_HU_High_X451" SG_ 467 HuEMsBatteryVrCmdReq 0;
BA_ "GenSigTimeoutTime_HU_B" SG_ 467 HuEMsBatteryVrCmdReq 0;
BA_ "GenSigTimeoutTime_HU_A" SG_ 467 HuEMsBatteryVrCmdReq 0;
BA_ "GenSigTimeoutMsg_HU_Mid_X451" SG_ 467 HuEMsBatteryVrCmdReq 0;
BA_ "GenSigTimeoutMsg_HU_High_X451" SG_ 467 HuEMsBatteryVrCmdReq 0;
BA_ "GenSigTimeoutMsg_HU_B" SG_ 467 HuEMsBatteryVrCmdReq 0;
BA_ "GenSigTimeoutMsg_HU_A" SG_ 467 HuEMsBatteryVrCmdReq 0;
BA_ "GenSigSendType" SG_ 467 HuEMsBatteryVrCmdReq 2;
BA_ "GenSigTimeoutMsg_HU_High_X445" SG_ 467 HuEMsBatteryVrCmdReq 0;
BA_ "GenSigTimeoutMsg_HU_Mid_X445" SG_ 467 HuEMsBatteryVrCmdReq 0;
BA_ "GenSigTimeoutTime_HU_High_X445" SG_ 467 HuEMsBatteryVrCmdReq 0;
BA_ "GenSigTimeoutTime_HU_Mid_X445" SG_ 467 HuEMsBatteryVrCmdReq 0;
BA_ "GenSigTimeoutMsg_IVI" SG_ 467 HuEMsBatteryVrCmdReq 0;
BA_ "GenSigTimeoutTime_IVI" SG_ 467 HuEMsBatteryVrCmdReq 0;
BA_ "GenSigTimeoutTime_HU_Mid_X451" SG_ 467 HuVoiceCommandDataStatus 0;
BA_ "GenSigTimeoutTime_HU_High_X451" SG_ 467 HuVoiceCommandDataStatus 0;
BA_ "GenSigTimeoutTime_HU_B" SG_ 467 HuVoiceCommandDataStatus 0;
BA_ "GenSigTimeoutTime_HU_A" SG_ 467 HuVoiceCommandDataStatus 0;
BA_ "GenSigTimeoutMsg_HU_Mid_X451" SG_ 467 HuVoiceCommandDataStatus 0;
BA_ "GenSigTimeoutMsg_HU_High_X451" SG_ 467 HuVoiceCommandDataStatus 0;
BA_ "GenSigTimeoutMsg_HU_B" SG_ 467 HuVoiceCommandDataStatus 0;
BA_ "GenSigTimeoutMsg_HU_A" SG_ 467 HuVoiceCommandDataStatus 0;
BA_ "GenSigSendType" SG_ 467 HuVoiceCommandDataStatus 2;
BA_ "GenSigTimeoutMsg_HU_High_X445" SG_ 467 HuVoiceCommandDataStatus 0;
BA_ "GenSigTimeoutMsg_HU_Mid_X445" SG_ 467 HuVoiceCommandDataStatus 0;
BA_ "GenSigTimeoutTime_HU_High_X445" SG_ 467 HuVoiceCommandDataStatus 0;
BA_ "GenSigTimeoutTime_HU_Mid_X445" SG_ 467 HuVoiceCommandDataStatus 0;
BA_ "GenSigTimeoutMsg_IVI" SG_ 467 HuVoiceCommandDataStatus 0;
BA_ "GenSigTimeoutTime_IVI" SG_ 467 HuVoiceCommandDataStatus 0;
BA_ "GenSigTimeoutTime_HU_Mid_X451" SG_ 467 FotaInstallUserReconfirmReq 0;
BA_ "GenSigTimeoutTime_HU_High_X451" SG_ 467 FotaInstallUserReconfirmReq 0;
BA_ "GenSigTimeoutTime_HU_B" SG_ 467 FotaInstallUserReconfirmReq 0;
BA_ "GenSigTimeoutTime_HU_A" SG_ 467 FotaInstallUserReconfirmReq 0;
BA_ "GenSigTimeoutMsg_HU_Mid_X451" SG_ 467 FotaInstallUserReconfirmReq 0;
BA_ "GenSigTimeoutMsg_HU_High_X451" SG_ 467 FotaInstallUserReconfirmReq 0;
BA_ "GenSigTimeoutMsg_HU_B" SG_ 467 FotaInstallUserReconfirmReq 0;
BA_ "GenSigTimeoutMsg_HU_A" SG_ 467 FotaInstallUserReconfirmReq 0;
BA_ "GenSigSendType" SG_ 467 FotaInstallUserReconfirmReq 2;
BA_ "GenSigTimeoutMsg_HU_High_X445" SG_ 467 FotaInstallUserReconfirmReq 0;
BA_ "GenSigTimeoutMsg_HU_Mid_X445" SG_ 467 FotaInstallUserReconfirmReq 0;
BA_ "GenSigTimeoutTime_HU_High_X445" SG_ 467 FotaInstallUserReconfirmReq 0;
BA_ "GenSigTimeoutTime_HU_Mid_X445" SG_ 467 FotaInstallUserReconfirmReq 0;
BA_ "GenSigTimeoutMsg_IVI" SG_ 467 FotaInstallUserReconfirmReq 0;
BA_ "GenSigTimeoutTime_IVI" SG_ 467 FotaInstallUserReconfirmReq 0;
BA_ "GenSigTimeoutTime_HU_Mid_X451" SG_ 467 FotaInstallUserConfirmation 0;
BA_ "GenSigTimeoutTime_HU_High_X451" SG_ 467 FotaInstallUserConfirmation 0;
BA_ "GenSigTimeoutTime_HU_B" SG_ 467 FotaInstallUserConfirmation 0;
BA_ "GenSigTimeoutTime_HU_A" SG_ 467 FotaInstallUserConfirmation 0;
BA_ "GenSigTimeoutMsg_HU_Mid_X451" SG_ 467 FotaInstallUserConfirmation 0;
BA_ "GenSigTimeoutMsg_HU_High_X451" SG_ 467 FotaInstallUserConfirmation 0;
BA_ "GenSigTimeoutMsg_HU_B" SG_ 467 FotaInstallUserConfirmation 0;
BA_ "GenSigTimeoutMsg_HU_A" SG_ 467 FotaInstallUserConfirmation 0;
BA_ "GenSigSendType" SG_ 467 FotaInstallUserConfirmation 2;
BA_ "GenSigTimeoutMsg_HU_High_X445" SG_ 467 FotaInstallUserConfirmation 0;
BA_ "GenSigTimeoutMsg_HU_Mid_X445" SG_ 467 FotaInstallUserConfirmation 0;
BA_ "GenSigTimeoutTime_HU_High_X445" SG_ 467 FotaInstallUserConfirmation 0;
BA_ "GenSigTimeoutTime_HU_Mid_X445" SG_ 467 FotaInstallUserConfirmation 0;
BA_ "GenSigTimeoutMsg_IVI" SG_ 467 FotaInstallUserConfirmation 0;
BA_ "GenSigTimeoutTime_IVI" SG_ 467 FotaInstallUserConfirmation 0;
BA_ "GenSigTimeoutTime_HU_Mid_X451" SG_ 467 FotaHmiReqAck 0;
BA_ "GenSigTimeoutTime_HU_High_X451" SG_ 467 FotaHmiReqAck 0;
BA_ "GenSigTimeoutTime_HU_B" SG_ 467 FotaHmiReqAck 0;
BA_ "GenSigTimeoutTime_HU_A" SG_ 467 FotaHmiReqAck 0;
BA_ "GenSigTimeoutMsg_HU_Mid_X451" SG_ 467 FotaHmiReqAck 0;
BA_ "GenSigTimeoutMsg_HU_High_X451" SG_ 467 FotaHmiReqAck 0;
BA_ "GenSigTimeoutMsg_HU_B" SG_ 467 FotaHmiReqAck 0;
BA_ "GenSigTimeoutMsg_HU_A" SG_ 467 FotaHmiReqAck 0;
BA_ "GenSigSendType" SG_ 467 FotaHmiReqAck 2;
BA_ "GenSigTimeoutMsg_HU_High_X445" SG_ 467 FotaHmiReqAck 0;
BA_ "GenSigTimeoutMsg_HU_Mid_X445" SG_ 467 FotaHmiReqAck 0;
BA_ "GenSigTimeoutTime_HU_High_X445" SG_ 467 FotaHmiReqAck 0;
BA_ "GenSigTimeoutTime_HU_Mid_X445" SG_ 467 FotaHmiReqAck 0;
BA_ "GenSigTimeoutMsg_IVI" SG_ 467 FotaHmiReqAck 0;
BA_ "GenSigTimeoutTime_IVI" SG_ 467 FotaHmiReqAck 0;
BA_ "GenSigTimeoutTime_HU_Mid_X451" SG_ 467 VoiceCommandReq 0;
BA_ "GenSigTimeoutTime_HU_High_X451" SG_ 467 VoiceCommandReq 0;
BA_ "GenSigTimeoutTime_HU_B" SG_ 467 VoiceCommandReq 0;
BA_ "GenSigTimeoutTime_HU_A" SG_ 467 VoiceCommandReq 0;
BA_ "GenSigTimeoutMsg_HU_Mid_X451" SG_ 467 VoiceCommandReq 0;
BA_ "GenSigTimeoutMsg_HU_High_X451" SG_ 467 VoiceCommandReq 0;
BA_ "GenSigTimeoutMsg_HU_B" SG_ 467 VoiceCommandReq 0;
BA_ "GenSigTimeoutMsg_HU_A" SG_ 467 VoiceCommandReq 0;
BA_ "GenSigSendType" SG_ 467 VoiceCommandReq 2;
BA_ "GenSigTimeoutMsg_HU_High_X445" SG_ 467 VoiceCommandReq 0;
BA_ "GenSigTimeoutMsg_HU_Mid_X445" SG_ 467 VoiceCommandReq 0;
BA_ "GenSigTimeoutTime_HU_High_X445" SG_ 467 VoiceCommandReq 0;
BA_ "GenSigTimeoutTime_HU_Mid_X445" SG_ 467 VoiceCommandReq 0;
BA_ "GenSigTimeoutMsg_IVI" SG_ 467 VoiceCommandReq 0;
BA_ "GenSigTimeoutTime_IVI" SG_ 467 VoiceCommandReq 0;
BA_ "GenSigTimeoutTime_HU_Mid_X451" SG_ 467 SharingTimeDuration 0;
BA_ "GenSigTimeoutTime_HU_High_X451" SG_ 467 SharingTimeDuration 0;
BA_ "GenSigTimeoutTime_HU_B" SG_ 467 SharingTimeDuration 0;
BA_ "GenSigTimeoutTime_HU_A" SG_ 467 SharingTimeDuration 0;
BA_ "GenSigTimeoutMsg_HU_Mid_X451" SG_ 467 SharingTimeDuration 0;
BA_ "GenSigTimeoutMsg_HU_High_X451" SG_ 467 SharingTimeDuration 0;
BA_ "GenSigTimeoutMsg_HU_B" SG_ 467 SharingTimeDuration 0;
BA_ "GenSigTimeoutMsg_HU_A" SG_ 467 SharingTimeDuration 0;
BA_ "GenSigSendType" SG_ 467 SharingTimeDuration 2;
BA_ "GenSigTimeoutMsg_HU_High_X445" SG_ 467 SharingTimeDuration 0;
BA_ "GenSigTimeoutMsg_HU_Mid_X445" SG_ 467 SharingTimeDuration 0;
BA_ "GenSigTimeoutTime_HU_High_X445" SG_ 467 SharingTimeDuration 0;
BA_ "GenSigTimeoutTime_HU_Mid_X445" SG_ 467 SharingTimeDuration 0;
BA_ "GenSigTimeoutMsg_IVI" SG_ 467 SharingTimeDuration 0;
BA_ "GenSigTimeoutTime_IVI" SG_ 467 SharingTimeDuration 0;
BA_ "GenSigTimeoutTime_HU_Mid_X451" SG_ 467 SharedLocationReq 0;
BA_ "GenSigTimeoutTime_HU_High_X451" SG_ 467 SharedLocationReq 0;
BA_ "GenSigTimeoutTime_HU_B" SG_ 467 SharedLocationReq 0;
BA_ "GenSigTimeoutTime_HU_A" SG_ 467 SharedLocationReq 0;
BA_ "GenSigTimeoutMsg_HU_Mid_X451" SG_ 467 SharedLocationReq 0;
BA_ "GenSigTimeoutMsg_HU_High_X451" SG_ 467 SharedLocationReq 0;
BA_ "GenSigTimeoutMsg_HU_B" SG_ 467 SharedLocationReq 0;
BA_ "GenSigTimeoutMsg_HU_A" SG_ 467 SharedLocationReq 0;
BA_ "GenSigSendType" SG_ 467 SharedLocationReq 2;
BA_ "GenSigTimeoutMsg_HU_High_X445" SG_ 467 SharedLocationReq 0;
BA_ "GenSigTimeoutMsg_HU_Mid_X445" SG_ 467 SharedLocationReq 0;
BA_ "GenSigTimeoutTime_HU_High_X445" SG_ 467 SharedLocationReq 0;
BA_ "GenSigTimeoutTime_HU_Mid_X445" SG_ 467 SharedLocationReq 0;
BA_ "GenSigTimeoutMsg_IVI" SG_ 467 SharedLocationReq 0;
BA_ "GenSigTimeoutTime_IVI" SG_ 467 SharedLocationReq 0;
BA_ "GenSigTimeoutTime_HU_Mid_X451" SG_ 467 ReceiverContactNo1 0;
BA_ "GenSigTimeoutTime_HU_High_X451" SG_ 467 ReceiverContactNo1 0;
BA_ "GenSigTimeoutTime_HU_B" SG_ 467 ReceiverContactNo1 0;
BA_ "GenSigTimeoutTime_HU_A" SG_ 467 ReceiverContactNo1 0;
BA_ "GenSigTimeoutMsg_HU_Mid_X451" SG_ 467 ReceiverContactNo1 0;
BA_ "GenSigTimeoutMsg_HU_High_X451" SG_ 467 ReceiverContactNo1 0;
BA_ "GenSigTimeoutMsg_HU_B" SG_ 467 ReceiverContactNo1 0;
BA_ "GenSigTimeoutMsg_HU_A" SG_ 467 ReceiverContactNo1 0;
BA_ "GenSigSendType" SG_ 467 ReceiverContactNo1 2;
BA_ "GenSigTimeoutMsg_HU_High_X445" SG_ 467 ReceiverContactNo1 0;
BA_ "GenSigTimeoutMsg_HU_Mid_X445" SG_ 467 ReceiverContactNo1 0;
BA_ "GenSigTimeoutTime_HU_High_X445" SG_ 467 ReceiverContactNo1 0;
BA_ "GenSigTimeoutTime_HU_Mid_X445" SG_ 467 ReceiverContactNo1 0;
BA_ "GenSigTimeoutMsg_IVI" SG_ 467 ReceiverContactNo1 0;
BA_ "GenSigTimeoutTime_IVI" SG_ 467 ReceiverContactNo1 0;
BA_ "GenSigTimeoutTime_HU_Mid_X451" SG_ 467 CommunityHelpReq 0;
BA_ "GenSigTimeoutTime_HU_High_X451" SG_ 467 CommunityHelpReq 0;
BA_ "GenSigTimeoutTime_HU_B" SG_ 467 CommunityHelpReq 0;
BA_ "GenSigTimeoutTime_HU_A" SG_ 467 CommunityHelpReq 0;
BA_ "GenSigTimeoutMsg_HU_Mid_X451" SG_ 467 CommunityHelpReq 0;
BA_ "GenSigTimeoutMsg_HU_High_X451" SG_ 467 CommunityHelpReq 0;
BA_ "GenSigTimeoutMsg_HU_B" SG_ 467 CommunityHelpReq 0;
BA_ "GenSigTimeoutMsg_HU_A" SG_ 467 CommunityHelpReq 0;
BA_ "GenSigSendType" SG_ 467 CommunityHelpReq 2;
BA_ "GenSigTimeoutMsg_HU_High_X445" SG_ 467 CommunityHelpReq 0;
BA_ "GenSigTimeoutMsg_HU_Mid_X445" SG_ 467 CommunityHelpReq 0;
BA_ "GenSigTimeoutTime_HU_High_X445" SG_ 467 CommunityHelpReq 0;
BA_ "GenSigTimeoutTime_HU_Mid_X445" SG_ 467 CommunityHelpReq 0;
BA_ "GenSigTimeoutMsg_IVI" SG_ 467 CommunityHelpReq 0;
BA_ "GenSigTimeoutTime_IVI" SG_ 467 CommunityHelpReq 0;
BA_ "GenSigSendType" SG_ 583 CruiseSwitchStateVCUStatus 7;
BA_ "GenSigCycleTimeActive" SG_ 583 CruiseSwitchStateVCUStatus 100;
BA_ "GenSigCycleTime" SG_ 583 CruiseSwitchStateVCUStatus 100;
BA_ "GenSigSendType" SG_ 583 CruiseSwitchStateVCU 7;
BA_ "GenSigCycleTimeActive" SG_ 583 CruiseSwitchStateVCU 100;
BA_ "GenSigCycleTime" SG_ 583 CruiseSwitchStateVCU 100;
BA_ "GenSigSendType" SG_ 583 VcuModeSelectionChangeTxt 7;
BA_ "GenSigCycleTimeActive" SG_ 583 VcuModeSelectionChangeTxt 100;
BA_ "GenSigCycleTime" SG_ 583 VcuModeSelectionChangeTxt 100;
BA_ "GenSigSendType" SG_ 583 ModeForDisplayVCUStatus 7;
BA_ "GenSigCycleTimeActive" SG_ 583 ModeForDisplayVCUStatus 100;
BA_ "GenSigCycleTime" SG_ 583 ModeForDisplayVCUStatus 100;
BA_ "GenSigSendType" SG_ 583 ModeForDisplayVCU 7;
BA_ "GenSigCycleTimeActive" SG_ 583 ModeForDisplayVCU 100;
BA_ "GenSigCycleTime" SG_ 583 ModeForDisplayVCU 100;
BA_ "GenSigSendType" SG_ 583 ModeSelectionSwStateVCUStatus 7;
BA_ "GenSigCycleTimeActive" SG_ 583 ModeSelectionSwStateVCUStatus 100;
BA_ "GenSigCycleTime" SG_ 583 ModeSelectionSwStateVCUStatus 100;
BA_ "GenSigSendType" SG_ 583 ModeSelectionSwStateVCU 7;
BA_ "GenSigCycleTimeActive" SG_ 583 ModeSelectionSwStateVCU 100;
BA_ "GenSigCycleTime" SG_ 583 ModeSelectionSwStateVCU 100;
BA_ "GenSigSendType" SG_ 583 VcuRegenSelectionChangeTxt 7;
BA_ "GenSigCycleTimeActive" SG_ 583 VcuRegenSelectionChangeTxt 100;
BA_ "GenSigCycleTime" SG_ 583 VcuRegenSelectionChangeTxt 100;
BA_ "GenSigSendType" SG_ 583 RegenForDisplayVCUStatus 7;
BA_ "GenSigCycleTimeActive" SG_ 583 RegenForDisplayVCUStatus 100;
BA_ "GenSigCycleTime" SG_ 583 RegenForDisplayVCUStatus 100;
BA_ "GenSigStartValue" SG_ 583 RegenForDisplayVCU 7;
BA_ "GenSigSendType" SG_ 583 RegenForDisplayVCU 7;
BA_ "GenSigCycleTimeActive" SG_ 583 RegenForDisplayVCU 100;
BA_ "GenSigCycleTime" SG_ 583 RegenForDisplayVCU 100;
BA_ "GenSigSendType" SG_ 583 VcuCruiseSelectionChangeTxt 7;
BA_ "GenSigCycleTimeActive" SG_ 583 VcuCruiseSelectionChangeTxt 100;
BA_ "GenSigCycleTime" SG_ 583 VcuCruiseSelectionChangeTxt 100;
BA_ "GenSigSendType" SG_ 583 DesiredCruiseSpeedStatus 7;
BA_ "GenSigCycleTimeActive" SG_ 583 DesiredCruiseSpeedStatus 100;
BA_ "GenSigCycleTime" SG_ 583 DesiredCruiseSpeedStatus 100;
BA_ "GenSigSendType" SG_ 583 DesiredCruiseSpeed 7;
BA_ "GenSigCycleTimeActive" SG_ 583 DesiredCruiseSpeed 100;
BA_ "GenSigCycleTime" SG_ 583 DesiredCruiseSpeed 100;
BA_ "GenSigSendType" SG_ 583 VCuCruiseStateStatus 7;
BA_ "GenSigCycleTimeActive" SG_ 583 VCuCruiseStateStatus 100;
BA_ "GenSigCycleTime" SG_ 583 VCuCruiseStateStatus 100;
BA_ "GenSigSendType" SG_ 583 VCuCruiseState 7;
BA_ "GenSigCycleTimeActive" SG_ 583 VCuCruiseState 100;
BA_ "GenSigCycleTime" SG_ 583 VCuCruiseState 100;
BA_ "GenSigSendType" SG_ 583 HvBattFullChargeStatus 7;
BA_ "GenSigCycleTimeActive" SG_ 583 HvBattFullChargeStatus 100;
BA_ "GenSigCycleTime" SG_ 583 HvBattFullChargeStatus 100;
BA_ "GenSigSendType" SG_ 583 HvBattFullCharge 7;
BA_ "GenSigCycleTimeActive" SG_ 583 HvBattFullCharge 100;
BA_ "GenSigCycleTime" SG_ 583 HvBattFullCharge 100;
BA_ "GenSigSendType" SG_ 741 RemoteAcPvTempSetStatus 7;
BA_ "GenSigCycleTimeActive" SG_ 741 RemoteAcPvTempSetStatus 100;
BA_ "GenSigCycleTime" SG_ 741 RemoteAcPvTempSetStatus 100;
BA_ "GenSigStartValue" SG_ 741 RemoteAcPvTempSet 19;
BA_ "GenSigSendType" SG_ 741 RemoteAcPvTempSet 7;
BA_ "GenSigCycleTimeActive" SG_ 741 RemoteAcPvTempSet 100;
BA_ "GenSigCycleTime" SG_ 741 RemoteAcPvTempSet 100;
BA_ "GenSigSendType" SG_ 741 VehicleChargingStateTCM 7;
BA_ "GenSigCycleTime" SG_ 741 VehicleChargingStateTCM 100;
BA_ "GenSigSendType" SG_ 741 RemoteEngAcCmdStatus 7;
BA_ "GenSigCycleTimeActive" SG_ 741 RemoteEngAcCmdStatus 100;
BA_ "GenSigCycleTime" SG_ 741 RemoteEngAcCmdStatus 100;
BA_ "GenSigStartValue" SG_ 741 RemoteEngAcCmd 2;
BA_ "GenSigSendType" SG_ 741 RemoteEngAcCmd 7;
BA_ "GenSigCycleTimeActive" SG_ 741 RemoteEngAcCmd 100;
BA_ "GenSigCycleTime" SG_ 741 RemoteEngAcCmd 100;
BA_ "GenSigSendType" SG_ 741 TCmPresence 7;
BA_ "GenSigCycleTimeActive" SG_ 741 TCmPresence 100;
BA_ "GenSigCycleTime" SG_ 741 TCmPresence 100;
BA_ "GenSigSendType" SG_ 741 VcuFotaUpdateState 7;
BA_ "GenSigCycleTime" SG_ 741 VcuFotaUpdateState 100;
BA_ "GenSigSendType" SG_ 741 FatcFotaUpdateState 7;
BA_ "GenSigCycleTime" SG_ 741 FatcFotaUpdateState 100;
BA_ "GenSigSendType" SG_ 741 BcmFotaUpdateState 7;
BA_ "GenSigCycleTime" SG_ 741 BcmFotaUpdateState 100;
BA_ "GenSigSendType" SG_ 741 FotaUpdateEcuProgressPercen 7;
BA_ "GenSigCycleTime" SG_ 741 FotaUpdateEcuProgressPercen 100;
BA_ "GenSigSendType" SG_ 741 FotaUpdateOverallProgressPercen 7;
BA_ "GenSigCycleTime" SG_ 741 FotaUpdateOverallProgressPercen 100;
BA_ "GenSigSendType" SG_ 741 ParkBrkStateTcm 7;
BA_ "GenSigCycleTime" SG_ 741 ParkBrkStateTcm 100;
BA_ "GenSigSendType" SG_ 741 GearPosStateTcm 7;
BA_ "GenSigCycleTime" SG_ 741 GearPosStateTcm 100;
BA_ "GenSigSendType" SG_ 741 LvBattVoltStateTcm 7;
BA_ "GenSigCycleTime" SG_ 741 LvBattVoltStateTcm 100;
BA_ "GenSigSendType" SG_ 741 EngRpmStateTcm 7;
BA_ "GenSigCycleTime" SG_ 741 EngRpmStateTcm 100;
BA_ "GenSigSendType" SG_ 741 VehSpdStateTcm 7;
BA_ "GenSigCycleTime" SG_ 741 VehSpdStateTcm 100;
BA_ "GenSigSendType" SG_ 741 IgnStateTcm 7;
BA_ "GenSigCycleTime" SG_ 741 IgnStateTcm 100;
BA_ "GenSigSendType" SG_ 741 AccPedalPosStateTcm 7;
BA_ "GenSigCycleTime" SG_ 741 AccPedalPosStateTcm 100;
BA_ "GenSigSendType" SG_ 741 FotaUpdateState 7;
BA_ "GenSigCycleTime" SG_ 741 FotaUpdateState 100;
BA_ "GenSigSendType" SG_ 741 ShareMyLocationFeaturePresence 7;
BA_ "GenSigCycleTime" SG_ 741 ShareMyLocationFeaturePresence 100;
BA_ "GenSigSendType" SG_ 741 iCallFeaturePresence 7;
BA_ "GenSigCycleTime" SG_ 741 iCallFeaturePresence 100;
BA_ "GenSigSendType" SG_ 741 eCallFeaturePresence 7;
BA_ "GenSigCycleTime" SG_ 741 eCallFeaturePresence 100;
BA_ "GenSigSendType" SG_ 741 CvpVoiceCmdFeaturePresence 7;
BA_ "GenSigCycleTime" SG_ 741 CvpVoiceCmdFeaturePresence 100;
BA_ "GenSigSendType" SG_ 741 CommunityHelpFeaturePresence 7;
BA_ "GenSigCycleTime" SG_ 741 CommunityHelpFeaturePresence 100;
BA_ "GenSigSendType" SG_ 741 CallType 7;
BA_ "GenSigCycleTime" SG_ 741 CallType 100;
BA_ "GenSigSendType" SG_ 741 CallState 7;
BA_ "GenSigCycleTime" SG_ 741 CallState 100;
BA_ "GenSigSendType" SG_ 741 bCallFeaturePresence 7;
BA_ "GenSigCycleTime" SG_ 741 bCallFeaturePresence 100;
BA_ "GenSigTimeoutTime_HU_B" SG_ 378 MotorTrqMsgRollCnt 0;
BA_ "GenSigTimeoutTime_HU_A" SG_ 378 MotorTrqMsgRollCnt 0;
BA_ "GenSigTimeoutMsg_HU_B" SG_ 378 MotorTrqMsgRollCnt 0;
BA_ "GenSigTimeoutMsg_HU_A" SG_ 378 MotorTrqMsgRollCnt 0;
BA_ "GenSigSendType" SG_ 378 MotorTrqMsgRollCnt 7;
BA_ "GenSigCycleTimeActive" SG_ 378 MotorTrqMsgRollCnt 20;
BA_ "GenSigCycleTime" SG_ 378 MotorTrqMsgRollCnt 20;
BA_ "GenSigTimeoutTime_HU_B" SG_ 378 MotorTrqMsgCRC 0;
BA_ "GenSigTimeoutTime_HU_A" SG_ 378 MotorTrqMsgCRC 0;
BA_ "GenSigTimeoutMsg_HU_B" SG_ 378 MotorTrqMsgCRC 0;
BA_ "GenSigTimeoutMsg_HU_A" SG_ 378 MotorTrqMsgCRC 0;
BA_ "GenSigSendType" SG_ 378 MotorTrqMsgCRC 7;
BA_ "GenSigCycleTimeActive" SG_ 378 MotorTrqMsgCRC 20;
BA_ "GenSigCycleTime" SG_ 378 MotorTrqMsgCRC 20;
BA_ "GenSigTimeoutTime_HU_B" SG_ 378 MotorTrqLimFastStatus 0;
BA_ "GenSigTimeoutTime_HU_A" SG_ 378 MotorTrqLimFastStatus 0;
BA_ "GenSigTimeoutMsg_HU_B" SG_ 378 MotorTrqLimFastStatus 0;
BA_ "GenSigTimeoutMsg_HU_A" SG_ 378 MotorTrqLimFastStatus 0;
BA_ "GenSigSendType" SG_ 378 MotorTrqLimFastStatus 7;
BA_ "GenSigCycleTimeActive" SG_ 378 MotorTrqLimFastStatus 20;
BA_ "GenSigCycleTime" SG_ 378 MotorTrqLimFastStatus 20;
BA_ "GenSigTimeoutTime_HU_B" SG_ 378 MotorTrqLimFast 0;
BA_ "GenSigTimeoutTime_HU_A" SG_ 378 MotorTrqLimFast 0;
BA_ "GenSigTimeoutMsg_HU_B" SG_ 378 MotorTrqLimFast 0;
BA_ "GenSigTimeoutMsg_HU_A" SG_ 378 MotorTrqLimFast 0;
BA_ "GenSigStartValue" SG_ 378 MotorTrqLimFast 5000;
BA_ "GenSigSendType" SG_ 378 MotorTrqLimFast 7;
BA_ "GenSigCycleTimeActive" SG_ 378 MotorTrqLimFast 20;
BA_ "GenSigCycleTime" SG_ 378 MotorTrqLimFast 20;
BA_ "GenSigSendType" SG_ 378 MotorTrqIncStatus 7;
BA_ "GenSigCycleTimeActive" SG_ 378 MotorTrqIncStatus 20;
BA_ "GenSigCycleTime" SG_ 378 MotorTrqIncStatus 20;
BA_ "GenSigStartValue" SG_ 378 MotorTrqInc 5000;
BA_ "GenSigSendType" SG_ 378 MotorTrqInc 7;
BA_ "GenSigCycleTimeActive" SG_ 378 MotorTrqInc 20;
BA_ "GenSigCycleTime" SG_ 378 MotorTrqInc 20;
BA_ "GenSigSendType" SG_ 673 DustSensorConcentrationStatus 7;
BA_ "GenSigCycleTimeActive" SG_ 673 DustSensorConcentrationStatus 100;
BA_ "GenSigCycleTime" SG_ 673 DustSensorConcentrationStatus 100;
BA_ "GenSigSendType" SG_ 673 DustSensorTempError 7;
BA_ "GenSigCycleTimeActive" SG_ 673 DustSensorTempError 100;
BA_ "GenSigCycleTime" SG_ 673 DustSensorTempError 100;
BA_ "GenSigSendType" SG_ 673 DustSensorConcentration 7;
BA_ "GenSigCycleTimeActive" SG_ 673 DustSensorConcentration 100;
BA_ "GenSigCycleTime" SG_ 673 DustSensorConcentration 100;
BA_ "GenSigSendType" SG_ 673 DustSensorTempOverHeat 7;
BA_ "GenSigCycleTimeActive" SG_ 673 DustSensorTempOverHeat 100;
BA_ "GenSigCycleTime" SG_ 673 DustSensorTempOverHeat 100;
BA_ "GenSigSendType" SG_ 673 DustSensorState 7;
BA_ "GenSigCycleTimeActive" SG_ 673 DustSensorState 100;
BA_ "GenSigCycleTime" SG_ 673 DustSensorState 100;
BA_ "GenSigStartValue" SG_ 673 DustSensorTemp 400;
BA_ "GenSigSendType" SG_ 673 DustSensorTemp 7;
BA_ "GenSigCycleTimeActive" SG_ 673 DustSensorTemp 100;
BA_ "GenSigCycleTime" SG_ 673 DustSensorTemp 100;
BA_ "GenSigSendType" SG_ 673 DustSensorSensorChange 7;
BA_ "GenSigCycleTimeActive" SG_ 673 DustSensorSensorChange 100;
BA_ "GenSigCycleTime" SG_ 673 DustSensorSensorChange 100;
BA_ "GenSigSendType" SG_ 673 DustSensorMotorError 7;
BA_ "GenSigCycleTimeActive" SG_ 673 DustSensorMotorError 100;
BA_ "GenSigCycleTime" SG_ 673 DustSensorMotorError 100;
BA_ "GenSigSendType" SG_ 673 DustSensorInitialization 7;
BA_ "GenSigCycleTimeActive" SG_ 673 DustSensorInitialization 100;
BA_ "GenSigCycleTime" SG_ 673 DustSensorInitialization 100;
BA_ "GenSigSendType" SG_ 673 DustSensorHighTempMode 7;
BA_ "GenSigCycleTimeActive" SG_ 673 DustSensorHighTempMode 100;
BA_ "GenSigCycleTime" SG_ 673 DustSensorHighTempMode 100;
BA_ "GenSigSendType" SG_ 673 WirelessChargerPresence 7;
BA_ "GenSigCycleTimeActive" SG_ 673 WirelessChargerPresence 100;
BA_ "GenSigCycleTime" SG_ 673 WirelessChargerPresence 100;
BA_ "GenSigSendType" SG_ 673 WcdutycycleStatus 7;
BA_ "GenSigCycleTimeActive" SG_ 673 WcdutycycleStatus 100;
BA_ "GenSigCycleTime" SG_ 673 WcdutycycleStatus 100;
BA_ "GenSigSendType" SG_ 673 Wcdutycycle 7;
BA_ "GenSigCycleTimeActive" SG_ 673 Wcdutycycle 100;
BA_ "GenSigCycleTime" SG_ 673 Wcdutycycle 100;
BA_ "GenSigTimeoutTime_HU_Mid_X451" SG_ 491 HuBCmWindowWindingHmiCmdSupportA 0;
BA_ "GenSigTimeoutTime_HU_High_X451" SG_ 491 HuBCmWindowWindingHmiCmdSupportA 0;
BA_ "GenSigTimeoutTime_HU_B" SG_ 491 HuBCmWindowWindingHmiCmdSupportA 0;
BA_ "GenSigTimeoutTime_HU_A" SG_ 491 HuBCmWindowWindingHmiCmdSupportA 0;
BA_ "GenSigTimeoutMsg_HU_Mid_X451" SG_ 491 HuBCmWindowWindingHmiCmdSupportA 0;
BA_ "GenSigTimeoutMsg_HU_High_X451" SG_ 491 HuBCmWindowWindingHmiCmdSupportA 0;
BA_ "GenSigTimeoutMsg_HU_B" SG_ 491 HuBCmWindowWindingHmiCmdSupportA 0;
BA_ "GenSigTimeoutMsg_HU_A" SG_ 491 HuBCmWindowWindingHmiCmdSupportA 0;
BA_ "GenSigSendType" SG_ 491 HuBCmWindowWindingHmiCmdSupportA 2;
BA_ "GenSigTimeoutMsg_HU_High_X445" SG_ 491 HuBCmWindowWindingHmiCmdSupportA 0;
BA_ "GenSigTimeoutMsg_HU_Mid_X445" SG_ 491 HuBCmWindowWindingHmiCmdSupportA 0;
BA_ "GenSigTimeoutTime_HU_High_X445" SG_ 491 HuBCmWindowWindingHmiCmdSupportA 0;
BA_ "GenSigTimeoutTime_HU_Mid_X445" SG_ 491 HuBCmWindowWindingHmiCmdSupportA 0;
BA_ "GenSigTimeoutMsg_IVI" SG_ 491 HuBCmWindowWindingHmiCmdSupportA 0;
BA_ "GenSigTimeoutTime_IVI" SG_ 491 HuBCmWindowWindingHmiCmdSupportA 0;
BA_ "SystemSignalLongSymbol" SG_ 491 HuBCmWindowWindingHmiCmdSupportA "HuBCmWindowWindingHmiCmdSupportAck";
BA_ "GenSigTimeoutTime_HU_Mid_X451" SG_ 491 HuBCmTyreTempVrCmdSupportAck 0;
BA_ "GenSigTimeoutTime_HU_High_X451" SG_ 491 HuBCmTyreTempVrCmdSupportAck 0;
BA_ "GenSigTimeoutTime_HU_B" SG_ 491 HuBCmTyreTempVrCmdSupportAck 0;
BA_ "GenSigTimeoutTime_HU_A" SG_ 491 HuBCmTyreTempVrCmdSupportAck 0;
BA_ "GenSigTimeoutMsg_HU_Mid_X451" SG_ 491 HuBCmTyreTempVrCmdSupportAck 0;
BA_ "GenSigTimeoutMsg_HU_High_X451" SG_ 491 HuBCmTyreTempVrCmdSupportAck 0;
BA_ "GenSigTimeoutMsg_HU_B" SG_ 491 HuBCmTyreTempVrCmdSupportAck 0;
BA_ "GenSigTimeoutMsg_HU_A" SG_ 491 HuBCmTyreTempVrCmdSupportAck 0;
BA_ "GenSigSendType" SG_ 491 HuBCmTyreTempVrCmdSupportAck 2;
BA_ "GenSigTimeoutMsg_HU_High_X445" SG_ 491 HuBCmTyreTempVrCmdSupportAck 0;
BA_ "GenSigTimeoutMsg_HU_Mid_X445" SG_ 491 HuBCmTyreTempVrCmdSupportAck 0;
BA_ "GenSigTimeoutTime_HU_High_X445" SG_ 491 HuBCmTyreTempVrCmdSupportAck 0;
BA_ "GenSigTimeoutTime_HU_Mid_X445" SG_ 491 HuBCmTyreTempVrCmdSupportAck 0;
BA_ "GenSigTimeoutMsg_IVI" SG_ 491 HuBCmTyreTempVrCmdSupportAck 0;
BA_ "GenSigTimeoutTime_IVI" SG_ 491 HuBCmTyreTempVrCmdSupportAck 0;
BA_ "GenSigTimeoutTime_HU_Mid_X451" SG_ 491 HuBCmTyreTempHmiCmdSupportAck 0;
BA_ "GenSigTimeoutTime_HU_High_X451" SG_ 491 HuBCmTyreTempHmiCmdSupportAck 0;
BA_ "GenSigTimeoutTime_HU_B" SG_ 491 HuBCmTyreTempHmiCmdSupportAck 0;
BA_ "GenSigTimeoutTime_HU_A" SG_ 491 HuBCmTyreTempHmiCmdSupportAck 0;
BA_ "GenSigTimeoutMsg_HU_Mid_X451" SG_ 491 HuBCmTyreTempHmiCmdSupportAck 0;
BA_ "GenSigTimeoutMsg_HU_High_X451" SG_ 491 HuBCmTyreTempHmiCmdSupportAck 0;
BA_ "GenSigTimeoutMsg_HU_B" SG_ 491 HuBCmTyreTempHmiCmdSupportAck 0;
BA_ "GenSigTimeoutMsg_HU_A" SG_ 491 HuBCmTyreTempHmiCmdSupportAck 0;
BA_ "GenSigSendType" SG_ 491 HuBCmTyreTempHmiCmdSupportAck 2;
BA_ "GenSigTimeoutMsg_HU_High_X445" SG_ 491 HuBCmTyreTempHmiCmdSupportAck 0;
BA_ "GenSigTimeoutMsg_HU_Mid_X445" SG_ 491 HuBCmTyreTempHmiCmdSupportAck 0;
BA_ "GenSigTimeoutTime_HU_High_X445" SG_ 491 HuBCmTyreTempHmiCmdSupportAck 0;
BA_ "GenSigTimeoutTime_HU_Mid_X445" SG_ 491 HuBCmTyreTempHmiCmdSupportAck 0;
BA_ "GenSigTimeoutMsg_IVI" SG_ 491 HuBCmTyreTempHmiCmdSupportAck 0;
BA_ "GenSigTimeoutTime_IVI" SG_ 491 HuBCmTyreTempHmiCmdSupportAck 0;
BA_ "GenSigTimeoutTime_HU_Mid_X451" SG_ 491 HuBCmTyrePressureVrCmdSupportAck 0;
BA_ "GenSigTimeoutTime_HU_High_X451" SG_ 491 HuBCmTyrePressureVrCmdSupportAck 0;
BA_ "GenSigTimeoutTime_HU_B" SG_ 491 HuBCmTyrePressureVrCmdSupportAck 0;
BA_ "GenSigTimeoutTime_HU_A" SG_ 491 HuBCmTyrePressureVrCmdSupportAck 0;
BA_ "GenSigTimeoutMsg_HU_Mid_X451" SG_ 491 HuBCmTyrePressureVrCmdSupportAck 0;
BA_ "GenSigTimeoutMsg_HU_High_X451" SG_ 491 HuBCmTyrePressureVrCmdSupportAck 0;
BA_ "GenSigTimeoutMsg_HU_B" SG_ 491 HuBCmTyrePressureVrCmdSupportAck 0;
BA_ "GenSigTimeoutMsg_HU_A" SG_ 491 HuBCmTyrePressureVrCmdSupportAck 0;
BA_ "GenSigSendType" SG_ 491 HuBCmTyrePressureVrCmdSupportAck 2;
BA_ "GenSigTimeoutMsg_HU_High_X445" SG_ 491 HuBCmTyrePressureVrCmdSupportAck 0;
BA_ "GenSigTimeoutMsg_HU_Mid_X445" SG_ 491 HuBCmTyrePressureVrCmdSupportAck 0;
BA_ "GenSigTimeoutTime_HU_High_X445" SG_ 491 HuBCmTyrePressureVrCmdSupportAck 0;
BA_ "GenSigTimeoutTime_HU_Mid_X445" SG_ 491 HuBCmTyrePressureVrCmdSupportAck 0;
BA_ "GenSigTimeoutMsg_IVI" SG_ 491 HuBCmTyrePressureVrCmdSupportAck 0;
BA_ "GenSigTimeoutTime_IVI" SG_ 491 HuBCmTyrePressureVrCmdSupportAck 0;
BA_ "GenSigTimeoutTime_HU_Mid_X451" SG_ 491 HuBCmTyrePressureHmiCmdSupportAc 0;
BA_ "GenSigTimeoutTime_HU_High_X451" SG_ 491 HuBCmTyrePressureHmiCmdSupportAc 0;
BA_ "GenSigTimeoutTime_HU_B" SG_ 491 HuBCmTyrePressureHmiCmdSupportAc 0;
BA_ "GenSigTimeoutTime_HU_A" SG_ 491 HuBCmTyrePressureHmiCmdSupportAc 0;
BA_ "GenSigTimeoutMsg_HU_Mid_X451" SG_ 491 HuBCmTyrePressureHmiCmdSupportAc 0;
BA_ "GenSigTimeoutMsg_HU_High_X451" SG_ 491 HuBCmTyrePressureHmiCmdSupportAc 0;
BA_ "GenSigTimeoutMsg_HU_B" SG_ 491 HuBCmTyrePressureHmiCmdSupportAc 0;
BA_ "GenSigTimeoutMsg_HU_A" SG_ 491 HuBCmTyrePressureHmiCmdSupportAc 0;
BA_ "GenSigSendType" SG_ 491 HuBCmTyrePressureHmiCmdSupportAc 2;
BA_ "GenSigTimeoutMsg_HU_High_X445" SG_ 491 HuBCmTyrePressureHmiCmdSupportAc 0;
BA_ "GenSigTimeoutMsg_HU_Mid_X445" SG_ 491 HuBCmTyrePressureHmiCmdSupportAc 0;
BA_ "GenSigTimeoutTime_HU_High_X445" SG_ 491 HuBCmTyrePressureHmiCmdSupportAc 0;
BA_ "GenSigTimeoutTime_HU_Mid_X445" SG_ 491 HuBCmTyrePressureHmiCmdSupportAc 0;
BA_ "GenSigTimeoutMsg_IVI" SG_ 491 HuBCmTyrePressureHmiCmdSupportAc 0;
BA_ "GenSigTimeoutTime_IVI" SG_ 491 HuBCmTyrePressureHmiCmdSupportAc 0;
BA_ "SystemSignalLongSymbol" SG_ 491 HuBCmTyrePressureHmiCmdSupportAc "HuBCmTyrePressureHmiCmdSupportAck";
BA_ "GenSigTimeoutTime_HU_Mid_X451" SG_ 491 HuBCmSunroofTiltVrCmdSupportAck 0;
BA_ "GenSigTimeoutTime_HU_High_X451" SG_ 491 HuBCmSunroofTiltVrCmdSupportAck 0;
BA_ "GenSigTimeoutTime_HU_B" SG_ 491 HuBCmSunroofTiltVrCmdSupportAck 0;
BA_ "GenSigTimeoutTime_HU_A" SG_ 491 HuBCmSunroofTiltVrCmdSupportAck 0;
BA_ "GenSigTimeoutMsg_HU_Mid_X451" SG_ 491 HuBCmSunroofTiltVrCmdSupportAck 0;
BA_ "GenSigTimeoutMsg_HU_High_X451" SG_ 491 HuBCmSunroofTiltVrCmdSupportAck 0;
BA_ "GenSigTimeoutMsg_HU_B" SG_ 491 HuBCmSunroofTiltVrCmdSupportAck 0;
BA_ "GenSigTimeoutMsg_HU_A" SG_ 491 HuBCmSunroofTiltVrCmdSupportAck 0;
BA_ "GenSigSendType" SG_ 491 HuBCmSunroofTiltVrCmdSupportAck 2;
BA_ "GenSigTimeoutMsg_HU_High_X445" SG_ 491 HuBCmSunroofTiltVrCmdSupportAck 0;
BA_ "GenSigTimeoutMsg_HU_Mid_X445" SG_ 491 HuBCmSunroofTiltVrCmdSupportAck 0;
BA_ "GenSigTimeoutTime_HU_High_X445" SG_ 491 HuBCmSunroofTiltVrCmdSupportAck 0;
BA_ "GenSigTimeoutTime_HU_Mid_X445" SG_ 491 HuBCmSunroofTiltVrCmdSupportAck 0;
BA_ "GenSigTimeoutMsg_IVI" SG_ 491 HuBCmSunroofTiltVrCmdSupportAck 0;
BA_ "GenSigTimeoutTime_IVI" SG_ 491 HuBCmSunroofTiltVrCmdSupportAck 0;
BA_ "GenSigTimeoutTime_HU_Mid_X451" SG_ 491 HuBCmRoofLampVrCmdSupportAck 0;
BA_ "GenSigTimeoutTime_HU_High_X451" SG_ 491 HuBCmRoofLampVrCmdSupportAck 0;
BA_ "GenSigTimeoutTime_HU_B" SG_ 491 HuBCmRoofLampVrCmdSupportAck 0;
BA_ "GenSigTimeoutTime_HU_A" SG_ 491 HuBCmRoofLampVrCmdSupportAck 0;
BA_ "GenSigTimeoutMsg_HU_Mid_X451" SG_ 491 HuBCmRoofLampVrCmdSupportAck 0;
BA_ "GenSigTimeoutMsg_HU_High_X451" SG_ 491 HuBCmRoofLampVrCmdSupportAck 0;
BA_ "GenSigTimeoutMsg_HU_B" SG_ 491 HuBCmRoofLampVrCmdSupportAck 0;
BA_ "GenSigTimeoutMsg_HU_A" SG_ 491 HuBCmRoofLampVrCmdSupportAck 0;
BA_ "GenSigSendType" SG_ 491 HuBCmRoofLampVrCmdSupportAck 2;
BA_ "GenSigTimeoutMsg_HU_High_X445" SG_ 491 HuBCmRoofLampVrCmdSupportAck 0;
BA_ "GenSigTimeoutMsg_HU_Mid_X445" SG_ 491 HuBCmRoofLampVrCmdSupportAck 0;
BA_ "GenSigTimeoutTime_HU_High_X445" SG_ 491 HuBCmRoofLampVrCmdSupportAck 0;
BA_ "GenSigTimeoutTime_HU_Mid_X445" SG_ 491 HuBCmRoofLampVrCmdSupportAck 0;
BA_ "GenSigTimeoutMsg_IVI" SG_ 491 HuBCmRoofLampVrCmdSupportAck 0;
BA_ "GenSigTimeoutTime_IVI" SG_ 491 HuBCmRoofLampVrCmdSupportAck 0;
BA_ "GenSigTimeoutTime_HU_Mid_X451" SG_ 491 HuBCmRoofLampHmiCmdSupportAck 0;
BA_ "GenSigTimeoutTime_HU_High_X451" SG_ 491 HuBCmRoofLampHmiCmdSupportAck 0;
BA_ "GenSigTimeoutTime_HU_B" SG_ 491 HuBCmRoofLampHmiCmdSupportAck 0;
BA_ "GenSigTimeoutTime_HU_A" SG_ 491 HuBCmRoofLampHmiCmdSupportAck 0;
BA_ "GenSigTimeoutMsg_HU_Mid_X451" SG_ 491 HuBCmRoofLampHmiCmdSupportAck 0;
BA_ "GenSigTimeoutMsg_HU_High_X451" SG_ 491 HuBCmRoofLampHmiCmdSupportAck 0;
BA_ "GenSigTimeoutMsg_HU_B" SG_ 491 HuBCmRoofLampHmiCmdSupportAck 0;
BA_ "GenSigTimeoutMsg_HU_A" SG_ 491 HuBCmRoofLampHmiCmdSupportAck 0;
BA_ "GenSigSendType" SG_ 491 HuBCmRoofLampHmiCmdSupportAck 2;
BA_ "GenSigTimeoutMsg_HU_High_X445" SG_ 491 HuBCmRoofLampHmiCmdSupportAck 0;
BA_ "GenSigTimeoutMsg_HU_Mid_X445" SG_ 491 HuBCmRoofLampHmiCmdSupportAck 0;
BA_ "GenSigTimeoutTime_HU_High_X445" SG_ 491 HuBCmRoofLampHmiCmdSupportAck 0;
BA_ "GenSigTimeoutTime_HU_Mid_X445" SG_ 491 HuBCmRoofLampHmiCmdSupportAck 0;
BA_ "GenSigTimeoutMsg_IVI" SG_ 491 HuBCmRoofLampHmiCmdSupportAck 0;
BA_ "GenSigTimeoutTime_IVI" SG_ 491 HuBCmRoofLampHmiCmdSupportAck 0;
BA_ "GenSigTimeoutTime_HU_Mid_X451" SG_ 491 HuBCmPositionLampVrCmdSupportAck 0;
BA_ "GenSigTimeoutTime_HU_High_X451" SG_ 491 HuBCmPositionLampVrCmdSupportAck 0;
BA_ "GenSigTimeoutTime_HU_B" SG_ 491 HuBCmPositionLampVrCmdSupportAck 0;
BA_ "GenSigTimeoutTime_HU_A" SG_ 491 HuBCmPositionLampVrCmdSupportAck 0;
BA_ "GenSigTimeoutMsg_HU_Mid_X451" SG_ 491 HuBCmPositionLampVrCmdSupportAck 0;
BA_ "GenSigTimeoutMsg_HU_High_X451" SG_ 491 HuBCmPositionLampVrCmdSupportAck 0;
BA_ "GenSigTimeoutMsg_HU_B" SG_ 491 HuBCmPositionLampVrCmdSupportAck 0;
BA_ "GenSigTimeoutMsg_HU_A" SG_ 491 HuBCmPositionLampVrCmdSupportAck 0;
BA_ "GenSigSendType" SG_ 491 HuBCmPositionLampVrCmdSupportAck 2;
BA_ "GenSigTimeoutMsg_HU_High_X445" SG_ 491 HuBCmPositionLampVrCmdSupportAck 0;
BA_ "GenSigTimeoutMsg_HU_Mid_X445" SG_ 491 HuBCmPositionLampVrCmdSupportAck 0;
BA_ "GenSigTimeoutTime_HU_High_X445" SG_ 491 HuBCmPositionLampVrCmdSupportAck 0;
BA_ "GenSigTimeoutTime_HU_Mid_X445" SG_ 491 HuBCmPositionLampVrCmdSupportAck 0;
BA_ "GenSigTimeoutMsg_IVI" SG_ 491 HuBCmPositionLampVrCmdSupportAck 0;
BA_ "GenSigTimeoutTime_IVI" SG_ 491 HuBCmPositionLampVrCmdSupportAck 0;
BA_ "GenSigTimeoutTime_HU_Mid_X451" SG_ 491 HuBCmORVMVrCmdSupportAck 0;
BA_ "GenSigTimeoutTime_HU_High_X451" SG_ 491 HuBCmORVMVrCmdSupportAck 0;
BA_ "GenSigTimeoutTime_HU_B" SG_ 491 HuBCmORVMVrCmdSupportAck 0;
BA_ "GenSigTimeoutTime_HU_A" SG_ 491 HuBCmORVMVrCmdSupportAck 0;
BA_ "GenSigTimeoutMsg_HU_Mid_X451" SG_ 491 HuBCmORVMVrCmdSupportAck 0;
BA_ "GenSigTimeoutMsg_HU_High_X451" SG_ 491 HuBCmORVMVrCmdSupportAck 0;
BA_ "GenSigTimeoutMsg_HU_B" SG_ 491 HuBCmORVMVrCmdSupportAck 0;
BA_ "GenSigTimeoutMsg_HU_A" SG_ 491 HuBCmORVMVrCmdSupportAck 0;
BA_ "GenSigSendType" SG_ 491 HuBCmORVMVrCmdSupportAck 2;
BA_ "GenSigTimeoutMsg_HU_High_X445" SG_ 491 HuBCmORVMVrCmdSupportAck 0;
BA_ "GenSigTimeoutMsg_HU_Mid_X445" SG_ 491 HuBCmORVMVrCmdSupportAck 0;
BA_ "GenSigTimeoutTime_HU_High_X445" SG_ 491 HuBCmORVMVrCmdSupportAck 0;
BA_ "GenSigTimeoutTime_HU_Mid_X445" SG_ 491 HuBCmORVMVrCmdSupportAck 0;
BA_ "GenSigTimeoutMsg_IVI" SG_ 491 HuBCmORVMVrCmdSupportAck 0;
BA_ "GenSigTimeoutTime_IVI" SG_ 491 HuBCmORVMVrCmdSupportAck 0;
BA_ "GenSigTimeoutTime_HU_Mid_X451" SG_ 491 HuBCmORVMHmiCmdSupportAck 0;
BA_ "GenSigTimeoutTime_HU_High_X451" SG_ 491 HuBCmORVMHmiCmdSupportAck 0;
BA_ "GenSigTimeoutTime_HU_B" SG_ 491 HuBCmORVMHmiCmdSupportAck 0;
BA_ "GenSigTimeoutTime_HU_A" SG_ 491 HuBCmORVMHmiCmdSupportAck 0;
BA_ "GenSigTimeoutMsg_HU_Mid_X451" SG_ 491 HuBCmORVMHmiCmdSupportAck 0;
BA_ "GenSigTimeoutMsg_HU_High_X451" SG_ 491 HuBCmORVMHmiCmdSupportAck 0;
BA_ "GenSigTimeoutMsg_HU_B" SG_ 491 HuBCmORVMHmiCmdSupportAck 0;
BA_ "GenSigTimeoutMsg_HU_A" SG_ 491 HuBCmORVMHmiCmdSupportAck 0;
BA_ "GenSigSendType" SG_ 491 HuBCmORVMHmiCmdSupportAck 2;
BA_ "GenSigTimeoutMsg_HU_High_X445" SG_ 491 HuBCmORVMHmiCmdSupportAck 0;
BA_ "GenSigTimeoutMsg_HU_Mid_X445" SG_ 491 HuBCmORVMHmiCmdSupportAck 0;
BA_ "GenSigTimeoutTime_HU_High_X445" SG_ 491 HuBCmORVMHmiCmdSupportAck 0;
BA_ "GenSigTimeoutTime_HU_Mid_X445" SG_ 491 HuBCmORVMHmiCmdSupportAck 0;
BA_ "GenSigTimeoutMsg_IVI" SG_ 491 HuBCmORVMHmiCmdSupportAck 0;
BA_ "GenSigTimeoutTime_IVI" SG_ 491 HuBCmORVMHmiCmdSupportAck 0;
BA_ "GenSigTimeoutTime_HU_Mid_X451" SG_ 491 HuBCmMoodLightVrCmdSupportAck 0;
BA_ "GenSigTimeoutTime_HU_High_X451" SG_ 491 HuBCmMoodLightVrCmdSupportAck 0;
BA_ "GenSigTimeoutTime_HU_B" SG_ 491 HuBCmMoodLightVrCmdSupportAck 0;
BA_ "GenSigTimeoutTime_HU_A" SG_ 491 HuBCmMoodLightVrCmdSupportAck 0;
BA_ "GenSigTimeoutMsg_HU_Mid_X451" SG_ 491 HuBCmMoodLightVrCmdSupportAck 0;
BA_ "GenSigTimeoutMsg_HU_High_X451" SG_ 491 HuBCmMoodLightVrCmdSupportAck 0;
BA_ "GenSigTimeoutMsg_HU_B" SG_ 491 HuBCmMoodLightVrCmdSupportAck 0;
BA_ "GenSigTimeoutMsg_HU_A" SG_ 491 HuBCmMoodLightVrCmdSupportAck 0;
BA_ "GenSigSendType" SG_ 491 HuBCmMoodLightVrCmdSupportAck 2;
BA_ "GenSigTimeoutMsg_HU_High_X445" SG_ 491 HuBCmMoodLightVrCmdSupportAck 0;
BA_ "GenSigTimeoutMsg_HU_Mid_X445" SG_ 491 HuBCmMoodLightVrCmdSupportAck 0;
BA_ "GenSigTimeoutTime_HU_High_X445" SG_ 491 HuBCmMoodLightVrCmdSupportAck 0;
BA_ "GenSigTimeoutTime_HU_Mid_X445" SG_ 491 HuBCmMoodLightVrCmdSupportAck 0;
BA_ "GenSigTimeoutMsg_IVI" SG_ 491 HuBCmMoodLightVrCmdSupportAck 0;
BA_ "GenSigTimeoutTime_IVI" SG_ 491 HuBCmMoodLightVrCmdSupportAck 0;
BA_ "GenSigTimeoutTime_HU_Mid_X451" SG_ 491 HuBCmHazardLampVrCmdSupportAck 0;
BA_ "GenSigTimeoutTime_HU_High_X451" SG_ 491 HuBCmHazardLampVrCmdSupportAck 0;
BA_ "GenSigTimeoutTime_HU_B" SG_ 491 HuBCmHazardLampVrCmdSupportAck 0;
BA_ "GenSigTimeoutTime_HU_A" SG_ 491 HuBCmHazardLampVrCmdSupportAck 0;
BA_ "GenSigTimeoutMsg_HU_Mid_X451" SG_ 491 HuBCmHazardLampVrCmdSupportAck 0;
BA_ "GenSigTimeoutMsg_HU_High_X451" SG_ 491 HuBCmHazardLampVrCmdSupportAck 0;
BA_ "GenSigTimeoutMsg_HU_B" SG_ 491 HuBCmHazardLampVrCmdSupportAck 0;
BA_ "GenSigTimeoutMsg_HU_A" SG_ 491 HuBCmHazardLampVrCmdSupportAck 0;
BA_ "GenSigSendType" SG_ 491 HuBCmHazardLampVrCmdSupportAck 2;
BA_ "GenSigTimeoutMsg_HU_High_X445" SG_ 491 HuBCmHazardLampVrCmdSupportAck 0;
BA_ "GenSigTimeoutMsg_HU_Mid_X445" SG_ 491 HuBCmHazardLampVrCmdSupportAck 0;
BA_ "GenSigTimeoutTime_HU_High_X445" SG_ 491 HuBCmHazardLampVrCmdSupportAck 0;
BA_ "GenSigTimeoutTime_HU_Mid_X445" SG_ 491 HuBCmHazardLampVrCmdSupportAck 0;
BA_ "GenSigTimeoutMsg_IVI" SG_ 491 HuBCmHazardLampVrCmdSupportAck 0;
BA_ "GenSigTimeoutTime_IVI" SG_ 491 HuBCmHazardLampVrCmdSupportAck 0;
BA_ "GenSigTimeoutTime_HU_Mid_X451" SG_ 491 HuBCmDRLVrCmdSupportAck 0;
BA_ "GenSigTimeoutTime_HU_High_X451" SG_ 491 HuBCmDRLVrCmdSupportAck 0;
BA_ "GenSigTimeoutTime_HU_B" SG_ 491 HuBCmDRLVrCmdSupportAck 0;
BA_ "GenSigTimeoutTime_HU_A" SG_ 491 HuBCmDRLVrCmdSupportAck 0;
BA_ "GenSigTimeoutMsg_HU_Mid_X451" SG_ 491 HuBCmDRLVrCmdSupportAck 0;
BA_ "GenSigTimeoutMsg_HU_High_X451" SG_ 491 HuBCmDRLVrCmdSupportAck 0;
BA_ "GenSigTimeoutMsg_HU_B" SG_ 491 HuBCmDRLVrCmdSupportAck 0;
BA_ "GenSigTimeoutMsg_HU_A" SG_ 491 HuBCmDRLVrCmdSupportAck 0;
BA_ "GenSigSendType" SG_ 491 HuBCmDRLVrCmdSupportAck 2;
BA_ "GenSigTimeoutMsg_HU_High_X445" SG_ 491 HuBCmDRLVrCmdSupportAck 0;
BA_ "GenSigTimeoutMsg_HU_Mid_X445" SG_ 491 HuBCmDRLVrCmdSupportAck 0;
BA_ "GenSigTimeoutTime_HU_High_X445" SG_ 491 HuBCmDRLVrCmdSupportAck 0;
BA_ "GenSigTimeoutTime_HU_Mid_X445" SG_ 491 HuBCmDRLVrCmdSupportAck 0;
BA_ "GenSigTimeoutMsg_IVI" SG_ 491 HuBCmDRLVrCmdSupportAck 0;
BA_ "GenSigTimeoutTime_IVI" SG_ 491 HuBCmDRLVrCmdSupportAck 0;
BA_ "GenSigTimeoutTime_HU_Mid_X451" SG_ 491 HuBCmAmbientLightVrCmdSupportAck 0;
BA_ "GenSigTimeoutTime_HU_High_X451" SG_ 491 HuBCmAmbientLightVrCmdSupportAck 0;
BA_ "GenSigTimeoutTime_HU_B" SG_ 491 HuBCmAmbientLightVrCmdSupportAck 0;
BA_ "GenSigTimeoutTime_HU_A" SG_ 491 HuBCmAmbientLightVrCmdSupportAck 0;
BA_ "GenSigTimeoutMsg_HU_Mid_X451" SG_ 491 HuBCmAmbientLightVrCmdSupportAck 0;
BA_ "GenSigTimeoutMsg_HU_High_X451" SG_ 491 HuBCmAmbientLightVrCmdSupportAck 0;
BA_ "GenSigTimeoutMsg_HU_B" SG_ 491 HuBCmAmbientLightVrCmdSupportAck 0;
BA_ "GenSigTimeoutMsg_HU_A" SG_ 491 HuBCmAmbientLightVrCmdSupportAck 0;
BA_ "GenSigSendType" SG_ 491 HuBCmAmbientLightVrCmdSupportAck 2;
BA_ "GenSigTimeoutMsg_HU_High_X445" SG_ 491 HuBCmAmbientLightVrCmdSupportAck 0;
BA_ "GenSigTimeoutMsg_HU_Mid_X445" SG_ 491 HuBCmAmbientLightVrCmdSupportAck 0;
BA_ "GenSigTimeoutTime_HU_High_X445" SG_ 491 HuBCmAmbientLightVrCmdSupportAck 0;
BA_ "GenSigTimeoutTime_HU_Mid_X445" SG_ 491 HuBCmAmbientLightVrCmdSupportAck 0;
BA_ "GenSigTimeoutMsg_IVI" SG_ 491 HuBCmAmbientLightVrCmdSupportAck 0;
BA_ "GenSigTimeoutTime_IVI" SG_ 491 HuBCmAmbientLightVrCmdSupportAck 0;
BA_ "GenSigTimeoutTime_HU_Mid_X451" SG_ 491 HuBCmSunShadeVrCmdSupportAck 0;
BA_ "GenSigTimeoutTime_HU_High_X451" SG_ 491 HuBCmSunShadeVrCmdSupportAck 0;
BA_ "GenSigTimeoutTime_HU_B" SG_ 491 HuBCmSunShadeVrCmdSupportAck 0;
BA_ "GenSigTimeoutTime_HU_A" SG_ 491 HuBCmSunShadeVrCmdSupportAck 0;
BA_ "GenSigTimeoutMsg_HU_Mid_X451" SG_ 491 HuBCmSunShadeVrCmdSupportAck 0;
BA_ "GenSigTimeoutMsg_HU_High_X451" SG_ 491 HuBCmSunShadeVrCmdSupportAck 0;
BA_ "GenSigTimeoutMsg_HU_B" SG_ 491 HuBCmSunShadeVrCmdSupportAck 0;
BA_ "GenSigTimeoutMsg_HU_A" SG_ 491 HuBCmSunShadeVrCmdSupportAck 0;
BA_ "GenSigSendType" SG_ 491 HuBCmSunShadeVrCmdSupportAck 2;
BA_ "GenSigTimeoutMsg_HU_High_X445" SG_ 491 HuBCmSunShadeVrCmdSupportAck 0;
BA_ "GenSigTimeoutMsg_HU_Mid_X445" SG_ 491 HuBCmSunShadeVrCmdSupportAck 0;
BA_ "GenSigTimeoutTime_HU_High_X445" SG_ 491 HuBCmSunShadeVrCmdSupportAck 0;
BA_ "GenSigTimeoutTime_HU_Mid_X445" SG_ 491 HuBCmSunShadeVrCmdSupportAck 0;
BA_ "GenSigTimeoutMsg_IVI" SG_ 491 HuBCmSunShadeVrCmdSupportAck 0;
BA_ "GenSigTimeoutTime_IVI" SG_ 491 HuBCmSunShadeVrCmdSupportAck 0;
BA_ "GenSigTimeoutTime_HU_Mid_X451" SG_ 491 HuBCmSunRoofVrCmdSupportAck 0;
BA_ "GenSigTimeoutTime_HU_High_X451" SG_ 491 HuBCmSunRoofVrCmdSupportAck 0;
BA_ "GenSigTimeoutTime_HU_B" SG_ 491 HuBCmSunRoofVrCmdSupportAck 0;
BA_ "GenSigTimeoutTime_HU_A" SG_ 491 HuBCmSunRoofVrCmdSupportAck 0;
BA_ "GenSigTimeoutMsg_HU_Mid_X451" SG_ 491 HuBCmSunRoofVrCmdSupportAck 0;
BA_ "GenSigTimeoutMsg_HU_High_X451" SG_ 491 HuBCmSunRoofVrCmdSupportAck 0;
BA_ "GenSigTimeoutMsg_HU_B" SG_ 491 HuBCmSunRoofVrCmdSupportAck 0;
BA_ "GenSigTimeoutMsg_HU_A" SG_ 491 HuBCmSunRoofVrCmdSupportAck 0;
BA_ "GenSigSendType" SG_ 491 HuBCmSunRoofVrCmdSupportAck 2;
BA_ "GenSigTimeoutMsg_HU_High_X445" SG_ 491 HuBCmSunRoofVrCmdSupportAck 0;
BA_ "GenSigTimeoutMsg_HU_Mid_X445" SG_ 491 HuBCmSunRoofVrCmdSupportAck 0;
BA_ "GenSigTimeoutTime_HU_High_X445" SG_ 491 HuBCmSunRoofVrCmdSupportAck 0;
BA_ "GenSigTimeoutTime_HU_Mid_X445" SG_ 491 HuBCmSunRoofVrCmdSupportAck 0;
BA_ "GenSigTimeoutMsg_IVI" SG_ 491 HuBCmSunRoofVrCmdSupportAck 0;
BA_ "GenSigTimeoutTime_IVI" SG_ 491 HuBCmSunRoofVrCmdSupportAck 0;
BA_ "GenSigTimeoutTime_HU_Mid_X451" SG_ 461 HuBCmWindowWindingHmiCmdReq 0;
BA_ "GenSigTimeoutTime_HU_High_X451" SG_ 461 HuBCmWindowWindingHmiCmdReq 0;
BA_ "GenSigTimeoutTime_HU_B" SG_ 461 HuBCmWindowWindingHmiCmdReq 0;
BA_ "GenSigTimeoutTime_HU_A" SG_ 461 HuBCmWindowWindingHmiCmdReq 0;
BA_ "GenSigTimeoutMsg_HU_Mid_X451" SG_ 461 HuBCmWindowWindingHmiCmdReq 0;
BA_ "GenSigTimeoutMsg_HU_High_X451" SG_ 461 HuBCmWindowWindingHmiCmdReq 0;
BA_ "GenSigTimeoutMsg_HU_B" SG_ 461 HuBCmWindowWindingHmiCmdReq 0;
BA_ "GenSigTimeoutMsg_HU_A" SG_ 461 HuBCmWindowWindingHmiCmdReq 0;
BA_ "GenSigSendType" SG_ 461 HuBCmWindowWindingHmiCmdReq 2;
BA_ "GenSigTimeoutMsg_HU_High_X445" SG_ 461 HuBCmWindowWindingHmiCmdReq 0;
BA_ "GenSigTimeoutMsg_HU_Mid_X445" SG_ 461 HuBCmWindowWindingHmiCmdReq 0;
BA_ "GenSigTimeoutTime_HU_High_X445" SG_ 461 HuBCmWindowWindingHmiCmdReq 0;
BA_ "GenSigTimeoutTime_HU_Mid_X445" SG_ 461 HuBCmWindowWindingHmiCmdReq 0;
BA_ "GenSigTimeoutMsg_IVI" SG_ 461 HuBCmWindowWindingHmiCmdReq 0;
BA_ "GenSigTimeoutTime_IVI" SG_ 461 HuBCmWindowWindingHmiCmdReq 0;
BA_ "GenSigTimeoutTime_HU_Mid_X451" SG_ 461 HuBCmTyreTempHmiVrCmdReq 0;
BA_ "GenSigTimeoutTime_HU_High_X451" SG_ 461 HuBCmTyreTempHmiVrCmdReq 0;
BA_ "GenSigTimeoutTime_HU_B" SG_ 461 HuBCmTyreTempHmiVrCmdReq 0;
BA_ "GenSigTimeoutTime_HU_A" SG_ 461 HuBCmTyreTempHmiVrCmdReq 0;
BA_ "GenSigTimeoutMsg_HU_Mid_X451" SG_ 461 HuBCmTyreTempHmiVrCmdReq 0;
BA_ "GenSigTimeoutMsg_HU_High_X451" SG_ 461 HuBCmTyreTempHmiVrCmdReq 0;
BA_ "GenSigTimeoutMsg_HU_B" SG_ 461 HuBCmTyreTempHmiVrCmdReq 0;
BA_ "GenSigTimeoutMsg_HU_A" SG_ 461 HuBCmTyreTempHmiVrCmdReq 0;
BA_ "GenSigSendType" SG_ 461 HuBCmTyreTempHmiVrCmdReq 2;
BA_ "GenSigTimeoutMsg_HU_High_X445" SG_ 461 HuBCmTyreTempHmiVrCmdReq 0;
BA_ "GenSigTimeoutMsg_HU_Mid_X445" SG_ 461 HuBCmTyreTempHmiVrCmdReq 0;
BA_ "GenSigTimeoutTime_HU_High_X445" SG_ 461 HuBCmTyreTempHmiVrCmdReq 0;
BA_ "GenSigTimeoutTime_HU_Mid_X445" SG_ 461 HuBCmTyreTempHmiVrCmdReq 0;
BA_ "GenSigTimeoutMsg_IVI" SG_ 461 HuBCmTyreTempHmiVrCmdReq 0;
BA_ "GenSigTimeoutTime_IVI" SG_ 461 HuBCmTyreTempHmiVrCmdReq 0;
BA_ "GenSigTimeoutTime_HU_Mid_X451" SG_ 461 HuBCmTyrePressureHmiVrCmdReq 0;
BA_ "GenSigTimeoutTime_HU_High_X451" SG_ 461 HuBCmTyrePressureHmiVrCmdReq 0;
BA_ "GenSigTimeoutTime_HU_B" SG_ 461 HuBCmTyrePressureHmiVrCmdReq 0;
BA_ "GenSigTimeoutTime_HU_A" SG_ 461 HuBCmTyrePressureHmiVrCmdReq 0;
BA_ "GenSigTimeoutMsg_HU_Mid_X451" SG_ 461 HuBCmTyrePressureHmiVrCmdReq 0;
BA_ "GenSigTimeoutMsg_HU_High_X451" SG_ 461 HuBCmTyrePressureHmiVrCmdReq 0;
BA_ "GenSigTimeoutMsg_HU_B" SG_ 461 HuBCmTyrePressureHmiVrCmdReq 0;
BA_ "GenSigTimeoutMsg_HU_A" SG_ 461 HuBCmTyrePressureHmiVrCmdReq 0;
BA_ "GenSigSendType" SG_ 461 HuBCmTyrePressureHmiVrCmdReq 2;
BA_ "GenSigTimeoutMsg_HU_High_X445" SG_ 461 HuBCmTyrePressureHmiVrCmdReq 0;
BA_ "GenSigTimeoutMsg_HU_Mid_X445" SG_ 461 HuBCmTyrePressureHmiVrCmdReq 0;
BA_ "GenSigTimeoutTime_HU_High_X445" SG_ 461 HuBCmTyrePressureHmiVrCmdReq 0;
BA_ "GenSigTimeoutTime_HU_Mid_X445" SG_ 461 HuBCmTyrePressureHmiVrCmdReq 0;
BA_ "GenSigTimeoutMsg_IVI" SG_ 461 HuBCmTyrePressureHmiVrCmdReq 0;
BA_ "GenSigTimeoutTime_IVI" SG_ 461 HuBCmTyrePressureHmiVrCmdReq 0;
BA_ "GenSigTimeoutTime_HU_Mid_X451" SG_ 461 HuBCmRoofLampHmiVrCmdReq 0;
BA_ "GenSigTimeoutTime_HU_High_X451" SG_ 461 HuBCmRoofLampHmiVrCmdReq 0;
BA_ "GenSigTimeoutTime_HU_B" SG_ 461 HuBCmRoofLampHmiVrCmdReq 0;
BA_ "GenSigTimeoutTime_HU_A" SG_ 461 HuBCmRoofLampHmiVrCmdReq 0;
BA_ "GenSigTimeoutMsg_HU_Mid_X451" SG_ 461 HuBCmRoofLampHmiVrCmdReq 0;
BA_ "GenSigTimeoutMsg_HU_High_X451" SG_ 461 HuBCmRoofLampHmiVrCmdReq 0;
BA_ "GenSigTimeoutMsg_HU_B" SG_ 461 HuBCmRoofLampHmiVrCmdReq 0;
BA_ "GenSigTimeoutMsg_HU_A" SG_ 461 HuBCmRoofLampHmiVrCmdReq 0;
BA_ "GenSigSendType" SG_ 461 HuBCmRoofLampHmiVrCmdReq 2;
BA_ "GenSigTimeoutMsg_HU_High_X445" SG_ 461 HuBCmRoofLampHmiVrCmdReq 0;
BA_ "GenSigTimeoutMsg_HU_Mid_X445" SG_ 461 HuBCmRoofLampHmiVrCmdReq 0;
BA_ "GenSigTimeoutTime_HU_High_X445" SG_ 461 HuBCmRoofLampHmiVrCmdReq 0;
BA_ "GenSigTimeoutTime_HU_Mid_X445" SG_ 461 HuBCmRoofLampHmiVrCmdReq 0;
BA_ "GenSigTimeoutMsg_IVI" SG_ 461 HuBCmRoofLampHmiVrCmdReq 0;
BA_ "GenSigTimeoutTime_IVI" SG_ 461 HuBCmRoofLampHmiVrCmdReq 0;
BA_ "GenSigTimeoutTime_HU_Mid_X451" SG_ 461 HuBCmPositionLampVrCmdReq 0;
BA_ "GenSigTimeoutTime_HU_High_X451" SG_ 461 HuBCmPositionLampVrCmdReq 0;
BA_ "GenSigTimeoutTime_HU_B" SG_ 461 HuBCmPositionLampVrCmdReq 0;
BA_ "GenSigTimeoutTime_HU_A" SG_ 461 HuBCmPositionLampVrCmdReq 0;
BA_ "GenSigTimeoutMsg_HU_Mid_X451" SG_ 461 HuBCmPositionLampVrCmdReq 0;
BA_ "GenSigTimeoutMsg_HU_High_X451" SG_ 461 HuBCmPositionLampVrCmdReq 0;
BA_ "GenSigTimeoutMsg_HU_B" SG_ 461 HuBCmPositionLampVrCmdReq 0;
BA_ "GenSigTimeoutMsg_HU_A" SG_ 461 HuBCmPositionLampVrCmdReq 0;
BA_ "GenSigSendType" SG_ 461 HuBCmPositionLampVrCmdReq 2;
BA_ "GenSigTimeoutMsg_HU_High_X445" SG_ 461 HuBCmPositionLampVrCmdReq 0;
BA_ "GenSigTimeoutMsg_HU_Mid_X445" SG_ 461 HuBCmPositionLampVrCmdReq 0;
BA_ "GenSigTimeoutTime_HU_High_X445" SG_ 461 HuBCmPositionLampVrCmdReq 0;
BA_ "GenSigTimeoutTime_HU_Mid_X445" SG_ 461 HuBCmPositionLampVrCmdReq 0;
BA_ "GenSigTimeoutMsg_IVI" SG_ 461 HuBCmPositionLampVrCmdReq 0;
BA_ "GenSigTimeoutTime_IVI" SG_ 461 HuBCmPositionLampVrCmdReq 0;
BA_ "GenSigTimeoutTime_HU_Mid_X451" SG_ 461 HuBCmORVMHmiVrCmdReq 0;
BA_ "GenSigTimeoutTime_HU_High_X451" SG_ 461 HuBCmORVMHmiVrCmdReq 0;
BA_ "GenSigTimeoutTime_HU_B" SG_ 461 HuBCmORVMHmiVrCmdReq 0;
BA_ "GenSigTimeoutTime_HU_A" SG_ 461 HuBCmORVMHmiVrCmdReq 0;
BA_ "GenSigTimeoutMsg_HU_Mid_X451" SG_ 461 HuBCmORVMHmiVrCmdReq 0;
BA_ "GenSigTimeoutMsg_HU_High_X451" SG_ 461 HuBCmORVMHmiVrCmdReq 0;
BA_ "GenSigTimeoutMsg_HU_B" SG_ 461 HuBCmORVMHmiVrCmdReq 0;
BA_ "GenSigTimeoutMsg_HU_A" SG_ 461 HuBCmORVMHmiVrCmdReq 0;
BA_ "GenSigSendType" SG_ 461 HuBCmORVMHmiVrCmdReq 2;
BA_ "GenSigTimeoutMsg_HU_High_X445" SG_ 461 HuBCmORVMHmiVrCmdReq 0;
BA_ "GenSigTimeoutMsg_HU_Mid_X445" SG_ 461 HuBCmORVMHmiVrCmdReq 0;
BA_ "GenSigTimeoutTime_HU_High_X445" SG_ 461 HuBCmORVMHmiVrCmdReq 0;
BA_ "GenSigTimeoutTime_HU_Mid_X445" SG_ 461 HuBCmORVMHmiVrCmdReq 0;
BA_ "GenSigTimeoutMsg_IVI" SG_ 461 HuBCmORVMHmiVrCmdReq 0;
BA_ "GenSigTimeoutTime_IVI" SG_ 461 HuBCmORVMHmiVrCmdReq 0;
BA_ "GenSigTimeoutTime_HU_Mid_X451" SG_ 461 HuBCmMoodLightVrCmdReq 0;
BA_ "GenSigTimeoutTime_HU_High_X451" SG_ 461 HuBCmMoodLightVrCmdReq 0;
BA_ "GenSigTimeoutTime_HU_B" SG_ 461 HuBCmMoodLightVrCmdReq 0;
BA_ "GenSigTimeoutTime_HU_A" SG_ 461 HuBCmMoodLightVrCmdReq 0;
BA_ "GenSigTimeoutMsg_HU_Mid_X451" SG_ 461 HuBCmMoodLightVrCmdReq 0;
BA_ "GenSigTimeoutMsg_HU_High_X451" SG_ 461 HuBCmMoodLightVrCmdReq 0;
BA_ "GenSigTimeoutMsg_HU_B" SG_ 461 HuBCmMoodLightVrCmdReq 0;
BA_ "GenSigTimeoutMsg_HU_A" SG_ 461 HuBCmMoodLightVrCmdReq 0;
BA_ "GenSigSendType" SG_ 461 HuBCmMoodLightVrCmdReq 2;
BA_ "GenSigTimeoutMsg_HU_High_X445" SG_ 461 HuBCmMoodLightVrCmdReq 0;
BA_ "GenSigTimeoutMsg_HU_Mid_X445" SG_ 461 HuBCmMoodLightVrCmdReq 0;
BA_ "GenSigTimeoutTime_HU_High_X445" SG_ 461 HuBCmMoodLightVrCmdReq 0;
BA_ "GenSigTimeoutTime_HU_Mid_X445" SG_ 461 HuBCmMoodLightVrCmdReq 0;
BA_ "GenSigTimeoutMsg_IVI" SG_ 461 HuBCmMoodLightVrCmdReq 0;
BA_ "GenSigTimeoutTime_IVI" SG_ 461 HuBCmMoodLightVrCmdReq 0;
BA_ "GenSigTimeoutTime_HU_Mid_X451" SG_ 461 HuBCmHazardLampVrCmdReq 0;
BA_ "GenSigTimeoutTime_HU_High_X451" SG_ 461 HuBCmHazardLampVrCmdReq 0;
BA_ "GenSigTimeoutTime_HU_B" SG_ 461 HuBCmHazardLampVrCmdReq 0;
BA_ "GenSigTimeoutTime_HU_A" SG_ 461 HuBCmHazardLampVrCmdReq 0;
BA_ "GenSigTimeoutMsg_HU_Mid_X451" SG_ 461 HuBCmHazardLampVrCmdReq 0;
BA_ "GenSigTimeoutMsg_HU_High_X451" SG_ 461 HuBCmHazardLampVrCmdReq 0;
BA_ "GenSigTimeoutMsg_HU_B" SG_ 461 HuBCmHazardLampVrCmdReq 0;
BA_ "GenSigTimeoutMsg_HU_A" SG_ 461 HuBCmHazardLampVrCmdReq 0;
BA_ "GenSigSendType" SG_ 461 HuBCmHazardLampVrCmdReq 2;
BA_ "GenSigTimeoutMsg_HU_High_X445" SG_ 461 HuBCmHazardLampVrCmdReq 0;
BA_ "GenSigTimeoutMsg_HU_Mid_X445" SG_ 461 HuBCmHazardLampVrCmdReq 0;
BA_ "GenSigTimeoutTime_HU_High_X445" SG_ 461 HuBCmHazardLampVrCmdReq 0;
BA_ "GenSigTimeoutTime_HU_Mid_X445" SG_ 461 HuBCmHazardLampVrCmdReq 0;
BA_ "GenSigTimeoutMsg_IVI" SG_ 461 HuBCmHazardLampVrCmdReq 0;
BA_ "GenSigTimeoutTime_IVI" SG_ 461 HuBCmHazardLampVrCmdReq 0;
BA_ "GenSigTimeoutTime_HU_Mid_X451" SG_ 461 HuBCmDRLVrCmdReq 0;
BA_ "GenSigTimeoutTime_HU_High_X451" SG_ 461 HuBCmDRLVrCmdReq 0;
BA_ "GenSigTimeoutTime_HU_B" SG_ 461 HuBCmDRLVrCmdReq 0;
BA_ "GenSigTimeoutTime_HU_A" SG_ 461 HuBCmDRLVrCmdReq 0;
BA_ "GenSigTimeoutMsg_HU_Mid_X451" SG_ 461 HuBCmDRLVrCmdReq 0;
BA_ "GenSigTimeoutMsg_HU_High_X451" SG_ 461 HuBCmDRLVrCmdReq 0;
BA_ "GenSigTimeoutMsg_HU_B" SG_ 461 HuBCmDRLVrCmdReq 0;
BA_ "GenSigTimeoutMsg_HU_A" SG_ 461 HuBCmDRLVrCmdReq 0;
BA_ "GenSigSendType" SG_ 461 HuBCmDRLVrCmdReq 2;
BA_ "GenSigTimeoutMsg_HU_High_X445" SG_ 461 HuBCmDRLVrCmdReq 0;
BA_ "GenSigTimeoutMsg_HU_Mid_X445" SG_ 461 HuBCmDRLVrCmdReq 0;
BA_ "GenSigTimeoutTime_HU_High_X445" SG_ 461 HuBCmDRLVrCmdReq 0;
BA_ "GenSigTimeoutTime_HU_Mid_X445" SG_ 461 HuBCmDRLVrCmdReq 0;
BA_ "GenSigTimeoutMsg_IVI" SG_ 461 HuBCmDRLVrCmdReq 0;
BA_ "GenSigTimeoutTime_IVI" SG_ 461 HuBCmDRLVrCmdReq 0;
BA_ "GenSigTimeoutTime_HU_Mid_X451" SG_ 461 HuBCmAmbientLightVrCmdReq 0;
BA_ "GenSigTimeoutTime_HU_High_X451" SG_ 461 HuBCmAmbientLightVrCmdReq 0;
BA_ "GenSigTimeoutTime_HU_B" SG_ 461 HuBCmAmbientLightVrCmdReq 0;
BA_ "GenSigTimeoutTime_HU_A" SG_ 461 HuBCmAmbientLightVrCmdReq 0;
BA_ "GenSigTimeoutMsg_HU_Mid_X451" SG_ 461 HuBCmAmbientLightVrCmdReq 0;
BA_ "GenSigTimeoutMsg_HU_High_X451" SG_ 461 HuBCmAmbientLightVrCmdReq 0;
BA_ "GenSigTimeoutMsg_HU_B" SG_ 461 HuBCmAmbientLightVrCmdReq 0;
BA_ "GenSigTimeoutMsg_HU_A" SG_ 461 HuBCmAmbientLightVrCmdReq 0;
BA_ "GenSigSendType" SG_ 461 HuBCmAmbientLightVrCmdReq 2;
BA_ "GenSigTimeoutMsg_HU_High_X445" SG_ 461 HuBCmAmbientLightVrCmdReq 0;
BA_ "GenSigTimeoutMsg_HU_Mid_X445" SG_ 461 HuBCmAmbientLightVrCmdReq 0;
BA_ "GenSigTimeoutTime_HU_High_X445" SG_ 461 HuBCmAmbientLightVrCmdReq 0;
BA_ "GenSigTimeoutTime_HU_Mid_X445" SG_ 461 HuBCmAmbientLightVrCmdReq 0;
BA_ "GenSigTimeoutMsg_IVI" SG_ 461 HuBCmAmbientLightVrCmdReq 0;
BA_ "GenSigTimeoutTime_IVI" SG_ 461 HuBCmAmbientLightVrCmdReq 0;
BA_ "GenSigTimeoutTime_HU_Mid_X451" SG_ 461 HuBCmTiltVrCmdReq 0;
BA_ "GenSigTimeoutTime_HU_High_X451" SG_ 461 HuBCmTiltVrCmdReq 0;
BA_ "GenSigTimeoutTime_HU_B" SG_ 461 HuBCmTiltVrCmdReq 0;
BA_ "GenSigTimeoutTime_HU_A" SG_ 461 HuBCmTiltVrCmdReq 0;
BA_ "GenSigTimeoutMsg_HU_Mid_X451" SG_ 461 HuBCmTiltVrCmdReq 0;
BA_ "GenSigTimeoutMsg_HU_High_X451" SG_ 461 HuBCmTiltVrCmdReq 0;
BA_ "GenSigTimeoutMsg_HU_B" SG_ 461 HuBCmTiltVrCmdReq 0;
BA_ "GenSigTimeoutMsg_HU_A" SG_ 461 HuBCmTiltVrCmdReq 0;
BA_ "GenSigSendType" SG_ 461 HuBCmTiltVrCmdReq 2;
BA_ "GenSigTimeoutMsg_HU_High_X445" SG_ 461 HuBCmTiltVrCmdReq 0;
BA_ "GenSigTimeoutMsg_HU_Mid_X445" SG_ 461 HuBCmTiltVrCmdReq 0;
BA_ "GenSigTimeoutTime_HU_High_X445" SG_ 461 HuBCmTiltVrCmdReq 0;
BA_ "GenSigTimeoutTime_HU_Mid_X445" SG_ 461 HuBCmTiltVrCmdReq 0;
BA_ "GenSigTimeoutMsg_IVI" SG_ 461 HuBCmTiltVrCmdReq 0;
BA_ "GenSigTimeoutTime_IVI" SG_ 461 HuBCmTiltVrCmdReq 0;
BA_ "GenSigTimeoutTime_HU_Mid_X451" SG_ 461 HuBCmSunShadeVrCmdReq 0;
BA_ "GenSigTimeoutTime_HU_High_X451" SG_ 461 HuBCmSunShadeVrCmdReq 0;
BA_ "GenSigTimeoutTime_HU_B" SG_ 461 HuBCmSunShadeVrCmdReq 0;
BA_ "GenSigTimeoutTime_HU_A" SG_ 461 HuBCmSunShadeVrCmdReq 0;
BA_ "GenSigTimeoutMsg_HU_Mid_X451" SG_ 461 HuBCmSunShadeVrCmdReq 0;
BA_ "GenSigTimeoutMsg_HU_High_X451" SG_ 461 HuBCmSunShadeVrCmdReq 0;
BA_ "GenSigTimeoutMsg_HU_B" SG_ 461 HuBCmSunShadeVrCmdReq 0;
BA_ "GenSigTimeoutMsg_HU_A" SG_ 461 HuBCmSunShadeVrCmdReq 0;
BA_ "GenSigSendType" SG_ 461 HuBCmSunShadeVrCmdReq 2;
BA_ "GenSigTimeoutMsg_HU_High_X445" SG_ 461 HuBCmSunShadeVrCmdReq 0;
BA_ "GenSigTimeoutMsg_HU_Mid_X445" SG_ 461 HuBCmSunShadeVrCmdReq 0;
BA_ "GenSigTimeoutTime_HU_High_X445" SG_ 461 HuBCmSunShadeVrCmdReq 0;
BA_ "GenSigTimeoutTime_HU_Mid_X445" SG_ 461 HuBCmSunShadeVrCmdReq 0;
BA_ "GenSigTimeoutMsg_IVI" SG_ 461 HuBCmSunShadeVrCmdReq 0;
BA_ "GenSigTimeoutTime_IVI" SG_ 461 HuBCmSunShadeVrCmdReq 0;
BA_ "GenSigTimeoutTime_HU_Mid_X451" SG_ 461 HuBCmSunRoofVrCmdReq 0;
BA_ "GenSigTimeoutTime_HU_High_X451" SG_ 461 HuBCmSunRoofVrCmdReq 0;
BA_ "GenSigTimeoutTime_HU_B" SG_ 461 HuBCmSunRoofVrCmdReq 0;
BA_ "GenSigTimeoutTime_HU_A" SG_ 461 HuBCmSunRoofVrCmdReq 0;
BA_ "GenSigTimeoutMsg_HU_Mid_X451" SG_ 461 HuBCmSunRoofVrCmdReq 0;
BA_ "GenSigTimeoutMsg_HU_High_X451" SG_ 461 HuBCmSunRoofVrCmdReq 0;
BA_ "GenSigTimeoutMsg_HU_B" SG_ 461 HuBCmSunRoofVrCmdReq 0;
BA_ "GenSigTimeoutMsg_HU_A" SG_ 461 HuBCmSunRoofVrCmdReq 0;
BA_ "GenSigSendType" SG_ 461 HuBCmSunRoofVrCmdReq 2;
BA_ "GenSigTimeoutMsg_HU_High_X445" SG_ 461 HuBCmSunRoofVrCmdReq 0;
BA_ "GenSigTimeoutMsg_HU_Mid_X445" SG_ 461 HuBCmSunRoofVrCmdReq 0;
BA_ "GenSigTimeoutTime_HU_High_X445" SG_ 461 HuBCmSunRoofVrCmdReq 0;
BA_ "GenSigTimeoutTime_HU_Mid_X445" SG_ 461 HuBCmSunRoofVrCmdReq 0;
BA_ "GenSigTimeoutMsg_IVI" SG_ 461 HuBCmSunRoofVrCmdReq 0;
BA_ "GenSigTimeoutTime_IVI" SG_ 461 HuBCmSunRoofVrCmdReq 0;
BA_ "GenSigTimeoutTime_HU_Mid_X451" SG_ 489 BCmHuWindowWindingHmiCmdSupport 0;
BA_ "GenSigTimeoutTime_HU_High_X451" SG_ 489 BCmHuWindowWindingHmiCmdSupport 0;
BA_ "GenSigTimeoutTime_HU_B" SG_ 489 BCmHuWindowWindingHmiCmdSupport 0;
BA_ "GenSigTimeoutTime_HU_A" SG_ 489 BCmHuWindowWindingHmiCmdSupport 0;
BA_ "GenSigTimeoutMsg_HU_Mid_X451" SG_ 489 BCmHuWindowWindingHmiCmdSupport 0;
BA_ "GenSigTimeoutMsg_HU_High_X451" SG_ 489 BCmHuWindowWindingHmiCmdSupport 0;
BA_ "GenSigTimeoutMsg_HU_B" SG_ 489 BCmHuWindowWindingHmiCmdSupport 0;
BA_ "GenSigTimeoutMsg_HU_A" SG_ 489 BCmHuWindowWindingHmiCmdSupport 0;
BA_ "GenSigSendType" SG_ 489 BCmHuWindowWindingHmiCmdSupport 2;
BA_ "GenSigTimeoutMsg_HU_High_X445" SG_ 489 BCmHuWindowWindingHmiCmdSupport 0;
BA_ "GenSigTimeoutMsg_HU_Mid_X445" SG_ 489 BCmHuWindowWindingHmiCmdSupport 0;
BA_ "GenSigTimeoutTime_HU_High_X445" SG_ 489 BCmHuWindowWindingHmiCmdSupport 0;
BA_ "GenSigTimeoutTime_HU_Mid_X445" SG_ 489 BCmHuWindowWindingHmiCmdSupport 0;
BA_ "GenSigTimeoutMsg_IVI" SG_ 489 BCmHuWindowWindingHmiCmdSupport 0;
BA_ "GenSigTimeoutTime_IVI" SG_ 489 BCmHuWindowWindingHmiCmdSupport 0;
BA_ "GenSigTimeoutTime_HU_Mid_X451" SG_ 489 BCmHuTyreTempVrCmdSupport 0;
BA_ "GenSigTimeoutTime_HU_High_X451" SG_ 489 BCmHuTyreTempVrCmdSupport 0;
BA_ "GenSigTimeoutTime_HU_B" SG_ 489 BCmHuTyreTempVrCmdSupport 0;
BA_ "GenSigTimeoutTime_HU_A" SG_ 489 BCmHuTyreTempVrCmdSupport 0;
BA_ "GenSigTimeoutMsg_HU_Mid_X451" SG_ 489 BCmHuTyreTempVrCmdSupport 0;
BA_ "GenSigTimeoutMsg_HU_High_X451" SG_ 489 BCmHuTyreTempVrCmdSupport 0;
BA_ "GenSigTimeoutMsg_HU_B" SG_ 489 BCmHuTyreTempVrCmdSupport 0;
BA_ "GenSigTimeoutMsg_HU_A" SG_ 489 BCmHuTyreTempVrCmdSupport 0;
BA_ "GenSigSendType" SG_ 489 BCmHuTyreTempVrCmdSupport 2;
BA_ "GenSigTimeoutMsg_HU_High_X445" SG_ 489 BCmHuTyreTempVrCmdSupport 0;
BA_ "GenSigTimeoutMsg_HU_Mid_X445" SG_ 489 BCmHuTyreTempVrCmdSupport 0;
BA_ "GenSigTimeoutTime_HU_High_X445" SG_ 489 BCmHuTyreTempVrCmdSupport 0;
BA_ "GenSigTimeoutTime_HU_Mid_X445" SG_ 489 BCmHuTyreTempVrCmdSupport 0;
BA_ "GenSigTimeoutMsg_IVI" SG_ 489 BCmHuTyreTempVrCmdSupport 0;
BA_ "GenSigTimeoutTime_IVI" SG_ 489 BCmHuTyreTempVrCmdSupport 0;
BA_ "GenSigTimeoutTime_HU_Mid_X451" SG_ 489 BCmHuTyreTempHmiCmdSupport 0;
BA_ "GenSigTimeoutTime_HU_High_X451" SG_ 489 BCmHuTyreTempHmiCmdSupport 0;
BA_ "GenSigTimeoutTime_HU_B" SG_ 489 BCmHuTyreTempHmiCmdSupport 0;
BA_ "GenSigTimeoutTime_HU_A" SG_ 489 BCmHuTyreTempHmiCmdSupport 0;
BA_ "GenSigTimeoutMsg_HU_Mid_X451" SG_ 489 BCmHuTyreTempHmiCmdSupport 0;
BA_ "GenSigTimeoutMsg_HU_High_X451" SG_ 489 BCmHuTyreTempHmiCmdSupport 0;
BA_ "GenSigTimeoutMsg_HU_B" SG_ 489 BCmHuTyreTempHmiCmdSupport 0;
BA_ "GenSigTimeoutMsg_HU_A" SG_ 489 BCmHuTyreTempHmiCmdSupport 0;
BA_ "GenSigSendType" SG_ 489 BCmHuTyreTempHmiCmdSupport 2;
BA_ "GenSigTimeoutMsg_HU_High_X445" SG_ 489 BCmHuTyreTempHmiCmdSupport 0;
BA_ "GenSigTimeoutMsg_HU_Mid_X445" SG_ 489 BCmHuTyreTempHmiCmdSupport 0;
BA_ "GenSigTimeoutTime_HU_High_X445" SG_ 489 BCmHuTyreTempHmiCmdSupport 0;
BA_ "GenSigTimeoutTime_HU_Mid_X445" SG_ 489 BCmHuTyreTempHmiCmdSupport 0;
BA_ "GenSigTimeoutMsg_IVI" SG_ 489 BCmHuTyreTempHmiCmdSupport 0;
BA_ "GenSigTimeoutTime_IVI" SG_ 489 BCmHuTyreTempHmiCmdSupport 0;
BA_ "GenSigTimeoutTime_HU_Mid_X451" SG_ 489 BCmHuTyrePressureVrCmdSupport 0;
BA_ "GenSigTimeoutTime_HU_High_X451" SG_ 489 BCmHuTyrePressureVrCmdSupport 0;
BA_ "GenSigTimeoutTime_HU_B" SG_ 489 BCmHuTyrePressureVrCmdSupport 0;
BA_ "GenSigTimeoutTime_HU_A" SG_ 489 BCmHuTyrePressureVrCmdSupport 0;
BA_ "GenSigTimeoutMsg_HU_Mid_X451" SG_ 489 BCmHuTyrePressureVrCmdSupport 0;
BA_ "GenSigTimeoutMsg_HU_High_X451" SG_ 489 BCmHuTyrePressureVrCmdSupport 0;
BA_ "GenSigTimeoutMsg_HU_B" SG_ 489 BCmHuTyrePressureVrCmdSupport 0;
BA_ "GenSigTimeoutMsg_HU_A" SG_ 489 BCmHuTyrePressureVrCmdSupport 0;
BA_ "GenSigSendType" SG_ 489 BCmHuTyrePressureVrCmdSupport 2;
BA_ "GenSigTimeoutMsg_HU_High_X445" SG_ 489 BCmHuTyrePressureVrCmdSupport 0;
BA_ "GenSigTimeoutMsg_HU_Mid_X445" SG_ 489 BCmHuTyrePressureVrCmdSupport 0;
BA_ "GenSigTimeoutTime_HU_High_X445" SG_ 489 BCmHuTyrePressureVrCmdSupport 0;
BA_ "GenSigTimeoutTime_HU_Mid_X445" SG_ 489 BCmHuTyrePressureVrCmdSupport 0;
BA_ "GenSigTimeoutMsg_IVI" SG_ 489 BCmHuTyrePressureVrCmdSupport 0;
BA_ "GenSigTimeoutTime_IVI" SG_ 489 BCmHuTyrePressureVrCmdSupport 0;
BA_ "GenSigTimeoutTime_HU_Mid_X451" SG_ 489 BCmHuTyrePressureHmiCmdSupport 0;
BA_ "GenSigTimeoutTime_HU_High_X451" SG_ 489 BCmHuTyrePressureHmiCmdSupport 0;
BA_ "GenSigTimeoutTime_HU_B" SG_ 489 BCmHuTyrePressureHmiCmdSupport 0;
BA_ "GenSigTimeoutTime_HU_A" SG_ 489 BCmHuTyrePressureHmiCmdSupport 0;
BA_ "GenSigTimeoutMsg_HU_Mid_X451" SG_ 489 BCmHuTyrePressureHmiCmdSupport 0;
BA_ "GenSigTimeoutMsg_HU_High_X451" SG_ 489 BCmHuTyrePressureHmiCmdSupport 0;
BA_ "GenSigTimeoutMsg_HU_B" SG_ 489 BCmHuTyrePressureHmiCmdSupport 0;
BA_ "GenSigTimeoutMsg_HU_A" SG_ 489 BCmHuTyrePressureHmiCmdSupport 0;
BA_ "GenSigSendType" SG_ 489 BCmHuTyrePressureHmiCmdSupport 2;
BA_ "GenSigTimeoutMsg_HU_High_X445" SG_ 489 BCmHuTyrePressureHmiCmdSupport 0;
BA_ "GenSigTimeoutMsg_HU_Mid_X445" SG_ 489 BCmHuTyrePressureHmiCmdSupport 0;
BA_ "GenSigTimeoutTime_HU_High_X445" SG_ 489 BCmHuTyrePressureHmiCmdSupport 0;
BA_ "GenSigTimeoutTime_HU_Mid_X445" SG_ 489 BCmHuTyrePressureHmiCmdSupport 0;
BA_ "GenSigTimeoutMsg_IVI" SG_ 489 BCmHuTyrePressureHmiCmdSupport 0;
BA_ "GenSigTimeoutTime_IVI" SG_ 489 BCmHuTyrePressureHmiCmdSupport 0;
BA_ "GenSigTimeoutTime_HU_Mid_X451" SG_ 489 BCmHuSunroofTiltVrCmdSupport 0;
BA_ "GenSigTimeoutTime_HU_High_X451" SG_ 489 BCmHuSunroofTiltVrCmdSupport 0;
BA_ "GenSigTimeoutTime_HU_B" SG_ 489 BCmHuSunroofTiltVrCmdSupport 0;
BA_ "GenSigTimeoutTime_HU_A" SG_ 489 BCmHuSunroofTiltVrCmdSupport 0;
BA_ "GenSigTimeoutMsg_HU_Mid_X451" SG_ 489 BCmHuSunroofTiltVrCmdSupport 0;
BA_ "GenSigTimeoutMsg_HU_High_X451" SG_ 489 BCmHuSunroofTiltVrCmdSupport 0;
BA_ "GenSigTimeoutMsg_HU_B" SG_ 489 BCmHuSunroofTiltVrCmdSupport 0;
BA_ "GenSigTimeoutMsg_HU_A" SG_ 489 BCmHuSunroofTiltVrCmdSupport 0;
BA_ "GenSigSendType" SG_ 489 BCmHuSunroofTiltVrCmdSupport 2;
BA_ "GenSigTimeoutMsg_HU_High_X445" SG_ 489 BCmHuSunroofTiltVrCmdSupport 0;
BA_ "GenSigTimeoutMsg_HU_Mid_X445" SG_ 489 BCmHuSunroofTiltVrCmdSupport 0;
BA_ "GenSigTimeoutTime_HU_High_X445" SG_ 489 BCmHuSunroofTiltVrCmdSupport 0;
BA_ "GenSigTimeoutTime_HU_Mid_X445" SG_ 489 BCmHuSunroofTiltVrCmdSupport 0;
BA_ "GenSigTimeoutMsg_IVI" SG_ 489 BCmHuSunroofTiltVrCmdSupport 0;
BA_ "GenSigTimeoutTime_IVI" SG_ 489 BCmHuSunroofTiltVrCmdSupport 0;
BA_ "GenSigTimeoutTime_HU_Mid_X451" SG_ 489 BCmHuRoofLampVrCmdSupport 0;
BA_ "GenSigTimeoutTime_HU_High_X451" SG_ 489 BCmHuRoofLampVrCmdSupport 0;
BA_ "GenSigTimeoutTime_HU_B" SG_ 489 BCmHuRoofLampVrCmdSupport 0;
BA_ "GenSigTimeoutTime_HU_A" SG_ 489 BCmHuRoofLampVrCmdSupport 0;
BA_ "GenSigTimeoutMsg_HU_Mid_X451" SG_ 489 BCmHuRoofLampVrCmdSupport 0;
BA_ "GenSigTimeoutMsg_HU_High_X451" SG_ 489 BCmHuRoofLampVrCmdSupport 0;
BA_ "GenSigTimeoutMsg_HU_B" SG_ 489 BCmHuRoofLampVrCmdSupport 0;
BA_ "GenSigTimeoutMsg_HU_A" SG_ 489 BCmHuRoofLampVrCmdSupport 0;
BA_ "GenSigSendType" SG_ 489 BCmHuRoofLampVrCmdSupport 2;
BA_ "GenSigTimeoutMsg_HU_High_X445" SG_ 489 BCmHuRoofLampVrCmdSupport 0;
BA_ "GenSigTimeoutMsg_HU_Mid_X445" SG_ 489 BCmHuRoofLampVrCmdSupport 0;
BA_ "GenSigTimeoutTime_HU_High_X445" SG_ 489 BCmHuRoofLampVrCmdSupport 0;
BA_ "GenSigTimeoutTime_HU_Mid_X445" SG_ 489 BCmHuRoofLampVrCmdSupport 0;
BA_ "GenSigTimeoutMsg_IVI" SG_ 489 BCmHuRoofLampVrCmdSupport 0;
BA_ "GenSigTimeoutTime_IVI" SG_ 489 BCmHuRoofLampVrCmdSupport 0;
BA_ "GenSigTimeoutTime_HU_Mid_X451" SG_ 489 BCmHuRoofLampHmiCmdSupport 0;
BA_ "GenSigTimeoutTime_HU_High_X451" SG_ 489 BCmHuRoofLampHmiCmdSupport 0;
BA_ "GenSigTimeoutTime_HU_B" SG_ 489 BCmHuRoofLampHmiCmdSupport 0;
BA_ "GenSigTimeoutTime_HU_A" SG_ 489 BCmHuRoofLampHmiCmdSupport 0;
BA_ "GenSigTimeoutMsg_HU_Mid_X451" SG_ 489 BCmHuRoofLampHmiCmdSupport 0;
BA_ "GenSigTimeoutMsg_HU_High_X451" SG_ 489 BCmHuRoofLampHmiCmdSupport 0;
BA_ "GenSigTimeoutMsg_HU_B" SG_ 489 BCmHuRoofLampHmiCmdSupport 0;
BA_ "GenSigTimeoutMsg_HU_A" SG_ 489 BCmHuRoofLampHmiCmdSupport 0;
BA_ "GenSigSendType" SG_ 489 BCmHuRoofLampHmiCmdSupport 2;
BA_ "GenSigTimeoutMsg_HU_High_X445" SG_ 489 BCmHuRoofLampHmiCmdSupport 0;
BA_ "GenSigTimeoutMsg_HU_Mid_X445" SG_ 489 BCmHuRoofLampHmiCmdSupport 0;
BA_ "GenSigTimeoutTime_HU_High_X445" SG_ 489 BCmHuRoofLampHmiCmdSupport 0;
BA_ "GenSigTimeoutTime_HU_Mid_X445" SG_ 489 BCmHuRoofLampHmiCmdSupport 0;
BA_ "GenSigTimeoutMsg_IVI" SG_ 489 BCmHuRoofLampHmiCmdSupport 0;
BA_ "GenSigTimeoutTime_IVI" SG_ 489 BCmHuRoofLampHmiCmdSupport 0;
BA_ "GenSigTimeoutTime_HU_Mid_X451" SG_ 489 BCmHuPositionLampVrCmdSupport 0;
BA_ "GenSigTimeoutTime_HU_High_X451" SG_ 489 BCmHuPositionLampVrCmdSupport 0;
BA_ "GenSigTimeoutTime_HU_B" SG_ 489 BCmHuPositionLampVrCmdSupport 0;
BA_ "GenSigTimeoutTime_HU_A" SG_ 489 BCmHuPositionLampVrCmdSupport 0;
BA_ "GenSigTimeoutMsg_HU_Mid_X451" SG_ 489 BCmHuPositionLampVrCmdSupport 0;
BA_ "GenSigTimeoutMsg_HU_High_X451" SG_ 489 BCmHuPositionLampVrCmdSupport 0;
BA_ "GenSigTimeoutMsg_HU_B" SG_ 489 BCmHuPositionLampVrCmdSupport 0;
BA_ "GenSigTimeoutMsg_HU_A" SG_ 489 BCmHuPositionLampVrCmdSupport 0;
BA_ "GenSigSendType" SG_ 489 BCmHuPositionLampVrCmdSupport 2;
BA_ "GenSigTimeoutMsg_HU_High_X445" SG_ 489 BCmHuPositionLampVrCmdSupport 0;
BA_ "GenSigTimeoutMsg_HU_Mid_X445" SG_ 489 BCmHuPositionLampVrCmdSupport 0;
BA_ "GenSigTimeoutTime_HU_High_X445" SG_ 489 BCmHuPositionLampVrCmdSupport 0;
BA_ "GenSigTimeoutTime_HU_Mid_X445" SG_ 489 BCmHuPositionLampVrCmdSupport 0;
BA_ "GenSigTimeoutMsg_IVI" SG_ 489 BCmHuPositionLampVrCmdSupport 0;
BA_ "GenSigTimeoutTime_IVI" SG_ 489 BCmHuPositionLampVrCmdSupport 0;
BA_ "GenSigTimeoutTime_HU_Mid_X451" SG_ 489 BCmHuORVMVrCmdSupport 0;
BA_ "GenSigTimeoutTime_HU_High_X451" SG_ 489 BCmHuORVMVrCmdSupport 0;
BA_ "GenSigTimeoutTime_HU_B" SG_ 489 BCmHuORVMVrCmdSupport 0;
BA_ "GenSigTimeoutTime_HU_A" SG_ 489 BCmHuORVMVrCmdSupport 0;
BA_ "GenSigTimeoutMsg_HU_Mid_X451" SG_ 489 BCmHuORVMVrCmdSupport 0;
BA_ "GenSigTimeoutMsg_HU_High_X451" SG_ 489 BCmHuORVMVrCmdSupport 0;
BA_ "GenSigTimeoutMsg_HU_B" SG_ 489 BCmHuORVMVrCmdSupport 0;
BA_ "GenSigTimeoutMsg_HU_A" SG_ 489 BCmHuORVMVrCmdSupport 0;
BA_ "GenSigSendType" SG_ 489 BCmHuORVMVrCmdSupport 2;
BA_ "GenSigTimeoutMsg_HU_High_X445" SG_ 489 BCmHuORVMVrCmdSupport 0;
BA_ "GenSigTimeoutMsg_HU_Mid_X445" SG_ 489 BCmHuORVMVrCmdSupport 0;
BA_ "GenSigTimeoutTime_HU_High_X445" SG_ 489 BCmHuORVMVrCmdSupport 0;
BA_ "GenSigTimeoutTime_HU_Mid_X445" SG_ 489 BCmHuORVMVrCmdSupport 0;
BA_ "GenSigTimeoutMsg_IVI" SG_ 489 BCmHuORVMVrCmdSupport 0;
BA_ "GenSigTimeoutTime_IVI" SG_ 489 BCmHuORVMVrCmdSupport 0;
BA_ "GenSigTimeoutTime_HU_Mid_X451" SG_ 489 BCmHuORVMHmiCmdSupport 0;
BA_ "GenSigTimeoutTime_HU_High_X451" SG_ 489 BCmHuORVMHmiCmdSupport 0;
BA_ "GenSigTimeoutTime_HU_B" SG_ 489 BCmHuORVMHmiCmdSupport 0;
BA_ "GenSigTimeoutTime_HU_A" SG_ 489 BCmHuORVMHmiCmdSupport 0;
BA_ "GenSigTimeoutMsg_HU_Mid_X451" SG_ 489 BCmHuORVMHmiCmdSupport 0;
BA_ "GenSigTimeoutMsg_HU_High_X451" SG_ 489 BCmHuORVMHmiCmdSupport 0;
BA_ "GenSigTimeoutMsg_HU_B" SG_ 489 BCmHuORVMHmiCmdSupport 0;
BA_ "GenSigTimeoutMsg_HU_A" SG_ 489 BCmHuORVMHmiCmdSupport 0;
BA_ "GenSigSendType" SG_ 489 BCmHuORVMHmiCmdSupport 2;
BA_ "GenSigTimeoutMsg_HU_High_X445" SG_ 489 BCmHuORVMHmiCmdSupport 0;
BA_ "GenSigTimeoutMsg_HU_Mid_X445" SG_ 489 BCmHuORVMHmiCmdSupport 0;
BA_ "GenSigTimeoutTime_HU_High_X445" SG_ 489 BCmHuORVMHmiCmdSupport 0;
BA_ "GenSigTimeoutTime_HU_Mid_X445" SG_ 489 BCmHuORVMHmiCmdSupport 0;
BA_ "GenSigTimeoutMsg_IVI" SG_ 489 BCmHuORVMHmiCmdSupport 0;
BA_ "GenSigTimeoutTime_IVI" SG_ 489 BCmHuORVMHmiCmdSupport 0;
BA_ "GenSigTimeoutTime_HU_Mid_X451" SG_ 489 BCmHuMoodLightVrCmdSupport 0;
BA_ "GenSigTimeoutTime_HU_High_X451" SG_ 489 BCmHuMoodLightVrCmdSupport 0;
BA_ "GenSigTimeoutTime_HU_B" SG_ 489 BCmHuMoodLightVrCmdSupport 0;
BA_ "GenSigTimeoutTime_HU_A" SG_ 489 BCmHuMoodLightVrCmdSupport 0;
BA_ "GenSigTimeoutMsg_HU_Mid_X451" SG_ 489 BCmHuMoodLightVrCmdSupport 0;
BA_ "GenSigTimeoutMsg_HU_High_X451" SG_ 489 BCmHuMoodLightVrCmdSupport 0;
BA_ "GenSigTimeoutMsg_HU_B" SG_ 489 BCmHuMoodLightVrCmdSupport 0;
BA_ "GenSigTimeoutMsg_HU_A" SG_ 489 BCmHuMoodLightVrCmdSupport 0;
BA_ "GenSigSendType" SG_ 489 BCmHuMoodLightVrCmdSupport 2;
BA_ "GenSigTimeoutMsg_HU_High_X445" SG_ 489 BCmHuMoodLightVrCmdSupport 0;
BA_ "GenSigTimeoutMsg_HU_Mid_X445" SG_ 489 BCmHuMoodLightVrCmdSupport 0;
BA_ "GenSigTimeoutTime_HU_High_X445" SG_ 489 BCmHuMoodLightVrCmdSupport 0;
BA_ "GenSigTimeoutTime_HU_Mid_X445" SG_ 489 BCmHuMoodLightVrCmdSupport 0;
BA_ "GenSigTimeoutMsg_IVI" SG_ 489 BCmHuMoodLightVrCmdSupport 0;
BA_ "GenSigTimeoutTime_IVI" SG_ 489 BCmHuMoodLightVrCmdSupport 0;
BA_ "GenSigTimeoutTime_HU_Mid_X451" SG_ 489 BCmHuHazardLampVrCmdSupport 0;
BA_ "GenSigTimeoutTime_HU_High_X451" SG_ 489 BCmHuHazardLampVrCmdSupport 0;
BA_ "GenSigTimeoutTime_HU_B" SG_ 489 BCmHuHazardLampVrCmdSupport 0;
BA_ "GenSigTimeoutTime_HU_A" SG_ 489 BCmHuHazardLampVrCmdSupport 0;
BA_ "GenSigTimeoutMsg_HU_Mid_X451" SG_ 489 BCmHuHazardLampVrCmdSupport 0;
BA_ "GenSigTimeoutMsg_HU_High_X451" SG_ 489 BCmHuHazardLampVrCmdSupport 0;
BA_ "GenSigTimeoutMsg_HU_B" SG_ 489 BCmHuHazardLampVrCmdSupport 0;
BA_ "GenSigTimeoutMsg_HU_A" SG_ 489 BCmHuHazardLampVrCmdSupport 0;
BA_ "GenSigSendType" SG_ 489 BCmHuHazardLampVrCmdSupport 2;
BA_ "GenSigTimeoutMsg_HU_High_X445" SG_ 489 BCmHuHazardLampVrCmdSupport 0;
BA_ "GenSigTimeoutMsg_HU_Mid_X445" SG_ 489 BCmHuHazardLampVrCmdSupport 0;
BA_ "GenSigTimeoutTime_HU_High_X445" SG_ 489 BCmHuHazardLampVrCmdSupport 0;
BA_ "GenSigTimeoutTime_HU_Mid_X445" SG_ 489 BCmHuHazardLampVrCmdSupport 0;
BA_ "GenSigTimeoutMsg_IVI" SG_ 489 BCmHuHazardLampVrCmdSupport 0;
BA_ "GenSigTimeoutTime_IVI" SG_ 489 BCmHuHazardLampVrCmdSupport 0;
BA_ "GenSigTimeoutTime_HU_Mid_X451" SG_ 489 BCmHuDRLVrCmdSupport 0;
BA_ "GenSigTimeoutTime_HU_High_X451" SG_ 489 BCmHuDRLVrCmdSupport 0;
BA_ "GenSigTimeoutTime_HU_B" SG_ 489 BCmHuDRLVrCmdSupport 0;
BA_ "GenSigTimeoutTime_HU_A" SG_ 489 BCmHuDRLVrCmdSupport 0;
BA_ "GenSigTimeoutMsg_HU_Mid_X451" SG_ 489 BCmHuDRLVrCmdSupport 0;
BA_ "GenSigTimeoutMsg_HU_High_X451" SG_ 489 BCmHuDRLVrCmdSupport 0;
BA_ "GenSigTimeoutMsg_HU_B" SG_ 489 BCmHuDRLVrCmdSupport 0;
BA_ "GenSigTimeoutMsg_HU_A" SG_ 489 BCmHuDRLVrCmdSupport 0;
BA_ "GenSigSendType" SG_ 489 BCmHuDRLVrCmdSupport 2;
BA_ "GenSigTimeoutMsg_HU_High_X445" SG_ 489 BCmHuDRLVrCmdSupport 0;
BA_ "GenSigTimeoutMsg_HU_Mid_X445" SG_ 489 BCmHuDRLVrCmdSupport 0;
BA_ "GenSigTimeoutTime_HU_High_X445" SG_ 489 BCmHuDRLVrCmdSupport 0;
BA_ "GenSigTimeoutTime_HU_Mid_X445" SG_ 489 BCmHuDRLVrCmdSupport 0;
BA_ "GenSigTimeoutMsg_IVI" SG_ 489 BCmHuDRLVrCmdSupport 0;
BA_ "GenSigTimeoutTime_IVI" SG_ 489 BCmHuDRLVrCmdSupport 0;
BA_ "GenSigTimeoutTime_HU_Mid_X451" SG_ 489 BCmHuAmbientLightVrCmdSupport 0;
BA_ "GenSigTimeoutTime_HU_High_X451" SG_ 489 BCmHuAmbientLightVrCmdSupport 0;
BA_ "GenSigTimeoutTime_HU_B" SG_ 489 BCmHuAmbientLightVrCmdSupport 0;
BA_ "GenSigTimeoutTime_HU_A" SG_ 489 BCmHuAmbientLightVrCmdSupport 0;
BA_ "GenSigTimeoutMsg_HU_Mid_X451" SG_ 489 BCmHuAmbientLightVrCmdSupport 0;
BA_ "GenSigTimeoutMsg_HU_High_X451" SG_ 489 BCmHuAmbientLightVrCmdSupport 0;
BA_ "GenSigTimeoutMsg_HU_B" SG_ 489 BCmHuAmbientLightVrCmdSupport 0;
BA_ "GenSigTimeoutMsg_HU_A" SG_ 489 BCmHuAmbientLightVrCmdSupport 0;
BA_ "GenSigSendType" SG_ 489 BCmHuAmbientLightVrCmdSupport 2;
BA_ "GenSigTimeoutMsg_HU_High_X445" SG_ 489 BCmHuAmbientLightVrCmdSupport 0;
BA_ "GenSigTimeoutMsg_HU_Mid_X445" SG_ 489 BCmHuAmbientLightVrCmdSupport 0;
BA_ "GenSigTimeoutTime_HU_High_X445" SG_ 489 BCmHuAmbientLightVrCmdSupport 0;
BA_ "GenSigTimeoutTime_HU_Mid_X445" SG_ 489 BCmHuAmbientLightVrCmdSupport 0;
BA_ "GenSigTimeoutMsg_IVI" SG_ 489 BCmHuAmbientLightVrCmdSupport 0;
BA_ "GenSigTimeoutTime_IVI" SG_ 489 BCmHuAmbientLightVrCmdSupport 0;
BA_ "GenSigTimeoutTime_HU_Mid_X451" SG_ 489 BCmHuSunShadeVrCmdSupport 0;
BA_ "GenSigTimeoutTime_HU_High_X451" SG_ 489 BCmHuSunShadeVrCmdSupport 0;
BA_ "GenSigTimeoutTime_HU_B" SG_ 489 BCmHuSunShadeVrCmdSupport 0;
BA_ "GenSigTimeoutTime_HU_A" SG_ 489 BCmHuSunShadeVrCmdSupport 0;
BA_ "GenSigTimeoutMsg_HU_Mid_X451" SG_ 489 BCmHuSunShadeVrCmdSupport 0;
BA_ "GenSigTimeoutMsg_HU_High_X451" SG_ 489 BCmHuSunShadeVrCmdSupport 0;
BA_ "GenSigTimeoutMsg_HU_B" SG_ 489 BCmHuSunShadeVrCmdSupport 0;
BA_ "GenSigTimeoutMsg_HU_A" SG_ 489 BCmHuSunShadeVrCmdSupport 0;
BA_ "GenSigSendType" SG_ 489 BCmHuSunShadeVrCmdSupport 2;
BA_ "GenSigTimeoutMsg_HU_High_X445" SG_ 489 BCmHuSunShadeVrCmdSupport 0;
BA_ "GenSigTimeoutMsg_HU_Mid_X445" SG_ 489 BCmHuSunShadeVrCmdSupport 0;
BA_ "GenSigTimeoutTime_HU_High_X445" SG_ 489 BCmHuSunShadeVrCmdSupport 0;
BA_ "GenSigTimeoutTime_HU_Mid_X445" SG_ 489 BCmHuSunShadeVrCmdSupport 0;
BA_ "GenSigTimeoutMsg_IVI" SG_ 489 BCmHuSunShadeVrCmdSupport 0;
BA_ "GenSigTimeoutTime_IVI" SG_ 489 BCmHuSunShadeVrCmdSupport 0;
BA_ "GenSigTimeoutTime_HU_Mid_X451" SG_ 489 BCmHuSunRoofVrCmdSupport 0;
BA_ "GenSigTimeoutTime_HU_High_X451" SG_ 489 BCmHuSunRoofVrCmdSupport 0;
BA_ "GenSigTimeoutTime_HU_B" SG_ 489 BCmHuSunRoofVrCmdSupport 0;
BA_ "GenSigTimeoutTime_HU_A" SG_ 489 BCmHuSunRoofVrCmdSupport 0;
BA_ "GenSigTimeoutMsg_HU_Mid_X451" SG_ 489 BCmHuSunRoofVrCmdSupport 0;
BA_ "GenSigTimeoutMsg_HU_High_X451" SG_ 489 BCmHuSunRoofVrCmdSupport 0;
BA_ "GenSigTimeoutMsg_HU_B" SG_ 489 BCmHuSunRoofVrCmdSupport 0;
BA_ "GenSigTimeoutMsg_HU_A" SG_ 489 BCmHuSunRoofVrCmdSupport 0;
BA_ "GenSigSendType" SG_ 489 BCmHuSunRoofVrCmdSupport 2;
BA_ "GenSigTimeoutMsg_HU_High_X445" SG_ 489 BCmHuSunRoofVrCmdSupport 0;
BA_ "GenSigTimeoutMsg_HU_Mid_X445" SG_ 489 BCmHuSunRoofVrCmdSupport 0;
BA_ "GenSigTimeoutTime_HU_High_X445" SG_ 489 BCmHuSunRoofVrCmdSupport 0;
BA_ "GenSigTimeoutTime_HU_Mid_X445" SG_ 489 BCmHuSunRoofVrCmdSupport 0;
BA_ "GenSigTimeoutMsg_IVI" SG_ 489 BCmHuSunRoofVrCmdSupport 0;
BA_ "GenSigTimeoutTime_IVI" SG_ 489 BCmHuSunRoofVrCmdSupport 0;
VAL_ 473 HuETcLowTempConfigValueAck 15 "Hot Level Request 8" 14 "Hot Level Request 7" 13 "Hot Level Request 6" 12 "Hot Level Request 5" 11 "Hot Level Request 4" 10 "Hot Level Request 3" 9 "Hot Level Request 2" 8 "Hot Level Request 1" 7 "Cool Level Request 1" 6 "Cool Level Request 2" 5 "Cool Level Request 3" 4 "Cool Level Request 4" 3 "Cool Level Request 5" 2 "Cool Level Request 6" 1 "Cool Level Request 7" 0 "Cool Level Request 8" ;
VAL_ 473 HuETcLowFanSpdConfigValueAck 7 "Reserved" 6 "Reserved" 5 "Reserved" 4 "Fan Speed 4 " 3 "Fan Speed 3" 2 "Fan Speed 2 " 1 "Fan Speed 1 " 0 "Fan Speed 0 " ;
VAL_ 473 HuETcHiTempConfigValueAck 15 "Hot Level Request 8" 14 "Hot Level Request 7" 13 "Hot Level Request 6" 12 "Hot Level Request 5" 11 "Hot Level Request 4" 10 "Hot Level Request 3" 9 "Hot Level Request 2" 8 "Hot Level Request 1" 7 "Cool Level Request 1" 6 "Cool Level Request 2" 5 "Cool Level Request 3" 4 "Cool Level Request 4" 3 "Cool Level Request 5" 2 "Cool Level Request 6" 1 "Cool Level Request 7" 0 "Cool Level Request 8" ;
VAL_ 473 HuETcHiFanSpdConfigValueAck 7 "Reserved" 6 "Reserved" 5 "Reserved" 4 "Fan Speed 4 " 3 "Fan Speed 3" 2 "Fan Speed 2 " 1 "Fan Speed 1 " 0 "Fan Speed 0 " ;
VAL_ 473 HuETcTempReq 15 "Hot Level 8" 14 "Hot Level 7" 13 "Hot Level 6" 12 "Hot Level 5" 11 "Hot Level 4" 10 "Hot Level 3" 9 "Hot Level 2" 8 "Hot Level 1 " 7 "Cool Level 1" 6 "Cool Level 2" 5 "Cool Level 3" 4 "Cool Level 4" 3 "Cool Level 5" 2 "Cool Level 6" 1 "Cool Level 7" 0 "Cool Level 8" ;
VAL_ 473 HuETcFanSpdReq 7 "Reserved" 6 "Reserved" 5 "Reserved" 4 "Fan Speed 4 Request" 3 "Fan Speed 3 Request" 2 "Fan Speed 2 Request" 1 "Fan Speed 1 Request" 0 "Fan Speed 0 Request" ;
VAL_ 473 IpcSwcEvent 15 "Reserved" 14 "Reserved" 13 "Reserved" 12 "Short to ground" 11 "Short to BAT" 10 "Open" 9 "Key stuck" 8 "View" 7 "Pagination" 6 "Selection (Thumb)" 5 "Down" 4 "Up" 3 "Reserved" 2 "Paddle Shifter +" 1 "Paddle Shifter -" 0 "No switch pressed" ;
VAL_ 473 IviSwcEvent 15 "Reserved" 14 "Reserved" 13 "Short to ground" 12 "Short to BAT" 11 "Open" 10 "Key stuck" 9 "Push To Talk (PTT)" 8 "Phone Reject" 7 "Volume -" 6 "Mute" 5 "Volume +" 4 "Phone Accept" 3 "SRC" 2 "Seek Up" 1 "Seek Down" 0 "No switch pressed" ;
VAL_ 1141 IPC_MRC_Failure_Status 3 "Reserved" 2 "Failurehealed Ageing in progress" 1 "Failure matured & DTC in memory" 0 "Faiulure is not detected " ;
VAL_ 1141 IPC_CRC_Failure_Status 3 "Reserved" 2 "Failurehealed Ageing in progress" 1 "Failure matured & DTC in memory" 0 "Faiulure is not detected " ;
VAL_ 1141 AT_AMT_DCT_MRC_Failure_Status 3 "Reserved" 2 "Failurehealed Ageing in progress" 1 "Failure matured & DTC in memory" 0 "Faiulure is not detected " ;
VAL_ 1141 AT_AMT_DCT_CRC_Failure_Status 3 "Reserved" 2 "Failurehealed Ageing in progress" 1 "Failure matured & DTC in memory" 0 "Faiulure is not detected " ;
VAL_ 436 PotSwRkeOnOffReqAck 3 "Reserve" 2 "Enable POT by RKE sw User Sel. Successful" 1 "Disable POT by RKE sw User Sel. Successful" 0 "No Action Required" ;
VAL_ 436 PotGestOnOffReqAck 3 "Reserve" 2 "Enable POT by Gesture User Sel. Successful" 1 "Disable POT by Gesture User Sel. Successful" 0 "No Action Required" ;
VAL_ 436 PotBuzzOnOffReqAck 3 "Reserve" 2 "POT buzzer function ON Successful" 1 "POT buzzer function OFF Successful" 0 "No Action Required" ;
VAL_ 436 PotHeightAdjAck 3 "Reserve" 2 "POT User height Selection Successful" 1 "POT User height Selection NOT Successful" 0 "No Action Required" ;
VAL_ 436 BCmHuGotoEntryExitPosAck 3 "Reserved" 2 "Action not required" 1 "Easy Entry Exit function ON Successful" 0 "Easy Entry Exit function OFF Successful" ;
VAL_ 436 BCMRemotePrecheck 3 "Reserved" 2 "BCM Remote AC & Engine Pre-condition check failed." 1 "BCM Remote AC & Engine Pre-condition check passed." 0 "Don't Care" ;
VAL_ 525 PotUidButtonReq 1 "Request from UID Tailgate button" 0 "No request from UID Tailgate button" ;
VAL_ 525 PEPSRemoteCheck 3 "Reserved" 2 "Remote check not successful" 1 "Remote check successful" 0 "Default state / Remote command not requested" ;
VAL_ 525 FotaIgnOnHoldStateAck 3 "Reserved" 2 "Signal received and Ignition ON Held" 1 "Signal not received or Ignition not held" 0 "No Action required" ;
VAL_ 639 EMsHuBatteryVrCmdSupport 1 "Battery VC feature is supported" 0 "Battery VC feature is not supported" ;
VAL_ 639 EMsHuBatteryVrCmdAck 7 "Reserved" 6 "Reserved" 5 "Battery is in learning state" 4 "Replace the Battery" 3 "Battery is moderate, Charging is required." 2 "Battery is moderate" 1 "Battery is healthy, Charging is required" 0 "Battery is healthy" ;
VAL_ 639 EMsHuBatteryVrCmdAckStatus 3 "Not Supported " 2 "Value is implausible" 1 "Reserved for future use" 0 "Value is correct and according to specification" ;
VAL_ 639 EMsHuDPfRegenAckStatus 3 "Not Supported / Signal Not Available" 2 "Signal is implausible" 1 "Reserved for future use" 0 "Signal is Correct" ;
VAL_ 639 EMsHuDPfRegenAck 7 "Reserved" 6 "Reserved" 5 "Pre-conditions Met for DPF Regeneration" 4 "DPFRegen aborted due to error / interrupts / time out." 3 "DPFRegen completed. Faults cleared." 2 "DPFRegen started." 1 "DPFRegen is requested by user, Pre-condition NOT met." 0 "No DPFRegen Request " ;
VAL_ 639 DPfRegenEnableState 3 "Reserved" 2 "Maximum soot Limit detected, DPF Regen through HMI Disabled" 1 "DPF lamp ON,  DPF Regen Allowed through HMI" 0 "DPF Regen NOT allowed through HMI" ;
VAL_ 639 EMsHuDPfRegenHMI 3 "Reserved" 2 "Reserved" 1 "DPF regeneration  Supported by HU" 0 "DPF regeneration Not Supported by HU" ;
VAL_ 496 FotaIgnOnHoldState 3 "Reserved" 2 "Ignition to be held at ON state" 1 "Ignition not to be held at ON state" 0 "No Action required" ;
VAL_ 496 FotaUserReConfirmAck 1 "Acknowledgement from TCU for FOTA User Re-Confirmation Information reception " 0 "No Action required / No Acknowledgement " ;
VAL_ 496 FotaUserConfirmAck 1 "Acknowledgement from TCU for FOTA User Confirmation Information reception " 0 "No Action required / No Acknowledgement " ;
VAL_ 496 FotaEcuId 7 "BCM, FATC & VCU" 6 "FATC & VCU" 5 "BCM & VCU" 4 "VCU" 3 "BCM & FATC" 2 "FATC" 1 "BCM" 0 "Default" ;
VAL_ 496 FotaUpdateType 7 "Reserved" 6 "Reserved" 5 "Reserved" 4 "Critical Update (Forced Update)" 3 "Security Update" 2 "Bug Fix" 1 "Feauture Enhancement" 0 "No update Available" ;
VAL_ 584 BatteryCoolingSolValveState 3 "Reserved" 2 "Battery Cooling SV is ON" 1 "Reserved" 0 "Battery Cooling SV is OFF" ;
VAL_ 354 TorqueReductionRequestStatus 3 "Signal Not available" 2 "Information given  is implausible" 1 "Reserved for future use" 0 "Information given is correct and according to specification" ;
VAL_ 354 TorqueReductionRequest 2047 "Signal Invalid" ;
VAL_ 354 AutoLockModeState 7 "Signal Invalid" 6 "Reserved" 5 "Reserved" 4 "LOCK MODE" 3 "AUTO MODE" 2 "Reserved" 1 "Reserved" 0 "Default Value" ;
VAL_ 354 CAnBusFault 1 "ON" 0 "Off/default" ;
VAL_ 354 TorqueOutputStatus 3 "Signal Not available" 2 "Information given  is implausible" 1 "Reserved for future use" 0 "Information given is correct and according to specification" ;
VAL_ 354 TorqueOutput 2047 "Signal Invalid" ;
VAL_ 728 DustSensorOperation 3 "Invalid" 2 "Error" 1 "Dust Sensor Disable" 0 "Dust Sensor Enable" ;
VAL_ 728 DustSensorButtonOnOff 3 "Invalid 2" 2 "Invalid 1" 1 "Dust Sensor OFF" 0 "Dust Sensor ON" ;
VAL_ 728 CCmHuDustConcentrationStatus 3 "Signal Not Available" 2 "Implausible/Error" 1 "Initialisation" 0 "Plausible" ;
VAL_ 728 CCmHuAqiLevel 7 "Reserved" 6 "Reserved" 5 "Severe" 4 "Very Poor" 3 "Poor" 2 "Moderate" 1 "Satisfactory" 0 "Good" ;
VAL_ 728 CCmHuDominantPollutantValue 15 "Reserved" 14 "Reserved" 13 "Reserved" 12 "Reserved" 11 "Reserved" 10 "Reserved" 9 "Reserved" 8 "Reserved" 7 "Reserved" 6 "Reserved" 5 "Reserved" 4 "NH3" 3 "CO" 2 "NOX" 1 "PM2.5" 0 "SNA(Signal not available)" ;
VAL_ 728 CCmHuAqiValueStatus 3 "Signal Not Available" 2 "Implausible/Error" 1 "Initialisation" 0 "Plausible" ;
VAL_ 728 CCmHuAqiAutolearning 1 "Feature present" 0 "Feature not present" ;
VAL_ 275 DriverReqTrqStatus 3 "Reserved" 2 "Information given by DriverReqTrq is implausible" 1 "Reserved" 0 "Information given by DriverReqTrq is correct and according to specification" ;
VAL_ 275 RecupBrakeState 1 "Recupration Enable" 0 "Recupration Disable" ;
VAL_ 275 MaxAvailableRegenTrqStatus 3 "Reserved for future use" 2 "Information given by MaxAvailableRegenTrq is implausible" 1 "Reserved for future use" 0 "Information given by MaxAvailableRegenTrq is correct and according to specification" ;
VAL_ 736 VehicleMobilizationStateStatus 3 "Signal  Not Available" 2 "Signal is Implausible" 1 "Reserved for future use" 0 "Plausible-Information is correct" ;
VAL_ 736 VehicleMobilizationState 3 "Reserved for future use" 2 "Immobilised by TCU" 1 "Mobilised by TCU" 0 "Reserved for future use" ;
VAL_ 467 HuBCmGotoEntryExitPos 3 "Reserved" 2 "Action not required" 1 "Easy Entry Exit function ON" 0 "Easy Entry Exit function OFF" ;
VAL_ 467 HuEMsBatteryVrCmdReq 1 "Battery status is requested " 0 "Battery status not requested" ;
VAL_ 467 HuVoiceCommandDataStatus 7 "Reserved" 6 "Reserved" 5 "Reserved" 4 "Reserved" 3 "Request" 2 "Data not received" 1 "Plausible" 0 "No Action required" ;
VAL_ 467 FotaInstallUserReconfirmReq 7 "Reserved" 6 "Reserved" 5 "Reserved" 4 "Reserved" 3 "Reserved" 2 "Installation Request Postponed" 1 "Installation Request Accepted" 0 "User Input Not Available" ;
VAL_ 467 FotaInstallUserConfirmation 7 "Reserved" 6 "Reserved" 5 "Reserved" 4 "Reserved" 3 "Installation Request Ignored" 2 "Installation Request Postponed" 1 "Installation Request Accepted" 0 "User Input Not Available" ;
VAL_ 467 FotaHmiReqAck 1 "Acknowledgement from HU for FOTA Update Information reception " 0 "No Action required / No Acknowledgement " ;
VAL_ 467 VoiceCommandReq 15 "Reserved" 14 "Reserved" 13 "Reserved" 12 "Reserved" 11 "Reserved" 10 "Reserved" 9 "Insurance expiry Date & KM" 8 "Insurance expiry Date" 7 "Insurance expiry KM" 6 "Registration No" 5 "Get VIN" 4 "Purchase Date" 3 "Last service Date & KM" 2 "Last service Date" 1 "Last service KM" 0 "No Intent / No Action required" ;
VAL_ 467 SharingTimeDuration 7 "Reserved" 6 "Reserved" 5 "5 Hrs" 4 "2 Hrs" 3 "1 Hr" 2 "30 mins" 1 "15 mins" 0 "Not Applicable/No Action required" ;
VAL_ 467 SharedLocationReq 3 "Reserved" 2 "Live Location sharing request " 1 "Current Location sharing Request" 0 "No sharing Location Request/No Action required" ;
VAL_ 467 CommunityHelpReq 15 "Reserved" 14 "Reserved" 13 "Reserved" 12 "Reserved" 11 "Reserved" 10 "Reserved" 9 "Reserved" 8 "Community Help requested for Low Fuel." 7 "Community Help requested for Low SOC." 6 "Community Help requested for Tire puncture. " 5 "Community Help requested for Towing." 4 "Community Help requested for Medical issue." 3 "Community Help requested for Accident." 2 "Community Help requested for Vehicle Breakdown." 1 "Community Help cancel" 0 "No Action required" ;
VAL_ 583 CruiseSwitchStateVCUStatus 3 "Signal not available" 2 "Value is implausible " 1 "Reserved for future use" 0 "Signal is correct" ;
VAL_ 583 CruiseSwitchStateVCU 3 "Invalid Key Pressed" 2 "Set / Cruise Spd - Key pressed" 1 "Resume / Cruise Spd+ Key pressed" 0 "No Key ( Resume/Cruise Speed+  && Set/Cruise Speed - ) pressed" ;
VAL_ 583 VcuModeSelectionChangeTxt 3 "Signal not available" 2 "Failure in Mode Selector" 1 "Mode Selections not possible" 0 "Mode Selections possible" ;
VAL_ 583 ModeForDisplayVCUStatus 3 "Signal Not Available" 2 "Information given is implausible due to a detected failure " 1 "Reserved" 0 "Information given correct and according to specification" ;
VAL_ 583 ModeForDisplayVCU 7 "Information Initialization in progress" 6 "Reserved" 5 "Reserved" 4 "Reserved" 3 "Reserved" 2 "Sport" 1 "Eco" 0 "City" ;
VAL_ 583 ModeSelectionSwStateVCUStatus 3 "Reserved" 2 "Information given is implausible due to a detected failure " 1 "Reserved" 0 "Information given correct and according to specification" ;
VAL_ 583 ModeSelectionSwStateVCU 7 "Reserved" 6 "Reserved" 5 "Reserved" 4 "Reserved" 3 "Reserved" 2 "Sport" 1 "Eco" 0 "City" ;
VAL_ 583 VcuRegenSelectionChangeTxt 3 "Regen Level Min Limit Reached" 2 "Regen Level Max Limit Reached" 1 "Regen Level Selections not possible" 0 "Regen Level Selections possible" ;
VAL_ 583 RegenForDisplayVCUStatus 3 "Signal Not Available" 2 "Information given is implausible due to a detected failure " 1 "Reserved" 0 "Information given correct and according to specification" ;
VAL_ 583 RegenForDisplayVCU 7 "Information Initialization in progress" 6 "Reserved" 5 "Reserved" 4 "Reserved" 3 "Level 3" 2 "Level 2" 1 "Level 1" 0 "Level 0" ;
VAL_ 583 VcuCruiseSelectionChangeTxt 8 "Min Speed Limit Reached" 7 "Max Speed Limit Reached" 6 "Cruise Selections not possible" 5 "Cruise Control Overide" 4 "Cruise Cancelled" 3 "Cruise Resumed" 2 "Cruise Activated" 1 "Cruise ON" 0 "Cruise OFF" ;
VAL_ 583 DesiredCruiseSpeedStatus 3 "Signal Not available" 2 "Information given  is implausible" 1 "Reserved" 0 "Information given i correct and according to specification" ;
VAL_ 583 VCuCruiseStateStatus 3 "Signal Not Available" 2 "Information given is implausible due to a detected failure " 1 "Reserved" 0 "Information given correct and according to specification" ;
VAL_ 583 VCuCruiseState 7 "Information Initialization in progress" 6 "Reserved" 5 "Reserved" 4 "Reserved" 3 "Reserved" 2 "Cruise is enabled and not active" 1 "Cruise is enabled and active" 0 "Cruise is disabled" ;
VAL_ 583 HvBattFullChargeStatus 4 "Reserved" 2 "Information given is implausible due to a detected failure " 1 "Reserved" 0 "Information given correct and according to specification" ;
VAL_ 583 HvBattFullCharge 1 "HV Battery  fully charged" 0 "HV Battery Not fully charged" ;
VAL_ 741 RemoteAcPvTempSetStatus 3 "Signal Not Available" 2 "Signal is Implausible" 1 "Don’t Care" 0 "Plausible - Information given is correct and according to specification" ;
VAL_ 741 RemoteAcPvTempSet 31 "HI" 30 "Reserved" 29 "30" 28 "29.5" 27 "29" 26 "28.5" 25 "28" 24 "27.5" 23 "27" 22 "26.5" 21 "26" 20 "25.5" 19 "25" 18 "24.5" 17 "24" 16 "23.5" 15 "23" 14 "22.5" 13 "22" 12 "21.5" 11 "21" 10 "20.5" 9 "20" 8 "19.5" 7 "19" 6 "18.5" 5 "18" 4 "LO" 3 "Reserved" 2 "Reserved" 1 "Reserved" 0 "Reserved" ;
VAL_ 741 VehicleChargingStateTCM 3 "Reserved" 2 "Not Meeting Requirement" 1 "Meeting Requirement" 0 "Error" ;
VAL_ 741 RemoteEngAcCmdStatus 3 "Signal not available" 2 "Signal is implausible" 1 "Reserved for future use." 0 "Signal is correct" ;
VAL_ 741 RemoteEngAcCmd 3 "Remote AC Start is Active" 2 "Default state with Normal Running mode ON" 1 "Remote Engine Start is Active" 0 "Remote AC & Engine Signal is not Active" ;
VAL_ 741 TCmPresence 1 "Reserved" 0 "TCM is present" ;
VAL_ 741 VcuFotaUpdateState 3 "Update Completed" 2 "Update In Progress" 1 "Update Pending" 0 "No Update" ;
VAL_ 741 FatcFotaUpdateState 3 "Update Completed" 2 "Update In Progress" 1 "Update Pending" 0 "No Update" ;
VAL_ 741 BcmFotaUpdateState 3 "Update Completed" 2 "Update In Progress" 1 "Update Pending" 0 "No Update" ;
VAL_ 741 ParkBrkStateTcm 3 "Reserved" 2 "Not Meeting Requirement" 1 "Meeting Requirement" 0 "Error" ;
VAL_ 741 GearPosStateTcm 3 "Reserved" 2 "Not Meeting Requirement" 1 "Meeting Requirement" 0 "Error" ;
VAL_ 741 LvBattVoltStateTcm 3 "Reserved" 2 "Not Meeting Requirement" 1 "Meeting Requirement" 0 "Error" ;
VAL_ 741 EngRpmStateTcm 3 "Reserved" 2 "Not Meeting Requirement" 1 "Meeting Requirement" 0 "Error" ;
VAL_ 741 VehSpdStateTcm 3 "Reserved" 2 "Not Meeting Requirement" 1 "Meeting Requirement" 0 "Error" ;
VAL_ 741 IgnStateTcm 3 "Reserved" 2 "Not Meeting Requirement" 1 "Meeting Requirement" 0 "Error" ;
VAL_ 741 AccPedalPosStateTcm 3 "Reserved" 2 "Not Meeting Requirement" 1 "Meeting Requirement" 0 "Error" ;
VAL_ 741 FotaUpdateState 15 "IgnitionRecycle" 14 "Reserved" 13 "Reserved" 12 "NoActionRequired" 11 "UpdateAborted" 10 "RollbackFailed" 9 "RollbackSuccessful" 8 "RollbackInProgress (InstallationFailed)" 7 "ReInstallationInProgress" 6 "InstallationSuccessful" 5 "InstallationInProgress" 4 "UserReConfirm" 3 "InstallPreConditionCheck " 2 "WaitingUserConfirm" 1 "ReadyToInstall" 0 "Default" ;
VAL_ 741 ShareMyLocationFeaturePresence 1 "Feature Present" 0 "Feature Not Present" ;
VAL_ 741 iCallFeaturePresence 1 "Feature Present" 0 "Feature Not Present" ;
VAL_ 741 eCallFeaturePresence 1 "Feature Present" 0 "Feature Not Present" ;
VAL_ 741 CvpVoiceCmdFeaturePresence 1 "Feature Present" 0 "Feature Not Present" ;
VAL_ 741 CommunityHelpFeaturePresence 1 "Feature Present" 0 "Feature Not Present" ;
VAL_ 741 CallType 3 "iCall" 2 "bCall" 1 "eCall" 0 "No Call" ;
VAL_ 741 CallState 3 "Call Ended" 2 "Call in process" 1 "Call Initiated" 0 "No Call" ;
VAL_ 741 bCallFeaturePresence 1 "Feature Present" 0 "Feature Not Present" ;
VAL_ 378 MotorTrqLimFastStatus 3 "Signal MotorTrqLimFast not available" 2 "information given at MotorTrqLimFast is implausible due to a detected failure at brake system" 1 "information given at MotorTrqLimFast is correct and and TCS/ESP intervention is active. Torque intervention requested." 0 "infomation given at MotorTrqLimFast is correct but TCS/ESP intervention not active. No torque intervention requested." ;
VAL_ 378 MotorTrqIncStatus 3 "Signal MotorTrqInc not available" 2 "Information given at MotorTrqInc is implausible due to a detected failure at brake system." 1 "Information given at MotorTrqInc is correct and according to specification and Torque intervention requested." 0 "Information given at MotorTrqInc is correct and according to specification, No torque intervention requested." ;
VAL_ 673 DustSensorConcentrationStatus 3 "Signal Not Available ( Feature is Absent)" 2 "Implausible" 1 "Reserved" 0 "Plausible" ;
VAL_ 673 DustSensorTempError 3 "Invalid 2" 2 "Invalid 1" 1 "Error in Sensor Temperature" 0 "NO Error in sensor temperature" ;
VAL_ 673 DustSensorTempOverHeat 3 "Invalid 2" 2 "Invalid 1" 1 "Dust Sensor Temp Overheated" 0 "Dust Sensor Temp not Overheated" ;
VAL_ 673 DustSensorState 3 "Invalid 2" 2 "Invalid 1" 1 "Dust Sensor OFF" 0 "Dust Sensor is ON" ;
VAL_ 673 DustSensorSensorChange 3 "Invalid 2" 2 "Invalid 1" 1 "Change" 0 "No Change" ;
VAL_ 673 DustSensorMotorError 3 "Invalid 2" 2 "Invalid 1" 1 "Error" 0 "No Error" ;
VAL_ 673 DustSensorInitialization 3 "Invalid 2" 2 "Invalid 1" 1 "Initilisation In Progress" 0 "Initilisation Finish" ;
VAL_ 673 DustSensorHighTempMode 3 "Invalid 2" 2 "Invalid 1" 1 "High Temperature Mode is Activated" 0 "High Temperature Mode is Not activated" ;
VAL_ 673 WirelessChargerPresence 1 "Present" 0 "Not Present" ;
VAL_ 673 WcdutycycleStatus 3 "Signal Not Avilable" 2 "Wcdutycycle signal value is implausible" 1 "Reserved for Future" 0 "Wcdutycycle signal value is plausible" ;
VAL_ 491 HuBCmWindowWindingHmiCmdSupportA 1 "Supported" 0 "Not Supported" ;
VAL_ 491 HuBCmTyreTempVrCmdSupportAck 1 "Supported" 0 "Not Supported" ;
VAL_ 491 HuBCmTyreTempHmiCmdSupportAck 1 "Supported" 0 "Not Supported" ;
VAL_ 491 HuBCmTyrePressureVrCmdSupportAck 1 "Supported" 0 "Not Supported" ;
VAL_ 491 HuBCmTyrePressureHmiCmdSupportAc 1 "Supported" 0 "Not Supported" ;
VAL_ 491 HuBCmSunroofTiltVrCmdSupportAck 1 "Supported" 0 "Not Supported" ;
VAL_ 491 HuBCmRoofLampVrCmdSupportAck 1 "Supported" 0 "Not Supported" ;
VAL_ 491 HuBCmRoofLampHmiCmdSupportAck 1 "Supported" 0 "Not Supported" ;
VAL_ 491 HuBCmPositionLampVrCmdSupportAck 1 "Supported" 0 "Not Supported" ;
VAL_ 491 HuBCmORVMVrCmdSupportAck 1 "Supported" 0 "Not Supported" ;
VAL_ 491 HuBCmORVMHmiCmdSupportAck 1 "Supported" 0 "Not Supported" ;
VAL_ 491 HuBCmMoodLightVrCmdSupportAck 1 "Supported" 0 "Not Supported" ;
VAL_ 491 HuBCmHazardLampVrCmdSupportAck 1 "Supported" 0 "Not Supported" ;
VAL_ 491 HuBCmDRLVrCmdSupportAck 1 "Supported" 0 "Not Supported" ;
VAL_ 491 HuBCmAmbientLightVrCmdSupportAck 1 "Supported" 0 "Not Supported" ;
VAL_ 491 HuBCmSunShadeVrCmdSupportAck 1 "Supported" 0 "Not Supported" ;
VAL_ 491 HuBCmSunRoofVrCmdSupportAck 1 "Supported" 0 "Not Supported" ;
VAL_ 461 HuBCmWindowWindingHmiCmdReq 15 "Reserved" 14 "Reserved" 13 "Reserved" 12 "Reserved" 11 "Reserved" 10 "Rear Left Window Open" 9 "Rear Left Window Close" 8 "Rear Right Window Open	" 7 "Rear Right Window Close" 6 "Front Left Window Open" 5 "Front Left Window Close" 4 "Front Right Window Open" 3 "Front Right Window Close" 2 "Window Open" 1 "Window Close" 0 "No Command" ;
VAL_ 461 HuBCmTyreTempHmiVrCmdReq 7 "Reserved" 6 "Spare Tyre Temperature" 5 "Rear Left Tyre Temperature" 4 "Rear Right Tyre Temperature" 3 "Front Left Tyre Temperature" 2 "Front Right Tyre Temperature" 1 "All Tyre Temperature" 0 "No Command" ;
VAL_ 461 HuBCmTyrePressureHmiVrCmdReq 7 "Reserved" 6 "Spare Tyre Pressure" 5 "Rear Left Tyre Pressure" 4 "Rear Right Tyre Pressure" 3 "Front Left Tyre Pressure" 2 "Front Right Tyre Pressure" 1 "All Tyre Pressure" 0 "No Command" ;
VAL_ 461 HuBCmRoofLampHmiVrCmdReq 3 "Query Current State" 2 "ON" 1 "OFF" 0 "No Command" ;
VAL_ 461 HuBCmPositionLampVrCmdReq 3 "Query Current State" 2 "ON" 1 "OFF" 0 "No Command" ;
VAL_ 461 HuBCmORVMHmiVrCmdReq 15 "Reserved" 14 "Reserved" 13 "Reserved" 12 "Third Memory Recall" 11 "Second Memory Recall" 10 "First Memory Recall" 9 "Third Memory Set" 8 "Second Memory Set" 7 "First Memory Set" 6 "Left Mirror Unfold" 5 "Left Mirror Fold" 4 "Right Mirror Unfold" 3 "Right Mirror Fold" 2 "ORVM Unfold" 1 "ORVM Fold" 0 "No Command" ;
VAL_ 461 HuBCmMoodLightVrCmdReq 3 "Query Current State" 2 "ON" 1 "OFF" 0 "No Command" ;
VAL_ 461 HuBCmHazardLampVrCmdReq 3 "Query Current State" 2 "ON" 1 "OFF" 0 "No Command" ;
VAL_ 461 HuBCmDRLVrCmdReq 3 "Query Current State" 2 "ON" 1 "OFF" 0 "No Command" ;
VAL_ 461 HuBCmAmbientLightVrCmdReq 3 "Query Current State" 2 "ON" 1 "OFF" 0 "No Command" ;
VAL_ 461 HuBCmTiltVrCmdReq 3 "Query Current State" 2 "Open" 1 "Close" 0 "No Command" ;
VAL_ 461 HuBCmSunShadeVrCmdReq 3 "Query Current State" 2 "Open" 1 "Close" 0 "No Command" ;
VAL_ 461 HuBCmSunRoofVrCmdReq 3 "Query Current State" 2 "Close" 1 "Open" 0 "No Command" ;
VAL_ 489 BCmHuWindowWindingHmiCmdSupport 1 "Supported" 0 "Not Supported" ;
VAL_ 489 BCmHuTyreTempVrCmdSupport 1 "Supported" 0 "Not Supported" ;
VAL_ 489 BCmHuTyreTempHmiCmdSupport 1 "Supported" 0 "Not Supported" ;
VAL_ 489 BCmHuTyrePressureVrCmdSupport 1 "Supported" 0 "Not Supported" ;
VAL_ 489 BCmHuTyrePressureHmiCmdSupport 1 "Supported" 0 "Not Supported" ;
VAL_ 489 BCmHuSunroofTiltVrCmdSupport 1 "Supported" 0 "Not Supported" ;
VAL_ 489 BCmHuRoofLampVrCmdSupport 1 "Supported" 0 "Not Supported" ;
VAL_ 489 BCmHuRoofLampHmiCmdSupport 1 "Supported" 0 "Not Supported" ;
VAL_ 489 BCmHuPositionLampVrCmdSupport 1 "Supported" 0 "Not Supported" ;
VAL_ 489 BCmHuORVMVrCmdSupport 1 "Supported" 0 "Not Supported" ;
VAL_ 489 BCmHuORVMHmiCmdSupport 1 "Supported" 0 "Not Supported" ;
VAL_ 489 BCmHuMoodLightVrCmdSupport 1 "Supported" 0 "Not Supported" ;
VAL_ 489 BCmHuHazardLampVrCmdSupport 1 "Supported" 0 "Not Supported" ;
VAL_ 489 BCmHuDRLVrCmdSupport 1 "Supported" 0 "Not Supported" ;
VAL_ 489 BCmHuAmbientLightVrCmdSupport 1 "Supported" 0 "Not Supported" ;
VAL_ 489 BCmHuSunShadeVrCmdSupport 1 "Supported" 0 "Not Supported" ;
VAL_ 489 BCmHuSunRoofVrCmdSupport 1 "Supported" 0 "Not Supported" ;
